VERSION ""

NS_ :

BS_:

BU_: L_DHRR_FD L_UWB_BLE_MST_FD L_UWB_RR_FD L_UWB_BLE_SLV_FD L_UWB_FR_FD L_ROA_FR_FD L_ROA_FD L_DHRL_FD L_UWB_TRNK_FD L_UWB_FRNK_FD L_EDT_FD L_UWB_FL_FD GW_BDC_FD L_UWB_RL_FD L_SAL_FD L_WPC_FD L_TPMS_FD L_DHL_FD L_DHR_FD

BO_ 2281701552 L_UWB_BLE_SLV_FD_20_200ms: 24 L_UWB_BLE_SLV_FD
 SG_ L_UWB_BLE_SLV_FD_Crc20Val : 0|16@1+ (1,0) [0|0] "0" Vector__XXX
 SG_ SLV_BLE_ConnectedDeviceInfo : 104|16@1+ (1,0) [0|0] ""  GW_BDC_FD,L_UWB_BLE_MST_FD
 SG_ SLV_BLE_Passive_ADV_State : 121|1@1+ (1,0) [0|0] ""  GW_BDC_FD,L_UWB_BLE_MST_FD
 SG_ SLV_BLE_NewDeviceConnetStatus : 122|2@1+ (1,0) [0|0] ""  GW_BDC_FD,L_UWB_BLE_MST_FD
 SG_ SLV_BLE_PairingResult : 124|2@1+ (1,0) [0|0] ""  GW_BDC_FD,L_UWB_BLE_MST_FD
 SG_ SLV_BLE_BondingDataStatus : 126|16@1+ (1,0) [0|0] ""  GW_BDC_FD,L_UWB_BLE_MST_FD
 SG_ SLV_BLE_InternalStatus : 144|8@1+ (1,0) [0|0] ""  L_EDT_FD,L_UWB_BLE_MST_FD
 SG_ L_UWB_BLE_SLV_FD_AlvCnt20Val : 16|8@1+ (1,0) [0|0] "0" Vector__XXX
 SG_ SLV_BLE_DK_ID1 : 24|8@1+ (1,0) [0|0] ""  GW_BDC_FD
 SG_ SLV_BLE_RSSI1 : 32|8@1+ (1,0) [0|0] ""  GW_BDC_FD
 SG_ SLV_BLE_DK_ID2 : 40|8@1+ (1,0) [0|0] ""  GW_BDC_FD
 SG_ SLV_BLE_RSSI2 : 48|8@1+ (1,0) [0|0] ""  GW_BDC_FD
 SG_ SLV_BLE_DK_ID3 : 56|8@1+ (1,0) [0|0] ""  GW_BDC_FD
 SG_ SLV_BLE_RSSI3 : 64|8@1+ (1,0) [0|0] ""  GW_BDC_FD
 SG_ SLV_BLE_DK_ID4 : 72|8@1+ (1,0) [0|0] ""  GW_BDC_FD
 SG_ SLV_BLE_RSSI4 : 80|8@1+ (1,0) [0|0] ""  GW_BDC_FD
 SG_ SLV_BLE_BTAddIRK_Update : 88|16@1+ (1,0) [0|0] ""  GW_BDC_FD,L_UWB_BLE_MST_FD

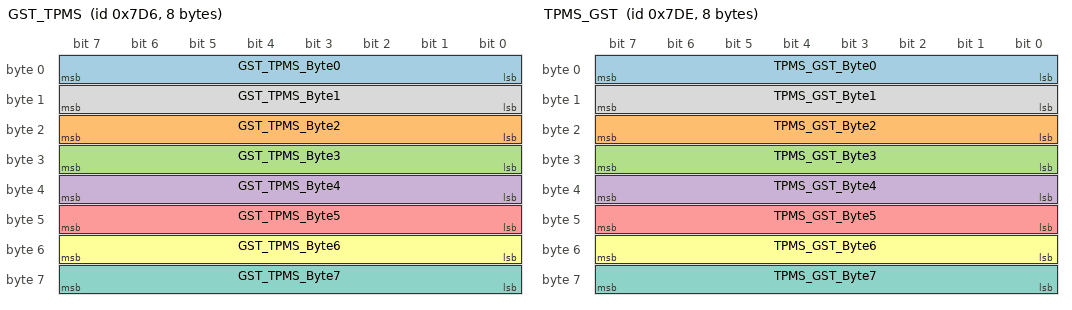
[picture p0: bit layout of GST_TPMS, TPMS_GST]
BO_ 2006 GST_TPMS: 8 GW_BDC_FD
 SG_ GST_TPMS_Byte0 : 0|8@1+ (1,0) [0|0] ""  L_TPMS_FD
 SG_ GST_TPMS_Byte2 : 16|8@1+ (1,0) [0|0] ""  L_TPMS_FD
 SG_ GST_TPMS_Byte3 : 24|8@1+ (1,0) [0|0] ""  L_TPMS_FD
 SG_ GST_TPMS_Byte4 : 32|8@1+ (1,0) [0|0] ""  L_TPMS_FD
 SG_ GST_TPMS_Byte5 : 40|8@1+ (1,0) [0|0] ""  L_TPMS_FD
 SG_ GST_TPMS_Byte6 : 48|8@1+ (1,0) [0|0] ""  L_TPMS_FD
 SG_ GST_TPMS_Byte7 : 56|8@1+ (1,0) [0|0] ""  L_TPMS_FD
 SG_ GST_TPMS_Byte1 : 8|8@1+ (1,0) [0|0] ""  L_TPMS_FD

BO_ 2014 TPMS_GST: 8 L_TPMS_FD
 SG_ TPMS_GST_Byte0 : 0|8@1+ (1,0) [0|0] ""  GW_BDC_FD
 SG_ TPMS_GST_Byte2 : 16|8@1+ (1,0) [0|0] ""  GW_BDC_FD
 SG_ TPMS_GST_Byte3 : 24|8@1+ (1,0) [0|0] ""  GW_BDC_FD
 SG_ TPMS_GST_Byte4 : 32|8@1+ (1,0) [0|0] ""  GW_BDC_FD
 SG_ TPMS_GST_Byte5 : 40|8@1+ (1,0) [0|0] ""  GW_BDC_FD
 SG_ TPMS_GST_Byte6 : 48|8@1+ (1,0) [0|0] ""  GW_BDC_FD
 SG_ TPMS_GST_Byte7 : 56|8@1+ (1,0) [0|0] ""  GW_BDC_FD
 SG_ TPMS_GST_Byte1 : 8|8@1+ (1,0) [0|0] ""  GW_BDC_FD

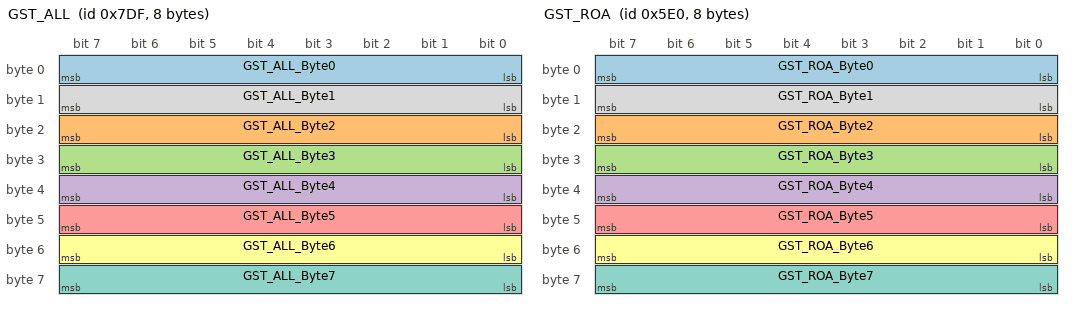
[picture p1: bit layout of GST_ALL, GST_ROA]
BO_ 2015 GST_ALL: 8 GW_BDC_FD
 SG_ GST_ALL_Byte0 : 0|8@1+ (1,0) [0|0] ""  L_DHL_FD,L_DHRL_FD,L_DHRR_FD,L_DHR_FD,L_ROA_FD,L_ROA_FR_FD,L_SAL_FD,L_UWB_BLE_MST_FD,L_WPC_FD
 SG_ GST_ALL_Byte2 : 16|8@1+ (1,0) [0|0] ""  L_DHL_FD,L_DHRL_FD,L_DHRR_FD,L_DHR_FD,L_ROA_FD,L_ROA_FR_FD,L_SAL_FD,L_UWB_BLE_MST_FD,L_WPC_FD
 SG_ GST_ALL_Byte3 : 24|8@1+ (1,0) [0|0] ""  L_DHL_FD,L_DHRL_FD,L_DHRR_FD,L_DHR_FD,L_ROA_FD,L_ROA_FR_FD,L_SAL_FD,L_UWB_BLE_MST_FD,L_WPC_FD
 SG_ GST_ALL_Byte4 : 32|8@1+ (1,0) [0|0] ""  L_DHL_FD,L_DHRL_FD,L_DHRR_FD,L_DHR_FD,L_ROA_FD,L_ROA_FR_FD,L_SAL_FD,L_UWB_BLE_MST_FD,L_WPC_FD
 SG_ GST_ALL_Byte5 : 40|8@1+ (1,0) [0|0] ""  L_DHL_FD,L_DHRL_FD,L_DHRR_FD,L_DHR_FD,L_ROA_FD,L_ROA_FR_FD,L_SAL_FD,L_UWB_BLE_MST_FD,L_WPC_FD
 SG_ GST_ALL_Byte6 : 48|8@1+ (1,0) [0|0] ""  L_DHL_FD,L_DHRL_FD,L_DHRR_FD,L_DHR_FD,L_ROA_FD,L_ROA_FR_FD,L_SAL_FD,L_UWB_BLE_MST_FD,L_WPC_FD
 SG_ GST_ALL_Byte7 : 56|8@1+ (1,0) [0|0] ""  L_DHL_FD,L_DHRL_FD,L_DHRR_FD,L_DHR_FD,L_ROA_FD,L_ROA_FR_FD,L_SAL_FD,L_UWB_BLE_MST_FD,L_WPC_FD
 SG_ GST_ALL_Byte1 : 8|8@1+ (1,0) [0|0] ""  L_DHL_FD,L_DHRL_FD,L_DHRR_FD,L_DHR_FD,L_ROA_FD,L_ROA_FR_FD,L_SAL_FD,L_UWB_BLE_MST_FD,L_WPC_FD

BO_ 2525339905 L_UWB_FL_FD_05_00ms: 32 L_UWB_FL_FD
 SG_ L_UWB_FL_FD_Crc5Val : 0|16@1+ (1,0) [0|0] "" Vector__XXX
 SG_ L_UWB_FL_FD_AlvCnt5Val : 16|8@1+ (1,0) [0|0] "" Vector__XXX
 SG_ FL_SWID_3_IVD_2 : 24|24@1+ (1,0) [0|0] ""  L_UWB_BLE_MST_FD

BO_ 2281701536 L_UWB_BLE_MST_FD_20_200ms: 24 L_UWB_BLE_MST_FD
 SG_ L_UWB_BLE_MST_FD_Crc20Val : 0|16@1+ (1,0) [0|0] "0" Vector__XXX
 SG_ MST_BLE_ConnectedDeviceInfo : 104|16@1+ (1,0) [0|0] ""  GW_BDC_FD,L_UWB_BLE_SLV_FD
 SG_ MST_BLE_OP_ADV_State : 120|1@1+ (1,0) [0|0] ""  GW_BDC_FD,L_UWB_BLE_SLV_FD
 SG_ MST_BLE_Passive_ADV_State : 121|1@1+ (1,0) [0|0] ""  GW_BDC_FD,L_UWB_BLE_SLV_FD
 SG_ MST_BLE_NewDeviceConnetStatus : 122|2@1+ (1,0) [0|0] ""  GW_BDC_FD,L_UWB_BLE_SLV_FD
 SG_ MST_BLE_PairingResult : 124|2@1+ (1,0) [0|0] ""  GW_BDC_FD,L_UWB_BLE_SLV_FD
 SG_ MST_BLE_BondingDataStatus : 126|16@1+ (1,0) [0|0] ""  GW_BDC_FD,L_UWB_BLE_SLV_FD
 SG_ MST_BLE_InternalStatus : 144|8@1+ (1,0) [0|0] ""  L_EDT_FD,L_UWB_BLE_SLV_FD
 SG_ MST_Vehicle_Info : 152|40@1+ (1,0) [0|0] ""  L_UWB_BLE_SLV_FD,L_UWB_FL_FD,L_UWB_FRNK_FD,L_UWB_FR_FD,L_UWB_RL_FD,L_UWB_RR_FD,L_UWB_TRNK_FD
 SG_ L_UWB_BLE_MST_FD_AlvCnt20Val : 16|8@1+ (1,0) [0|0] "0" Vector__XXX
 SG_ MST_BLE_DK_ID1 : 24|8@1+ (1,0) [0|0] ""  GW_BDC_FD
 SG_ MST_BLE_RSSI1 : 32|8@1+ (1,0) [0|0] ""  GW_BDC_FD
 SG_ MST_BLE_DK_ID2 : 40|8@1+ (1,0) [0|0] ""  GW_BDC_FD
 SG_ MST_BLE_RSSI2 : 48|8@1+ (1,0) [0|0] ""  GW_BDC_FD
 SG_ MST_BLE_DK_ID3 : 56|8@1+ (1,0) [0|0] ""  GW_BDC_FD
 SG_ MST_BLE_RSSI3 : 64|8@1+ (1,0) [0|0] ""  GW_BDC_FD
 SG_ MST_BLE_DK_ID4 : 72|8@1+ (1,0) [0|0] ""  GW_BDC_FD
 SG_ MST_BLE_RSSI4 : 80|8@1+ (1,0) [0|0] ""  GW_BDC_FD
 SG_ MST_BLE_BTAddIRK_Update : 88|16@1+ (1,0) [0|0] ""  GW_BDC_FD,L_UWB_BLE_SLV_FD

BO_ 426 CLU_01_20ms: 16 GW_BDC_FD
 SG_ CLU_Crc1Val : 0|16@1+ (1,0) [0|0] "" Vector__XXX
 SG_ CLU_FuelSenderRstReq : 110|2@1+ (1,0) [0|0] "" Vector__XXX
 SG_ CLU_AlvCnt1Val : 16|8@1+ (1,0) [0|0] "" Vector__XXX
 SG_ CLU_DtntOutSta : 28|2@1+ (1,0) [0|0] "" Vector__XXX
 SG_ CLU_SpdUnitTyp : 30|2@1+ (1,0) [0|0] "" Vector__XXX
 SG_ CLU_DisSpdDcmlVal : 32|2@1+ (0.125,0) [0|0] "" Vector__XXX
 SG_ CLU_SWRCCrsMainSwSta : 34|2@1+ (1,0) [0|0] "" Vector__XXX
 SG_ CLU_SWRCCrsSwSta : 36|3@1+ (1,0) [0|0] "" Vector__XXX
 SG_ CLU_SWRCLFASwSta : 39|2@1+ (1,0) [0|0] "" Vector__XXX
 SG_ CLU_SWRCSldMainSwSta : 41|2@1+ (1,0) [0|0] "" Vector__XXX
 SG_ CLU_RhstaLvlSta : 43|5@1+ (1,0) [0|0] "" Vector__XXX
 SG_ CLU_DisSpdVal : 48|10@1+ (0.5,0) [0|0] "km/h or MPH" Vector__XXX
 SG_ CLU_OKSwSta : 62|2@1+ (1,0) [0|0] "" Vector__XXX
 SG_ CLU_DisSpdVal_KPH : 64|9@1+ (1,0) [0|0] "km/h"  L_DHL_FD,L_DHRL_FD,L_DHRR_FD,L_DHR_FD,L_EDT_FD
 SG_ CLU_PwrAutoOffResetReq_HCU : 73|2@1+ (1,0) [0|0] "" Vector__XXX
 SG_ CLU_CUSTOMSta_NEW : 75|4@1+ (1,0) [0|0] "" Vector__XXX
 SG_ CLU_AutoBrightSta : 79|8@1+ (1,0) [0|0] "" Vector__XXX
 SG_ CLU_NotMinModeBrightSta : 87|8@1+ (1,0) [0|0] "" Vector__XXX
 SG_ CLU_FuelSenderResistVal : 97|13@1+ (0.1,0) [0|0] "" Vector__XXX

BO_ 2281701537 L_UWB_BLE_MST_FD_21_200ms: 24 L_UWB_BLE_MST_FD
 SG_ L_UWB_BLE_MST_FD_Crc21Val : 0|16@1+ (1,0) [0|0] "0" Vector__XXX
 SG_ MST_SW_MCU_Ver_Major : 104|8@1+ (1,0) [0|0] ""  L_EDT_FD
 SG_ MST_SW_MCU_Ver_Minor : 112|8@1+ (1,0) [0|0] ""  L_EDT_FD
 SG_ MST_SW_UWB_Ver_Major : 120|8@1+ (1,0) [0|0] ""  L_EDT_FD
 SG_ MST_SW_UWB_Ver_Minor : 128|8@1+ (1,0) [0|0] ""  L_EDT_FD
 SG_ MST_SW_BLE_Ver_Major : 136|8@1+ (1,0) [0|0] ""  L_EDT_FD
 SG_ MST_SW_BLE_Ver_Minor : 144|8@1+ (1,0) [0|0] ""  L_EDT_FD
 SG_ MST_UWB_DK_LocalizationStat : 152|2@1+ (1,0) [0|0] ""  GW_BDC_FD
 SG_ L_UWB_BLE_MST_FD_AlvCnt21Val : 16|8@1+ (1,0) [0|0] "0" Vector__XXX
 SG_ UWB_Applied_Info : 160|16@1+ (1,0) [0|0] ""  GW_BDC_FD
 SG_ MST_SW_UWB_2_Ver_Major : 176|8@1+ (1,0) [0|0] ""  L_EDT_FD
 SG_ MST_SW_UWB_2_Ver_Minor : 184|8@1+ (1,0) [0|0] ""  L_EDT_FD
 SG_ MST_UWB_Status1 : 24|4@1+ (1,0) [0|7] ""  GW_BDC_FD
 SG_ MST_UWB_Status2 : 28|4@1+ (1,0) [0|0] ""  GW_BDC_FD
 SG_ MST_UWB_Status3 : 32|4@1+ (1,0) [0|0] ""  GW_BDC_FD
 SG_ MST_UWB_Status4 : 36|4@1+ (1,0) [0|0] ""  GW_BDC_FD
 SG_ MST_UWB_Status5 : 40|4@1+ (1,0) [0|0] ""  GW_BDC_FD
 SG_ MST_UWB_Status6 : 44|4@1+ (1,0) [0|0] ""  GW_BDC_FD
 SG_ MST_UWB_Status7 : 48|4@1+ (1,0) [0|0] ""  GW_BDC_FD
 SG_ MST_UWB_Status8 : 52|4@1+ (1,0) [0|0] ""  GW_BDC_FD
 SG_ MST_UWB_Status9 : 56|4@1+ (1,0) [0|0] ""  GW_BDC_FD
 SG_ MST_UWB_Status10 : 60|4@1+ (1,0) [0|0] ""  GW_BDC_FD
 SG_ MST_UWB_Status11 : 64|4@1+ (1,0) [0|0] ""  GW_BDC_FD
 SG_ MST_UWB_Status12 : 68|4@1+ (1,0) [0|0] ""  GW_BDC_FD
 SG_ MST_UWB_Status13 : 72|4@1+ (1,0) [0|0] ""  GW_BDC_FD
 SG_ MST_UWB_Status14 : 76|4@1+ (1,0) [0|0] ""  GW_BDC_FD
 SG_ MST_UWB_Status15 : 80|4@1+ (1,0) [0|0] ""  GW_BDC_FD
 SG_ MST_UWB_Status16 : 84|4@1+ (1,0) [0|0] ""  GW_BDC_FD
 SG_ MST_HW_Ver_Major : 88|8@1+ (1,0) [0|7] ""  L_EDT_FD
 SG_ MST_HW_Ver_Minor : 96|8@1+ (1,0) [0|0] ""  L_EDT_FD

BO_ 1504 GST_ROA: 8 GW_BDC_FD
 SG_ GST_ROA_Byte0 : 0|8@1+ (1,0) [0|0] ""  L_ROA_FD
 SG_ GST_ROA_Byte2 : 16|8@1+ (1,0) [0|0] ""  L_ROA_FD
 SG_ GST_ROA_Byte3 : 24|8@1+ (1,0) [0|0] ""  L_ROA_FD
 SG_ GST_ROA_Byte4 : 32|8@1+ (1,0) [0|0] ""  L_ROA_FD
 SG_ GST_ROA_Byte5 : 40|8@1+ (1,0) [0|0] ""  L_ROA_FD
 SG_ GST_ROA_Byte6 : 48|8@1+ (1,0) [0|0] ""  L_ROA_FD
 SG_ GST_ROA_Byte7 : 56|8@1+ (1,0) [0|0] ""  L_ROA_FD
 SG_ GST_ROA_Byte1 : 8|8@1+ (1,0) [0|0] ""  L_ROA_FD

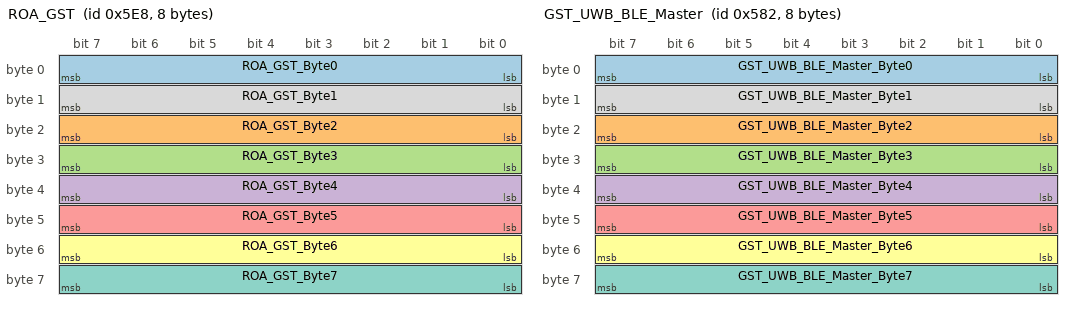
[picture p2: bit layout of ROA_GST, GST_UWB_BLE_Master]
BO_ 1512 ROA_GST: 8 L_ROA_FD
 SG_ ROA_GST_Byte0 : 0|8@1+ (1,0) [0|0] ""  GW_BDC_FD
 SG_ ROA_GST_Byte2 : 16|8@1+ (1,0) [0|0] ""  GW_BDC_FD
 SG_ ROA_GST_Byte3 : 24|8@1+ (1,0) [0|0] ""  GW_BDC_FD
 SG_ ROA_GST_Byte4 : 32|8@1+ (1,0) [0|0] ""  GW_BDC_FD
 SG_ ROA_GST_Byte5 : 40|8@1+ (1,0) [0|0] ""  GW_BDC_FD
 SG_ ROA_GST_Byte6 : 48|8@1+ (1,0) [0|0] ""  GW_BDC_FD
 SG_ ROA_GST_Byte7 : 56|8@1+ (1,0) [0|0] ""  GW_BDC_FD
 SG_ ROA_GST_Byte1 : 8|8@1+ (1,0) [0|0] ""  GW_BDC_FD

BO_ 2281701584 L_UWB_FR_FD_10_200ms: 24 L_UWB_FR_FD
 SG_ L_UWB_FR_FD_Crc10Val : 0|16@1+ (1,0) [0|0] "0" Vector__XXX
 SG_ UWB_FR_SW_MCU_Ver_Major : 104|8@1+ (1,0) [0|0] ""  L_UWB_BLE_MST_FD
 SG_ UWB_FR_SW_MCU_Ver_Minor : 112|8@1+ (1,0) [0|0] ""  L_UWB_BLE_MST_FD
 SG_ UWB_FR_SW_IC_Ver_Major : 120|8@1+ (1,0) [0|0] ""  L_UWB_BLE_MST_FD
 SG_ UWB_FR_SW_IC_Ver_Minor : 128|8@1+ (1,0) [0|0] ""  L_UWB_BLE_MST_FD
 SG_ UWB_FR_DTC : 136|8@1+ (1,0) [0|0] ""  L_UWB_BLE_MST_FD
 SG_ L_UWB_FR_FD_AlvCnt10Val : 16|8@1+ (1,0) [0|0] "0" Vector__XXX
 SG_ UWB_FR_Status1 : 24|4@1+ (1,0) [0|7] ""  GW_BDC_FD,L_UWB_BLE_MST_FD
 SG_ UWB_FR_Status2 : 28|4@1+ (1,0) [0|0] ""  GW_BDC_FD,L_UWB_BLE_MST_FD
 SG_ UWB_FR_Status3 : 32|4@1+ (1,0) [0|0] ""  GW_BDC_FD,L_UWB_BLE_MST_FD
 SG_ UWB_FR_Status4 : 36|4@1+ (1,0) [0|0] ""  GW_BDC_FD,L_UWB_BLE_MST_FD
 SG_ UWB_FR_Status5 : 40|4@1+ (1,0) [0|0] ""  GW_BDC_FD,L_UWB_BLE_MST_FD
 SG_ UWB_FR_Status6 : 44|4@1+ (1,0) [0|0] ""  GW_BDC_FD,L_UWB_BLE_MST_FD
 SG_ UWB_FR_Status7 : 48|4@1+ (1,0) [0|0] ""  GW_BDC_FD,L_UWB_BLE_MST_FD
 SG_ UWB_FR_Status8 : 52|4@1+ (1,0) [0|0] ""  GW_BDC_FD,L_UWB_BLE_MST_FD
 SG_ UWB_FR_Status9 : 56|4@1+ (1,0) [0|0] ""  GW_BDC_FD,L_UWB_BLE_MST_FD
 SG_ UWB_FR_Status10 : 60|4@1+ (1,0) [0|0] ""  GW_BDC_FD,L_UWB_BLE_MST_FD
 SG_ UWB_FR_Status11 : 64|4@1+ (1,0) [0|0] ""  GW_BDC_FD,L_UWB_BLE_MST_FD
 SG_ UWB_FR_Status12 : 68|4@1+ (1,0) [0|0] ""  GW_BDC_FD,L_UWB_BLE_MST_FD
 SG_ UWB_FR_Status13 : 72|4@1+ (1,0) [0|0] ""  GW_BDC_FD,L_UWB_BLE_MST_FD
 SG_ UWB_FR_Status14 : 76|4@1+ (1,0) [0|0] ""  GW_BDC_FD,L_UWB_BLE_MST_FD
 SG_ UWB_FR_Status15 : 80|4@1+ (1,0) [0|0] ""  GW_BDC_FD,L_UWB_BLE_MST_FD
 SG_ UWB_FR_Status16 : 84|4@1+ (1,0) [0|0] ""  GW_BDC_FD,L_UWB_BLE_MST_FD
 SG_ UWB_FR_HW_Ver_Major : 88|8@1+ (1,0) [0|0] ""  L_UWB_BLE_MST_FD
 SG_ UWB_FR_HW_Ver_Minor : 96|8@1+ (1,0) [0|0] ""  L_UWB_BLE_MST_FD

BO_ 2348810256 L_TPMS_FD_01_00ms: 32 L_TPMS_FD
 SG_ L_TPMS_FD_Crc1Val : 0|16@1+ (1,0) [0|0] "" Vector__XXX
 SG_ TPMS_TpsSnsrDataVal : 128|104@1+ (1,0) [0|0] ""  GW_BDC_FD
 SG_ L_TPMS_FD_AlvCnt1Val : 16|8@1+ (1,0) [0|0] "" Vector__XXX
 SG_ TPMS_SensorRssiVal : 232|8@1+ (1,0) [0|0] ""  GW_BDC_FD
 SG_ TPMS_LastTpsSnsrDataVal : 24|104@1+ (1,0) [0|0] ""  GW_BDC_FD

BO_ 2348810257 L_TPMS_FD_02_200ms: 16 L_TPMS_FD
 SG_ L_TPMS_FD_Crc2Val : 0|16@1+ (1,0) [0|0] "" Vector__XXX
 SG_ L_TPMS_FD_AlvCnt2Val : 16|8@1+ (1,0) [0|0] "" Vector__XXX
 SG_ TPMS_RficErrStatus : 24|2@1+ (1,0) [0|0] ""  GW_BDC_FD
 SG_ TPMS_NoiseRssiVal : 34|8@1+ (1,0) [0|0] ""  GW_BDC_FD

BO_ 2533736449 L_UWB_TRNK_FD_04_00ms: 32 L_UWB_TRNK_FD
 SG_ L_UWB_TRNK_FD_Crc4Val : 0|16@1+ (1,0) [0|0] "" Vector__XXX
 SG_ L_UWB_TRNK_FD_AlvCnt4Val : 16|8@1+ (1,0) [0|0] "" Vector__XXX
 SG_ TRNK_SWID_3_IVD_1 : 24|232@1+ (1,0) [0|0] ""  L_UWB_BLE_MST_FD

BO_ 2529538049 L_UWB_RL_FD_04_00ms: 32 L_UWB_RL_FD
 SG_ L_UWB_RL_FD_Crc4Val : 0|16@1+ (1,0) [0|0] "" Vector__XXX
 SG_ L_UWB_RL_FD_AlvCnt4Val : 16|8@1+ (1,0) [0|0] "" Vector__XXX
 SG_ RL_SWID_3_IVD_1 : 24|232@1+ (1,0) [0|0] ""  L_UWB_BLE_MST_FD

BO_ 1410 GST_UWB_BLE_Master: 8 GW_BDC_FD
 SG_ GST_UWB_BLE_Master_Byte0 : 0|8@1+ (1,0) [0|0] ""  L_UWB_BLE_MST_FD
 SG_ GST_UWB_BLE_Master_Byte2 : 16|8@1+ (1,0) [0|0] ""  L_UWB_BLE_MST_FD
 SG_ GST_UWB_BLE_Master_Byte3 : 24|8@1+ (1,0) [0|0] ""  L_UWB_BLE_MST_FD
 SG_ GST_UWB_BLE_Master_Byte4 : 32|8@1+ (1,0) [0|0] ""  L_UWB_BLE_MST_FD
 SG_ GST_UWB_BLE_Master_Byte5 : 40|8@1+ (1,0) [0|0] ""  L_UWB_BLE_MST_FD
 SG_ GST_UWB_BLE_Master_Byte6 : 48|8@1+ (1,0) [0|0] ""  L_UWB_BLE_MST_FD
 SG_ GST_UWB_BLE_Master_Byte7 : 56|8@1+ (1,0) [0|0] ""  L_UWB_BLE_MST_FD
 SG_ GST_UWB_BLE_Master_Byte1 : 8|8@1+ (1,0) [0|0] ""  L_UWB_BLE_MST_FD

BO_ 2281701568 L_UWB_FL_FD_10_200ms: 24 L_UWB_FL_FD
 SG_ L_UWB_FL_FD_Crc10Val : 0|16@1+ (1,0) [0|0] "0" Vector__XXX
 SG_ UWB_FL_SW_MCU_Ver_Major : 104|8@1+ (1,0) [0|0] ""  L_UWB_BLE_MST_FD
 SG_ UWB_FL_SW_MCU_Ver_Minor : 112|8@1+ (1,0) [0|0] ""  L_UWB_BLE_MST_FD
 SG_ UWB_FL_SW_IC_Ver_Major : 120|8@1+ (1,0) [0|0] ""  L_UWB_BLE_MST_FD
 SG_ UWB_FL_SW_IC_Ver_Minor : 128|8@1+ (1,0) [0|0] ""  L_UWB_BLE_MST_FD
 SG_ UWB_FL_DTC : 136|8@1+ (1,0) [0|0] ""  L_UWB_BLE_MST_FD
 SG_ L_UWB_FL_FD_AlvCnt10Val : 16|8@1+ (1,0) [0|0] "0" Vector__XXX
 SG_ UWB_FL_Status1 : 24|4@1+ (1,0) [0|7] ""  GW_BDC_FD,L_UWB_BLE_MST_FD
 SG_ UWB_FL_Status2 : 28|4@1+ (1,0) [0|0] ""  GW_BDC_FD,L_UWB_BLE_MST_FD
 SG_ UWB_FL_Status3 : 32|4@1+ (1,0) [0|0] ""  GW_BDC_FD,L_UWB_BLE_MST_FD
 SG_ UWB_FL_Status4 : 36|4@1+ (1,0) [0|0] ""  GW_BDC_FD,L_UWB_BLE_MST_FD
 SG_ UWB_FL_Status5 : 40|4@1+ (1,0) [0|0] ""  GW_BDC_FD,L_UWB_BLE_MST_FD
 SG_ UWB_FL_Status6 : 44|4@1+ (1,0) [0|0] ""  GW_BDC_FD,L_UWB_BLE_MST_FD
 SG_ UWB_FL_Status7 : 48|4@1+ (1,0) [0|0] ""  GW_BDC_FD,L_UWB_BLE_MST_FD
 SG_ UWB_FL_Status8 : 52|4@1+ (1,0) [0|0] ""  GW_BDC_FD,L_UWB_BLE_MST_FD
 SG_ UWB_FL_Status9 : 56|4@1+ (1,0) [0|0] ""  GW_BDC_FD,L_UWB_BLE_MST_FD
 SG_ UWB_FL_Status10 : 60|4@1+ (1,0) [0|0] ""  GW_BDC_FD,L_UWB_BLE_MST_FD
 SG_ UWB_FL_Status11 : 64|4@1+ (1,0) [0|0] ""  GW_BDC_FD,L_UWB_BLE_MST_FD
 SG_ UWB_FL_Status12 : 68|4@1+ (1,0) [0|0] ""  GW_BDC_FD,L_UWB_BLE_MST_FD
 SG_ UWB_FL_Status13 : 72|4@1+ (1,0) [0|0] ""  GW_BDC_FD,L_UWB_BLE_MST_FD
 SG_ UWB_FL_Status14 : 76|4@1+ (1,0) [0|0] ""  GW_BDC_FD,L_UWB_BLE_MST_FD
 SG_ UWB_FL_Status15 : 80|4@1+ (1,0) [0|0] ""  GW_BDC_FD,L_UWB_BLE_MST_FD
 SG_ UWB_FL_Status16 : 84|4@1+ (1,0) [0|0] ""  GW_BDC_FD,L_UWB_BLE_MST_FD
 SG_ UWB_FL_HW_Ver_Major : 88|8@1+ (1,0) [0|0] ""  L_UWB_BLE_MST_FD
 SG_ UWB_FL_HW_Ver_Minor : 96|8@1+ (1,0) [0|0] ""  L_UWB_BLE_MST_FD

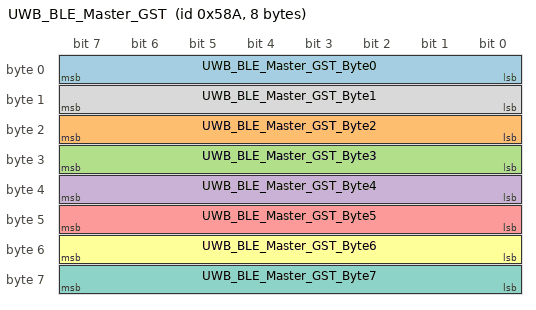
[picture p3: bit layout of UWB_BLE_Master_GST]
BO_ 1418 UWB_BLE_Master_GST: 8 L_UWB_BLE_MST_FD
 SG_ UWB_BLE_Master_GST_Byte0 : 0|8@1+ (1,0) [0|0] ""  GW_BDC_FD
 SG_ UWB_BLE_Master_GST_Byte2 : 16|8@1+ (1,0) [0|0] ""  GW_BDC_FD
 SG_ UWB_BLE_Master_GST_Byte3 : 24|8@1+ (1,0) [0|0] ""  GW_BDC_FD
 SG_ UWB_BLE_Master_GST_Byte4 : 32|8@1+ (1,0) [0|0] ""  GW_BDC_FD
 SG_ UWB_BLE_Master_GST_Byte5 : 40|8@1+ (1,0) [0|0] ""  GW_BDC_FD
 SG_ UWB_BLE_Master_GST_Byte6 : 48|8@1+ (1,0) [0|0] ""  GW_BDC_FD
 SG_ UWB_BLE_Master_GST_Byte7 : 56|8@1+ (1,0) [0|0] ""  GW_BDC_FD
 SG_ UWB_BLE_Master_GST_Byte1 : 8|8@1+ (1,0) [0|0] ""  GW_BDC_FD

BO_ 992 PDC_FD_01_200ms: 24 GW_BDC_FD
 SG_ PDC_FD_Crc1Val : 0|16@1+ (1,0) [0|0] "" Vector__XXX
 SG_ C_3rdRCSeatBeltSW_Copy_0 : 100|1@1+ (1,0) [0|0] "" Vector__XXX
 SG_ C_3rdRRSeatBeltSW_Copy_0 : 101|1@1+ (1,0) [0|0] "" Vector__XXX
 SG_ C_1stCTRSeatBeltSW_Copy_0 : 102|1@1+ (1,0) [0|0] "" Vector__XXX
 SG_ Warn_DrvStOccSta_Copy_0 : 103|3@1+ (1,0) [0|0] "" Vector__XXX
 SG_ DPDMat_HDPSpprtSWVer_Copy_0 : 106|5@1+ (1,0) [0|0] "" Vector__XXX
 SG_ Warn_PassStOccSta_Copy_0 : 111|2@1+ (1,0) [0|0] "" Vector__XXX
 SG_ Warn_RrLftSBRMATSwSta_Copy_0 : 113|2@1+ (1,0) [0|0] "" Vector__XXX
 SG_ Warn_RrRhtSBRMATSwSta_Copy_0 : 115|2@1+ (1,0) [0|0] "" Vector__XXX
 SG_ C_3rdRLSBRMatSw_Copy_0 : 117|1@1+ (1,0) [0|0] "" Vector__XXX
 SG_ C_3rdRRSBRMatSw_Copy_0 : 118|1@1+ (1,0) [0|0] "" Vector__XXX
 SG_ C_1stCTRSBRMatSw_Copy_0 : 119|1@1+ (1,0) [0|0] "" Vector__XXX
 SG_ StrWhlWrmrSwState_Copy_0 : 120|2@1+ (1,0) [0|0] "" Vector__XXX
 SG_ StrWhlWrmrFlModDetail_Copy_0 : 122|3@1+ (1,0) [0|0] "" Vector__XXX
 SG_ FrHtdGlsSwState_Copy_0 : 125|2@1+ (1,0) [0|0] "" Vector__XXX
 SG_ RrGlsHtSwState_Copy_0 : 127|2@1+ (1,0) [0|0] "" Vector__XXX
 SG_ RLChldLkLatchSwState_Copy_0 : 129|2@1+ (1,0) [0|0] "" Vector__XXX
 SG_ RRChldLkLatchSwState_Copy_0 : 131|2@1+ (1,0) [0|0] "" Vector__XXX
 SG_ ChildLock_ActnFlSta_Copy_0 : 133|2@1+ (1,0) [0|0] "" Vector__XXX
 SG_ DoorLock_LkOutSta_Copy_0 : 135|2@1+ (1,0) [0|0] "" Vector__XXX
 SG_ VSAutoDrLkRetryFailSta_Copy_0 : 137|2@1+ (1,0) [0|0] "" Vector__XXX
 SG_ Trunk_TrnkTlgtOutReleaseSwSta_Co : 139|2@1+ (1,0) [0|0] "" Vector__XXX
 SG_ Trunk_TrnkInReleaseSwSta_Copy_0 : 141|2@1+ (1,0) [0|0] "" Vector__XXX
 SG_ Trunk_GlvBxTrnkLkSwSta_Copy_0 : 143|2@1+ (1,0) [0|0] "" Vector__XXX
 SG_ Trunk_TrnkTlgtSwSta_Copy_0 : 145|2@1+ (1,0) [0|0] ""  L_UWB_BLE_MST_FD
 SG_ Trunk_TlgtFullOpnSwSta_Copy_0 : 147|2@1+ (1,0) [0|0] "" Vector__XXX
 SG_ Trunk_TrnkTlgtReleaseRlySta_Copy : 149|2@1+ (1,0) [0|0] "" Vector__XXX
 SG_ FrtWiper_ParkingSwState : 151|2@1+ (1,0) [0|0] "" Vector__XXX
 SG_ PDC_TlgtUnLkSta : 153|2@1+ (1,0) [0|0] "" Vector__XXX
 SG_ PDC_PSDPwrModeOffSwSta : 155|2@1+ (1,0) [0|0] "" Vector__XXX
 SG_ PDC_FuelDrOpenSta : 157|2@1+ (1,0) [0|0] "" Vector__XXX
 SG_ PDC_FD_AlvCnt1Val : 16|8@1+ (1,0) [0|0] "" Vector__XXX
 SG_ OBCWakeupDrLock_Copy_0 : 161|2@1+ (1,0) [0|0] "" Vector__XXX
 SG_ OBCWakeupDrUnlock_Copy_0 : 163|2@1+ (1,0) [0|0] "%" Vector__XXX
 SG_ Trunk_BgtOpnHzrdReq_Copy_0 : 165|2@1+ (1,0) [0|0] "" Vector__XXX
 SG_ Trunk_BgtOpnBzrReq_Copy_0 : 167|2@1+ (1,0) [0|0] "" Vector__XXX
 SG_ IGN3State : 169|2@1+ (1,0) [0|0] "" Vector__XXX
 SG_ IGN3State_By_BMS : 171|2@1+ (1,0) [0|0] "" Vector__XXX
 SG_ IGN3State_By_VCMS_HMU : 173|2@1+ (1,0) [0|0] "" Vector__XXX
 SG_ IGN3State_By_AfterBlow : 175|2@1+ (1,0) [0|0] "" Vector__XXX
 SG_ IGN3State_By_Bat_Copy_0 : 177|2@1+ (1,0) [0|0] "" Vector__XXX
 SG_ IGN3State_By_VCU_HCU_FCU : 179|2@1+ (1,0) [0|0] "" Vector__XXX
 SG_ IGN3State_By_HU : 181|2@1+ (1,0) [0|0] "" Vector__XXX
 SG_ IGN3CutOffState : 183|3@1+ (1,0) [0|0] "" Vector__XXX
 SG_ SeatBeltSwSta_Drv_Copy_0 : 24|2@1+ (1,0) [0|0] "" Vector__XXX
 SG_ SeatBeltSwSta_1stCtr_Copy_0 : 26|2@1+ (1,0) [0|0] "" Vector__XXX
 SG_ SeatBeltSwSta_Asst_Copy_0 : 28|2@1+ (1,0) [0|0] "" Vector__XXX
 SG_ SeatBeltSwSta_2ndLft_Copy_0 : 30|2@1+ (1,0) [0|0] "" Vector__XXX
 SG_ SeatBeltSwSta_2ndCtr_Copy_0 : 32|2@1+ (1,0) [0|0] "" Vector__XXX
 SG_ SeatBeltSwSta_2ndRt_Copy_0 : 34|2@1+ (1,0) [0|0] "" Vector__XXX
 SG_ SeatBeltSwSta_3rdLft_Copy_0 : 36|2@1+ (1,0) [0|0] "" Vector__XXX
 SG_ SeatBeltSwSta_3rdCtr_Copy_0 : 38|2@1+ (1,0) [0|0] "" Vector__XXX
 SG_ SeatBeltSwSta_3rdRt_Copy_0 : 40|2@1+ (1,0) [0|0] "" Vector__XXX
 SG_ SeatBelt4th_InstallInfo_Copy_0 : 42|3@1+ (1,0) [0|0] "" Vector__XXX
 SG_ PDCex_CurtainOpt : 45|2@1+ (1,0) [0|0] "" Vector__XXX
 SG_ Reprogram_State_PDC2 : 47|2@1+ (1,0) [0|0] "" Vector__XXX
 SG_ Warn_RrCTRSBRMATSwSta : 56|2@1+ (1,0) [0|0] "" Vector__XXX
 SG_ C_3rdRCSBRMatSw : 58|1@1+ (1,0) [0|0] "" Vector__XXX
 SG_ DriveTypeOption_Copy_0 : 64|2@1+ (1,0) [0|0] ""  L_UWB_BLE_MST_FD
 SG_ AutoLtOpt_Copy_0 : 66|2@1+ (1,0) [0|0] "" Vector__XXX
 SG_ HLmpLoHiOptLtSrcTyp_Copy_0 : 68|3@1+ (1,0) [0|0] "" Vector__XXX
 SG_ C_StrgWhlHeatingOpt_Copy_0 : 71|2@1+ (1,0) [0|0] "" Vector__XXX
 SG_ C_StrgWhlHeatingSWInf_Copy_0 : 73|2@1+ (1,0) [0|0] "" Vector__XXX
 SG_ ICU_MtGearPosRSta_Copy_0 : 75|2@1+ (1,0) [0|0] "" Vector__XXX
 SG_ C_AutoLeverManualSW_Copy_0 : 77|2@1+ (1,0) [0|0] "" Vector__XXX
 SG_ Warn_HoodSwMemorySta_Copy_0 : 79|2@1+ (1,0) [0|0] "" Vector__XXX
 SG_ Warn_PrkngBrkSwSta_Copy_0 : 81|2@1+ (1,0) [0|0] "" Vector__XXX
 SG_ PrkngBrkNotchSwState_Copy_0 : 83|2@1+ (1,0) [0|0] "" Vector__XXX
 SG_ Warn_BrkFldSwSta_Copy_0 : 85|2@1+ (1,0) [0|0] "" Vector__XXX
 SG_ Warn_WshrFldSwSta_Copy_0 : 87|2@1+ (1,0) [0|0] "" Vector__XXX
 SG_ Warn_DrvStBltSwSta_Copy_0 : 89|2@1+ (1,0) [0|0] "" Vector__XXX
 SG_ Warn_AsstStBltSwSta_Copy_0 : 91|2@1+ (1,0) [0|0] "" Vector__XXX
 SG_ Warn_RrLftStBltSwSta_Copy_0 : 93|2@1+ (1,0) [0|0] "" Vector__XXX
 SG_ Warn_RrCtrStBltSwSta_Copy_0 : 95|2@1+ (1,0) [0|0] "" Vector__XXX
 SG_ Warn_RrRtStBltSwSta_Copy_0 : 97|2@1+ (1,0) [0|0] "" Vector__XXX
 SG_ C_3rdRLSeatBeltSW_Copy_0 : 99|1@1+ (1,0) [0|0] "" Vector__XXX

CM_ BO_ 2281701552 "[PE] Periodic and On Event";
CM_ SG_ 2281701552 L_UWB_BLE_SLV_FD_Crc20Val "L_UWB_BLE_SLV_FD_CyclicRedundancyCheck20Value";
CM_ SG_ 2281701552 SLV_BLE_ConnectedDeviceInfo "BLE Connected Deivces/ID";
CM_ SG_ 2281701552 SLV_BLE_Passive_ADV_State "BLE Passive EN/ST Advertising State";
CM_ SG_ 2281701552 SLV_BLE_NewDeviceConnetStatus "Not Paired Device Connection Status";
CM_ SG_ 2281701552 SLV_BLE_PairingResult "Slave BLE New Device Pairing Result";
CM_ SG_ 2281701552 SLV_BLE_BondingDataStatus "Slave BLE Boding Data Status";
CM_ SG_ 2281701552 SLV_BLE_InternalStatus "Slave BLE Internal Status Data";
CM_ SG_ 2281701552 L_UWB_BLE_SLV_FD_AlvCnt20Val "L_UWB_BLE_SLV_FD_AliveCounter20Value";
CM_ SG_ 2281701552 SLV_BLE_DK_ID1 "BLE Connection 1 DK ID";
CM_ SG_ 2281701552 SLV_BLE_RSSI1 "BLE Connection 1 RSSI";
CM_ SG_ 2281701552 SLV_BLE_DK_ID2 "BLE Connection 2 DK ID";
CM_ SG_ 2281701552 SLV_BLE_RSSI2 "BLE Connection 2 RSSI";
CM_ SG_ 2281701552 SLV_BLE_DK_ID3 "BLE Connection 3 DK ID";
CM_ SG_ 2281701552 SLV_BLE_RSSI3 "BLE Connection 3 RSSI";
CM_ SG_ 2281701552 SLV_BLE_DK_ID4 "BLE Connection 4 DK ID";
CM_ SG_ 2281701552 SLV_BLE_RSSI4 "BLE Connection 4 RSSI";
CM_ SG_ 2281701552 SLV_BLE_BTAddIRK_Update "BTAddress IRK Update Signal";
CM_ BO_ 2006 "[TP] Transport Protocol";
CM_ BO_ 2014 "[TP] Transport Protocol";
CM_ BO_ 2015 "[TP] Transport Protocol";
CM_ BO_ 2525339905 "[EW] On Event and On Write";
CM_ SG_ 2525339905 L_UWB_FL_FD_Crc5Val "L_UWB_FL_FD_CyclicRedundancyCheck5Value";
CM_ SG_ 2525339905 L_UWB_FL_FD_AlvCnt5Val "L_UWB_FL_FD_AliveCounter5Value";
CM_ SG_ 2525339905 FL_SWID_3_IVD_2 "UWB FL SW Unit 3 IVD2";
CM_ BO_ 2281701536 "[PE] Periodic and On Event";
CM_ SG_ 2281701536 L_UWB_BLE_MST_FD_Crc20Val "L_UWB_BLE_MST_FD_CyclicRedundancyCheck20Value";
CM_ SG_ 2281701536 MST_BLE_ConnectedDeviceInfo "BLE Connected Deivces/ID";
CM_ SG_ 2281701536 MST_BLE_OP_ADV_State "BLE Owner Pairing Advertising State";
CM_ SG_ 2281701536 MST_BLE_Passive_ADV_State "BLE Passive EN/ST Advertising State";
CM_ SG_ 2281701536 MST_BLE_NewDeviceConnetStatus "Not Paired Device Connection Status";
CM_ SG_ 2281701536 MST_BLE_PairingResult "BLE New Device Pairing Result";
CM_ SG_ 2281701536 MST_BLE_BondingDataStatus "Master BLE Bonding Data Status";
CM_ SG_ 2281701536 MST_BLE_InternalStatus "Master BLE Internal Status Data";
CM_ SG_ 2281701536 MST_Vehicle_Info "UWB BLE Master information to prevent incorrect mounting of UWB anchor";
CM_ SG_ 2281701536 L_UWB_BLE_MST_FD_AlvCnt20Val "L_UWB_BLE_MST_FD_AliveCounter20Value";
CM_ SG_ 2281701536 MST_BLE_DK_ID1 "BLE Connection 1 DK ID";
CM_ SG_ 2281701536 MST_BLE_RSSI1 "BLE Connection 1 RSSI";
CM_ SG_ 2281701536 MST_BLE_DK_ID2 "BLE Connection 2 DK ID";
CM_ SG_ 2281701536 MST_BLE_RSSI2 "BLE Connection 2 RSSI";
CM_ SG_ 2281701536 MST_BLE_DK_ID3 "BLE Connection 3 DK ID";
CM_ SG_ 2281701536 MST_BLE_RSSI3 "BLE Connection 3 RSSI";
CM_ SG_ 2281701536 MST_BLE_DK_ID4 "BLE Connection 4 DK ID";
CM_ SG_ 2281701536 MST_BLE_RSSI4 "BLE Connection 4 RSSI";
CM_ SG_ 2281701536 MST_BLE_BTAddIRK_Update "BTAddress IRK Update Signal";
CM_ BO_ 426 "[P] Periodic";
CM_ SG_ 426 CLU_Crc1Val "CLU_CyclicRedundancyCheck1Value";
CM_ SG_ 426 CLU_FuelSenderRstReq "Reset request signal for ICV fuel-sender";
CM_ SG_ 426 CLU_AlvCnt1Val "CLU_AliveCounter1Value";
CM_ SG_ 426 CLU_DtntOutSta "CLU_DetentOutStatus";
CM_ SG_ 426 CLU_SpdUnitTyp "CLU_SpeedUnitType";
CM_ SG_ 426 CLU_DisSpdDcmlVal "CLU_DisplaySpeedDecimalValue";
CM_ SG_ 426 CLU_SWRCCrsMainSwSta "CLU_SWRCCrsMainSwSta";
CM_ SG_ 426 CLU_SWRCCrsSwSta "CLU_SWRCCrsSwSta";
CM_ SG_ 426 CLU_SWRCLFASwSta "SWRC_LFASwitchStatus";
CM_ SG_ 426 CLU_SWRCSldMainSwSta "SWRC_SpeedLimiterMainSwitchStatus";
CM_ SG_ 426 CLU_RhstaLvlSta "CLU_RheostatLevelStatus";
CM_ SG_ 426 CLU_DisSpdVal "CLU_DisplaySpeedValue";
CM_ SG_ 426 CLU_OKSwSta "OK Switch On/Off State";
CM_ SG_ 426 CLU_DisSpdVal_KPH "CLU_DisplaySpeedValue_KPH";
CM_ SG_ 426 CLU_PwrAutoOffResetReq_HCU "reset power auto off time";
CM_ SG_ 426 CLU_AutoBrightSta "CLU_AutoBrightStatus";
CM_ SG_ 426 CLU_NotMinModeBrightSta "CLU_NotMinimumModeBrightStaus";
CM_ SG_ 426 CLU_FuelSenderResistVal "This is the resistance data come from fuel sender.";
CM_ BO_ 2281701537 "[PE] Periodic and On Event";
CM_ SG_ 2281701537 L_UWB_BLE_MST_FD_Crc21Val "L_UWB_BLE_MST_FD_CyclicRedundancyCheck21Value";
CM_ SG_ 2281701537 MST_SW_MCU_Ver_Major "Master SW MCU Version Major";
CM_ SG_ 2281701537 MST_SW_MCU_Ver_Minor "Master SW MCU Version Minor";
CM_ SG_ 2281701537 MST_SW_UWB_Ver_Major "Master SW UWB Version Major";
CM_ SG_ 2281701537 MST_SW_UWB_Ver_Minor "Master SW UWB Version Minor";
CM_ SG_ 2281701537 MST_SW_BLE_Ver_Major "Master SW BLE Version Major";
CM_ SG_ 2281701537 MST_SW_BLE_Ver_Minor "Master SW BLE Version Minor";
CM_ SG_ 2281701537 MST_UWB_DK_LocalizationStat "Digital key localization status";
CM_ SG_ 2281701537 L_UWB_BLE_MST_FD_AlvCnt21Val "L_UWB_BLE_MST_FD_AliveCounter21Value";
CM_ SG_ 2281701537 UWB_Applied_Info "Information on UWB Applied in vehicle";
CM_ SG_ 2281701537 MST_SW_UWB_2_Ver_Major "Master SW UWB_2 Version Major";
CM_ SG_ 2281701537 MST_SW_UWB_2_Ver_Minor "Master SW UWB_2 Version Minor";
CM_ SG_ 2281701537 MST_UWB_Status1 "UWB_MASTER Processing Status 1";
CM_ SG_ 2281701537 MST_UWB_Status2 "UWB_MASTER Processing Status 2";
CM_ SG_ 2281701537 MST_UWB_Status3 "UWB_MASTER Processing Status 3";
CM_ SG_ 2281701537 MST_UWB_Status4 "UWB_MASTER Processing Status 4";
CM_ SG_ 2281701537 MST_UWB_Status5 "UWB_MASTER Processing Status 5";
CM_ SG_ 2281701537 MST_UWB_Status6 "UWB_MASTER Processing Status 6";
CM_ SG_ 2281701537 MST_UWB_Status7 "UWB_MASTER Processing Status 7";
CM_ SG_ 2281701537 MST_UWB_Status8 "UWB_MASTER Processing Status 8";
CM_ SG_ 2281701537 MST_UWB_Status9 "UWB_MASTER Processing Status 9";
CM_ SG_ 2281701537 MST_UWB_Status10 "UWB_MASTER Processing Status 10";
CM_ SG_ 2281701537 MST_UWB_Status11 "UWB_MASTER Processing Status 11";
CM_ SG_ 2281701537 MST_UWB_Status12 "UWB_MASTER Processing Status 12";
CM_ SG_ 2281701537 MST_UWB_Status13 "UWB_MASTER Processing Status 13";
CM_ SG_ 2281701537 MST_UWB_Status14 "UWB_MASTER Processing Status 14";
CM_ SG_ 2281701537 MST_UWB_Status15 "UWB_MASTER Processing Status 15";
CM_ SG_ 2281701537 MST_UWB_Status16 "UWB_MASTER Processing Status 16";
CM_ SG_ 2281701537 MST_HW_Ver_Major "Master HW Version Major";
CM_ SG_ 2281701537 MST_HW_Ver_Minor "Master HW Version Minor";
CM_ BO_ 1504 "[TP] Transport Protocol";
CM_ BO_ 1512 "[TP] Transport Protocol";
CM_ BO_ 2281701584 "[PE] Periodic and On Event";
CM_ SG_ 2281701584 L_UWB_FR_FD_Crc10Val "L_UWB_FR_FD_CyclicRedundancyCheck10Value";
CM_ SG_ 2281701584 UWB_FR_SW_MCU_Ver_Major "UWB FR SW MCU Version Major";
CM_ SG_ 2281701584 UWB_FR_SW_MCU_Ver_Minor "UWB FR SW MCU Version Minor";
CM_ SG_ 2281701584 UWB_FR_SW_IC_Ver_Major "UWB FR SW IC Version Major";
CM_ SG_ 2281701584 UWB_FR_SW_IC_Ver_Minor "UWB FR SW IC Version Minor";
CM_ SG_ 2281701584 UWB_FR_DTC "UWB FR DTC Data";
CM_ SG_ 2281701584 L_UWB_FR_FD_AlvCnt10Val "L_UWB_FR_FD_AliveCounter10Value";
CM_ SG_ 2281701584 UWB_FR_Status1 "UWB_FR Processing Status 1";
CM_ SG_ 2281701584 UWB_FR_Status2 "UWB_FR Processing Status 2";
CM_ SG_ 2281701584 UWB_FR_Status3 "UWB_FR Processing Status 3";
CM_ SG_ 2281701584 UWB_FR_Status4 "UWB_FR Processing Status 4";
CM_ SG_ 2281701584 UWB_FR_Status5 "UWB_FR Processing Status 5";
CM_ SG_ 2281701584 UWB_FR_Status6 "UWB_FR Processing Status 6";
CM_ SG_ 2281701584 UWB_FR_Status7 "UWB_FR Processing Status 7";
CM_ SG_ 2281701584 UWB_FR_Status8 "UWB_FR Processing Status 8";
CM_ SG_ 2281701584 UWB_FR_Status9 "UWB_FR Processing Status 9";
CM_ SG_ 2281701584 UWB_FR_Status10 "UWB_FR Processing Status 10";
CM_ SG_ 2281701584 UWB_FR_Status11 "UWB_FR Processing Status 11";
CM_ SG_ 2281701584 UWB_FR_Status12 "UWB_FR Processing Status 12";
CM_ SG_ 2281701584 UWB_FR_Status13 "UWB_FR Processing Status 13";
CM_ SG_ 2281701584 UWB_FR_Status14 "UWB_FR Processing Status 14";
CM_ SG_ 2281701584 UWB_FR_Status15 "UWB_FR Processing Status 15";
CM_ SG_ 2281701584 UWB_FR_Status16 "UWB_FR Processing Status 16";
CM_ SG_ 2281701584 UWB_FR_HW_Ver_Major "UWB FR HW Version Major";
CM_ SG_ 2281701584 UWB_FR_HW_Ver_Minor "UWB FR HW Version Minor";
CM_ BO_ 2348810256 "[EC] On Event and On Change";
CM_ SG_ 2348810256 L_TPMS_FD_Crc1Val "L_TPMS_FD_CyclicRedundancyCheck1Value";
CM_ SG_ 2348810256 TPMS_TpsSnsrDataVal "TPMS sensor data";
CM_ SG_ 2348810256 L_TPMS_FD_AlvCnt1Val "L_TPMS_FD_AliveCounter1Value";
CM_ SG_ 2348810256 TPMS_SensorRssiVal "Sensor RSSI value";
CM_ SG_ 2348810256 TPMS_LastTpsSnsrDataVal "Final received TPS RF signal(FL/FR/RL/RR)";
CM_ BO_ 2348810257 "[PE] Periodic and On Event";
CM_ SG_ 2348810257 L_TPMS_FD_Crc2Val "L_TPMS_FD_CyclicRedundancyCheck2Value";
CM_ SG_ 2348810257 L_TPMS_FD_AlvCnt2Val "L_TPMS_FD_AliveCounter2Value";
CM_ SG_ 2348810257 TPMS_RficErrStatus "RF IC Fail status";
CM_ SG_ 2348810257 TPMS_NoiseRssiVal "Noise RSSI value";
CM_ BO_ 2533736449 "[EW] On Event and On Write";
CM_ SG_ 2533736449 L_UWB_TRNK_FD_Crc4Val "L_UWB_TRNK_FD_CyclicRedundancyCheck4Value";
CM_ SG_ 2533736449 L_UWB_TRNK_FD_AlvCnt4Val "L_UWB_TRNK_FD_AliveCounter4Value";
CM_ SG_ 2533736449 TRNK_SWID_3_IVD_1 "UWB TRNK SW Unit 3 IVD1";
CM_ BO_ 2529538049 "[EW] On Event and On Write";
CM_ SG_ 2529538049 L_UWB_RL_FD_Crc4Val "L_UWB_RL_FD_CyclicRedundancyCheck4Value";
CM_ SG_ 2529538049 L_UWB_RL_FD_AlvCnt4Val "L_UWB_RL_FD_AliveCounter4Value";
CM_ SG_ 2529538049 RL_SWID_3_IVD_1 "UWB RL SW Unit 3 IVD1";
CM_ BO_ 1410 "[TP] Transport Protocol";
CM_ BO_ 2281701568 "[PE] Periodic and On Event";
CM_ SG_ 2281701568 L_UWB_FL_FD_Crc10Val "L_UWB_FL_FD_CyclicRedundancyCheck10Value";
CM_ SG_ 2281701568 UWB_FL_SW_MCU_Ver_Major "UWB FL SW MCU Version Major";
CM_ SG_ 2281701568 UWB_FL_SW_MCU_Ver_Minor "UWB FL SW MCU Version Minor";
CM_ SG_ 2281701568 UWB_FL_SW_IC_Ver_Major "UWB FL SW IC Version Major";
CM_ SG_ 2281701568 UWB_FL_SW_IC_Ver_Minor "UWB FL SW IC Version Minor";
CM_ SG_ 2281701568 UWB_FL_DTC "UWB FL DTC Data";
CM_ SG_ 2281701568 L_UWB_FL_FD_AlvCnt10Val "L_UWB_FL_FD_AliveCounter10Value";
CM_ SG_ 2281701568 UWB_FL_Status1 "UWB_FL Processing Status 1";
CM_ SG_ 2281701568 UWB_FL_Status2 "UWB_FL Processing Status 2";
CM_ SG_ 2281701568 UWB_FL_Status3 "UWB_FL Processing Status 3";
CM_ SG_ 2281701568 UWB_FL_Status4 "UWB_FL Processing Status 4";
CM_ SG_ 2281701568 UWB_FL_Status5 "UWB_FL Processing Status 5";
CM_ SG_ 2281701568 UWB_FL_Status6 "UWB_FL Processing Status 6";
CM_ SG_ 2281701568 UWB_FL_Status7 "UWB_FL Processing Status 7";
CM_ SG_ 2281701568 UWB_FL_Status8 "UWB_FL Processing Status 8";
CM_ SG_ 2281701568 UWB_FL_Status9 "UWB_FL Processing Status 9";
CM_ SG_ 2281701568 UWB_FL_Status10 "UWB_FL Processing Status 10";
CM_ SG_ 2281701568 UWB_FL_Status11 "UWB_FL Processing Status 11";
CM_ SG_ 2281701568 UWB_FL_Status12 "UWB_FL Processing Status 12";
CM_ SG_ 2281701568 UWB_FL_Status13 "UWB_FL Processing Status 13";
CM_ SG_ 2281701568 UWB_FL_Status14 "UWB_FL Processing Status 14";
CM_ SG_ 2281701568 UWB_FL_Status15 "UWB_FL Processing Status 15";
CM_ SG_ 2281701568 UWB_FL_Status16 "UWB_FL Processing Status 16";
CM_ SG_ 2281701568 UWB_FL_HW_Ver_Major "UWB FL HW Version Major";
CM_ SG_ 2281701568 UWB_FL_HW_Ver_Minor "UWB FL HW Version Minor";
CM_ BO_ 1418 "[TP] Transport Protocol";
CM_ BO_ 992 "[PE] Periodic and On Event";
CM_ SG_ 992 PDC_FD_Crc1Val "PDC_FD_CyclicRedundancyCheck1Value";
CM_ SG_ 992 C_3rdRRSeatBeltSW_Copy_0 "3rd Rear Right Seat Belt Switch Status";
CM_ SG_ 992 DPDMat_HDPSpprtSWVer_Copy_0 "HDP-DPD Mat signal processing Requirement Spec Version";
CM_ SG_ 992 Warn_PassStOccSta_Copy_0 "Warn_PassengerSeatOccupyStatus ##2G## -  - C_SBRMatSw";
CM_ SG_ 992 Warn_RrLftSBRMATSwSta_Copy_0 "##2G## -  - C_RLSBRMatSw";
CM_ SG_ 992 Warn_RrRhtSBRMATSwSta_Copy_0 "##2G## -  - C_RRSBRMatSw";
CM_ SG_ 992 ChildLock_ActnFlSta_Copy_0 "ChildLock_ActuationFailedStatus ##2G## -  - C_ChildLockFail";
CM_ SG_ 992 DoorLock_LkOutSta_Copy_0 "DoorLock_LockOutputStatus ##2G## -  - C_LockUnlockOutState";
CM_ SG_ 992 VSAutoDrLkRetryFailSta_Copy_0 "Door lock fail status after vehicle speed auto door lock retry 3 times";
CM_ SG_ 992 Trunk_TrnkTlgtOutReleaseSwSta_Co "Trunk_TrunkTailgateOutReleaseSwitchStatus ##2G## -  - C_TrunkTgOtrReleaseSW";
CM_ SG_ 992 Trunk_TrnkInReleaseSwSta_Copy_0 "Trunk_TrunkInnerReleaseSwitchStatus ##2G## -  - C_TrunkInnerReleaseSw";
CM_ SG_ 992 Trunk_GlvBxTrnkLkSwSta_Copy_0 "Trunk_GloveBoxTrunkLockSwitchStatus ##2G## -  - C_GloveBoxTrunkLockSw";
CM_ SG_ 992 Trunk_TrnkTlgtSwSta_Copy_0 "Trunk_TrunkTailgateSwitchStatus ##2G## -  - C_TrunkTgSw,CF_Gway_TrunkTgSw,Trunk_TrnkTlgtSwSta";
CM_ SG_ 992 Trunk_TlgtFullOpnSwSta_Copy_0 "Trunk_TailGateFullOpenSwitchStatus ##2G## -  - C_TgFullOpenSW";
CM_ SG_ 992 Trunk_TrnkTlgtReleaseRlySta_Copy "Trunk_TrunkTailgateReleaseRelayStatus ##2G## -  - C_TrunkTgReleaseRlyAct";
CM_ SG_ 992 FrtWiper_ParkingSwState "Front wiper parking switch state";
CM_ SG_ 992 PDC_FD_AlvCnt1Val "PDC_FD_AliveCounter1Value";
CM_ SG_ 992 OBCWakeupDrLock_Copy_0 "This signal is for OBC wake-up";
CM_ SG_ 992 OBCWakeupDrUnlock_Copy_0 "This signal is for OBC wake-up";
CM_ SG_ 992 Trunk_BgtOpnHzrdReq_Copy_0 "Hazzard Request by Bedgate Open";
CM_ SG_ 992 Trunk_BgtOpnBzrReq_Copy_0 "Buzzer Request by Bedgate Open";
CM_ SG_ 992 IGN3State "Output status of ignition 3";
CM_ SG_ 992 IGN3State_By_BMS "Output status of ignition 3 by BMS request";
CM_ SG_ 992 IGN3State_By_VCMS_HMU "Output status of ignition 3 by VCMS(PHEV/EV) or HMU(FCEV) request";
CM_ SG_ 992 IGN3State_By_AfterBlow "Output status of ignition 3 by DATC(FATC/MTC) request for after blow";
CM_ SG_ 992 IGN3State_By_Bat_Copy_0 "Output status of ignition 3 by IBS or BMS request for HEV 12V auxiliary battery charging";
CM_ SG_ 992 IGN3State_By_VCU_HCU_FCU "Output status of ignition 3 by VCU(EV) or HCU(HEV/PHEV) or FCU(FCEV) request";
CM_ SG_ 992 IGN3State_By_HU "Output status of ignition 3 by HU(AVNT) or CCU request for CCS";
CM_ SG_ 992 IGN3CutOffState "Output status of ignition 3 Cut Off";
CM_ SG_ 992 Reprogram_State_PDC2 "PDC's reprogramming state";
CM_ SG_ 992 DriveTypeOption_Copy_0 "##2G## -  - C_DriveTypeOption,CF_Gway_DriveTypeOption";
CM_ SG_ 992 AutoLtOpt_Copy_0 "Auto Light ╗ч╛ч └√┐ы ┐й║╬ ╣╫ └√┐ы ┐╔╝╟ ┴д║╕ ├т╖┬ (╣╠└√┐ы/└√┐ы)";
CM_ SG_ 992 HLmpLoHiOptLtSrcTyp_Copy_0 "Head Low&High Lamp ╗ч╛ч └√┐ы ┐й║╬ ╣╫ Light Source Type, ┐╔╝╟ ┴д║╕ ├т╖┬";
CM_ SG_ 992 ICU_MtGearPosRSta_Copy_0 "##2G## -  - C_InhibitRMT,CF_Gway_InhibitRMT";
CM_ SG_ 992 C_AutoLeverManualSW_Copy_0 "Auto Lever Manual Switch Status Information";
CM_ SG_ 992 Warn_HoodSwMemorySta_Copy_0 "Warn_HoodSwitchMemoryStatus ##2G## -  - CF_Hoodsw_memory,C_HoodSwMemory";
CM_ SG_ 992 Warn_PrkngBrkSwSta_Copy_0 "Warn_ParkingBrakeSwitchStatus ##2G## -  - C_ParkBrakeSw";
CM_ SG_ 992 Warn_BrkFldSwSta_Copy_0 "Warn_BrakeFluidSwitchStatus ##2G## -  - C_BrakeFluidSw,CF_Gway_BrakeFluidSw";
CM_ SG_ 992 Warn_WshrFldSwSta_Copy_0 "Washer Fluid Switch Signal ##2G## -  - CF_Gway_WasherFluidSw";
CM_ SG_ 992 Warn_DrvStBltSwSta_Copy_0 "Warn_DriverSeatbeltSwitchStatus ##2G## -  - C_DrvSeatBeltSw,CF_Gway_DrvSeatBeltSw";
CM_ SG_ 992 Warn_AsstStBltSwSta_Copy_0 "Warn_AssistSeatBeltSwitchStatus ##2G## -  - C_AstSeatBeltSw,CF_Gway_AstSeatBeltSw";
CM_ SG_ 992 Warn_RrLftStBltSwSta_Copy_0 "Warn_RearLeftSeatBeltSwitchStatus ##2G## -  - C_RLSeatBeltSw";
CM_ SG_ 992 Warn_RrCtrStBltSwSta_Copy_0 "Warn_RearCenterSeatBeltSwitchStatus ##2G## -  - C_RCSeatBeltSw";
CM_ SG_ 992 Warn_RrRtStBltSwSta_Copy_0 "Warn_RearRightSeatBeltSwitchStatus ##2G## -  - C_RRSeatBeltSw";
CM_ SG_ 992 C_3rdRLSeatBeltSW_Copy_0 "3rd Rear Left Seat Belt Switch Status";
BA_DEF_ BO_  "CANFD_BRS" ENUM  "0","1";
BA_DEF_ BO_  "GenMsgEVName" STRING ;
BA_DEF_ BO_  "NmAsrMessage" ENUM  "No","Yes";
BA_DEF_ BO_  "DiagState" ENUM  "No","Yes";
BA_DEF_ BO_  "DiagResponse" ENUM  "No","Yes";
BA_DEF_ BO_  "DiagRequest" ENUM  "No","Yes";
BA_DEF_ BO_  "TpMessage" ENUM  "No","Yes";
BA_DEF_ BO_  "UsrMsgIDSforwardDeviation" INT 0 100;
BA_DEF_ BO_  "UsrMsgIDSbackwardDeviation" INT 50 1000;
BA_DEF_ BO_  "GenMsgCycleTime" INT 0 2000;
BA_DEF_ BO_  "GenMsgStartDelayTime" INT 0 2000;
BA_DEF_ BO_  "GenMsgSendType" ENUM  "Cyclic","NoMsgSendType";
BA_DEF_ BO_  "GenMsgCycleTimeFast" INT 0 500;
BA_DEF_ BO_  "GenMsgDelayTime" INT 0 20;
BA_DEF_ BO_  "GenMsgILSupport" ENUM  "No","Yes";
BA_DEF_ BO_  "GenMsgNrOfRepetition" INT 0 3;
BA_DEF_ BO_  "TpTxIndex" INT 0 65535;
BA_DEF_ BO_  "VFrameFormat" ENUM  "StandardCAN","ExtendedCAN","reserved","reserved","reserved","reserved","reserved","reserved","reserved","reserved","reserved","reserved","reserved","reserved","StandardCAN_FD","ExtendedCAN_FD";
BA_DEF_ SG_  "UserSigValidity" ENUM  "B+","ACC","IG","IG1","IG2","IG3","IG1 or IG2","IG1 or IG3","Undef";
BA_DEF_ SG_  "TimeoutValue" STRING ;
BA_DEF_ SG_  "UsrSigPurpose" ENUM  "Undef","FN","DIAG","DIAG(Req)","DIAG(Res)","DIAG(Func)","DEV","CCP","NM","TP";
BA_DEF_ SG_  "GenSigStartValue" INT 0 1215752192;
BA_DEF_ SG_  "NetworkRequest" ENUM  "Yes","No";
BA_DEF_ SG_  "NetworkRequestHoldingTime" INT 0 65535;
BA_DEF_ SG_  "Description" STRING ;
BA_DEF_ SG_  "Version" STRING ;
BA_DEF_ SG_  "GenSigEnvVarType" ENUM  "Int","Float","Undef";
BA_DEF_ SG_  "GenSigSendType" ENUM  "Cyclic","OnWrite","OnWriteWithRepetition","OnChange","OnChangeWithRepetition","IfActive","IfActiveWithRepetition","NoSigSendType","OnChangeAndIfActive","OnChangeAndIfActiveWithRepetition";
BA_DEF_ SG_  "GwSigLatencyTime" INT 0 65536;
BA_DEF_ SG_  "GwSigMissingSourceType" ENUM  "Undef","OldValue","DefaultValue","InitialValue";
BA_DEF_ SG_  "NWM-WakeupAllowed" ENUM  "<n.a.>";
BA_DEF_ SG_  "RoutingFactor" INT 1 1215752192;
BA_DEF_ SG_  "SystemSignalLongSymbol" STRING ;
BA_DEF_REL_ BU_SG_REL_  "GenSigTimeoutTime" INT 0 7000;
BA_DEF_DEF_  "CANFD_BRS" "1";
BA_DEF_DEF_  "GenMsgEVName" "@Signame";
BA_DEF_DEF_  "NmAsrMessage" "No";
BA_DEF_DEF_  "DiagState" "No";
BA_DEF_DEF_  "DiagResponse" "No";
BA_DEF_DEF_  "DiagRequest" "No";
BA_DEF_DEF_  "TpMessage" "No";
BA_DEF_DEF_  "UsrMsgIDSforwardDeviation" 10;
BA_DEF_DEF_  "UsrMsgIDSbackwardDeviation" 100;
BA_DEF_DEF_  "GenMsgCycleTime" 200;
BA_DEF_DEF_  "GenMsgStartDelayTime" 0;
BA_DEF_DEF_  "GenMsgSendType" "NoMsgSendType";
BA_DEF_DEF_  "GenMsgCycleTimeFast" 40;
BA_DEF_DEF_  "GenMsgDelayTime" 20;
BA_DEF_DEF_  "GenMsgILSupport" "Yes";
BA_DEF_DEF_  "GenMsgNrOfRepetition" 3;
BA_DEF_DEF_  "TpTxIndex" 0;
BA_DEF_DEF_  "VFrameFormat" "StandardCAN";
BA_DEF_DEF_  "UserSigValidity" "IG";
BA_DEF_DEF_  "TimeoutValue" "";
BA_DEF_DEF_  "UsrSigPurpose" "FN";
BA_DEF_DEF_  "GenSigStartValue" 0;
BA_DEF_DEF_  "NetworkRequest" "No";
BA_DEF_DEF_  "NetworkRequestHoldingTime" 0;
BA_DEF_DEF_  "Description" "";
BA_DEF_DEF_  "Version" "";
BA_DEF_DEF_  "GenSigEnvVarType" "Undef";
BA_DEF_DEF_  "GenSigSendType" "NoSigSendType";
BA_DEF_DEF_  "GwSigLatencyTime" 40;
BA_DEF_DEF_  "GwSigMissingSourceType" "Undef";
BA_DEF_DEF_  "NWM-WakeupAllowed" "<n.a.>";
BA_DEF_DEF_  "RoutingFactor" 1;
BA_DEF_DEF_REL_ "GenSigTimeoutTime" 500;
BA_DEF_DEF_  "SystemSignalLongSymbol" "";
BA_ "GenMsgSendType" BO_ 2281701552 0;
BA_ "VFrameFormat" BO_ 2281701552 15;
BA_ "TpTxIndex" BO_ 2006 177;
BA_ "TpMessage" BO_ 2006 1;
BA_ "GenMsgILSupport" BO_ 2006 0;
BA_ "DiagRequest" BO_ 2006 1;
BA_ "GenMsgNrOfRepetition" BO_ 2006 0;
BA_ "GenMsgCycleTimeFast" BO_ 2006 0;
BA_ "GenMsgCycleTime" BO_ 2006 0;
BA_ "VFrameFormat" BO_ 2006 14;
BA_ "TpTxIndex" BO_ 2014 177;
BA_ "TpMessage" BO_ 2014 1;
BA_ "GenMsgILSupport" BO_ 2014 0;
BA_ "DiagResponse" BO_ 2014 1;
BA_ "GenMsgNrOfRepetition" BO_ 2014 0;
BA_ "GenMsgCycleTimeFast" BO_ 2014 0;
BA_ "GenMsgCycleTime" BO_ 2014 0;
BA_ "VFrameFormat" BO_ 2014 14;
BA_ "TpMessage" BO_ 2015 1;
BA_ "GenMsgILSupport" BO_ 2015 0;
BA_ "DiagState" BO_ 2015 1;
BA_ "GenMsgNrOfRepetition" BO_ 2015 0;
BA_ "GenMsgCycleTimeFast" BO_ 2015 0;
BA_ "GenMsgCycleTime" BO_ 2015 0;
BA_ "VFrameFormat" BO_ 2015 14;
BA_ "GenMsgDelayTime" BO_ 2525339905 10;
BA_ "GenMsgCycleTime" BO_ 2525339905 0;
BA_ "VFrameFormat" BO_ 2525339905 15;
BA_ "GenMsgSendType" BO_ 2281701536 0;
BA_ "VFrameFormat" BO_ 2281701536 15;
BA_ "GenMsgDelayTime" BO_ 426 0;
BA_ "GenMsgNrOfRepetition" BO_ 426 0;
BA_ "GenMsgCycleTimeFast" BO_ 426 0;
BA_ "GenMsgCycleTime" BO_ 426 20;
BA_ "GenMsgSendType" BO_ 426 0;
BA_ "VFrameFormat" BO_ 426 14;
BA_ "GenMsgSendType" BO_ 2281701537 0;
BA_ "VFrameFormat" BO_ 2281701537 15;
BA_ "TpTxIndex" BO_ 1504 162;
BA_ "TpMessage" BO_ 1504 1;
BA_ "GenMsgILSupport" BO_ 1504 0;
BA_ "DiagRequest" BO_ 1504 1;
BA_ "GenMsgNrOfRepetition" BO_ 1504 0;
BA_ "GenMsgCycleTimeFast" BO_ 1504 0;
BA_ "GenMsgCycleTime" BO_ 1504 0;
BA_ "VFrameFormat" BO_ 1504 14;
BA_ "TpTxIndex" BO_ 1512 162;
BA_ "TpMessage" BO_ 1512 1;
BA_ "GenMsgILSupport" BO_ 1512 0;
BA_ "DiagResponse" BO_ 1512 1;
BA_ "GenMsgNrOfRepetition" BO_ 1512 0;
BA_ "GenMsgCycleTimeFast" BO_ 1512 0;
BA_ "GenMsgCycleTime" BO_ 1512 0;
BA_ "VFrameFormat" BO_ 1512 14;
BA_ "GenMsgSendType" BO_ 2281701584 0;
BA_ "VFrameFormat" BO_ 2281701584 15;
BA_ "GenMsgCycleTime" BO_ 2348810256 0;
BA_ "VFrameFormat" BO_ 2348810256 15;
BA_ "GenMsgSendType" BO_ 2348810257 0;
BA_ "VFrameFormat" BO_ 2348810257 15;
BA_ "GenMsgDelayTime" BO_ 2533736449 10;
BA_ "GenMsgCycleTime" BO_ 2533736449 0;
BA_ "VFrameFormat" BO_ 2533736449 15;
BA_ "GenMsgDelayTime" BO_ 2529538049 10;
BA_ "GenMsgCycleTime" BO_ 2529538049 0;
BA_ "VFrameFormat" BO_ 2529538049 15;
BA_ "TpTxIndex" BO_ 1410 95;
BA_ "TpMessage" BO_ 1410 1;
BA_ "GenMsgILSupport" BO_ 1410 0;
BA_ "DiagRequest" BO_ 1410 1;
BA_ "GenMsgNrOfRepetition" BO_ 1410 0;
BA_ "GenMsgCycleTimeFast" BO_ 1410 0;
BA_ "GenMsgCycleTime" BO_ 1410 0;
BA_ "VFrameFormat" BO_ 1410 14;
BA_ "GenMsgSendType" BO_ 2281701568 0;
BA_ "VFrameFormat" BO_ 2281701568 15;
BA_ "TpTxIndex" BO_ 1418 95;
BA_ "TpMessage" BO_ 1418 1;
BA_ "GenMsgILSupport" BO_ 1418 0;
BA_ "DiagResponse" BO_ 1418 1;
BA_ "GenMsgNrOfRepetition" BO_ 1418 0;
BA_ "GenMsgCycleTimeFast" BO_ 1418 0;
BA_ "GenMsgCycleTime" BO_ 1418 0;
BA_ "VFrameFormat" BO_ 1418 14;
BA_ "GenMsgSendType" BO_ 992 0;
BA_ "VFrameFormat" BO_ 992 14;
BA_ "Version" SG_ 2281701552 L_UWB_BLE_SLV_FD_Crc20Val "23.01.02";
BA_ "UserSigValidity" SG_ 2281701552 L_UWB_BLE_SLV_FD_Crc20Val 3;
BA_ "GenSigStartValue" SG_ 2281701552 L_UWB_BLE_SLV_FD_Crc20Val 65535;
BA_ "GenSigSendType" SG_ 2281701552 L_UWB_BLE_SLV_FD_Crc20Val 4;
BA_ "Description" SG_ 2281701552 L_UWB_BLE_SLV_FD_Crc20Val "The data area for CRC calculation is based on the data length (DLC) of the message DB.

The CRC shall be calculated over the entire data block (excluding the CRC bytes) including the user data, alive counter and Data ID



- CRC Polynomial (0x1021) , Ini";
BA_ "Version" SG_ 2281701552 SLV_BLE_ConnectedDeviceInfo "23.01.02";
BA_ "UserSigValidity" SG_ 2281701552 SLV_BLE_ConnectedDeviceInfo 0;
BA_ "GenSigSendType" SG_ 2281701552 SLV_BLE_ConnectedDeviceInfo 4;
BA_ "Version" SG_ 2281701552 SLV_BLE_Passive_ADV_State "23.01.02";
BA_ "UserSigValidity" SG_ 2281701552 SLV_BLE_Passive_ADV_State 0;
BA_ "GenSigSendType" SG_ 2281701552 SLV_BLE_Passive_ADV_State 4;
BA_ "Version" SG_ 2281701552 SLV_BLE_NewDeviceConnetStatus "23.01.02";
BA_ "UserSigValidity" SG_ 2281701552 SLV_BLE_NewDeviceConnetStatus 0;
BA_ "GenSigSendType" SG_ 2281701552 SLV_BLE_NewDeviceConnetStatus 4;
BA_ "Version" SG_ 2281701552 SLV_BLE_PairingResult "23.01.02";
BA_ "UserSigValidity" SG_ 2281701552 SLV_BLE_PairingResult 0;
BA_ "GenSigSendType" SG_ 2281701552 SLV_BLE_PairingResult 4;
BA_ "Version" SG_ 2281701552 SLV_BLE_BondingDataStatus "23.10.11";
BA_ "UserSigValidity" SG_ 2281701552 SLV_BLE_BondingDataStatus 0;
BA_ "GenSigSendType" SG_ 2281701552 SLV_BLE_BondingDataStatus 4;
BA_ "Description" SG_ 2281701552 SLV_BLE_BondingDataStatus "Valid Range : 0x0000 ~ 0xFFFF";
BA_ "Version" SG_ 2281701552 SLV_BLE_InternalStatus "24.01.04";
BA_ "UserSigValidity" SG_ 2281701552 SLV_BLE_InternalStatus 0;
BA_ "GenSigSendType" SG_ 2281701552 SLV_BLE_InternalStatus 4;
BA_ "Description" SG_ 2281701552 SLV_BLE_InternalStatus "Valid Range : 0x00 ~ 0xFF";
BA_ "Version" SG_ 2281701552 L_UWB_BLE_SLV_FD_AlvCnt20Val "23.01.02";
BA_ "UserSigValidity" SG_ 2281701552 L_UWB_BLE_SLV_FD_AlvCnt20Val 3;
BA_ "GenSigSendType" SG_ 2281701552 L_UWB_BLE_SLV_FD_AlvCnt20Val 4;
BA_ "Description" SG_ 2281701552 L_UWB_BLE_SLV_FD_AlvCnt20Val "For the first transmission request for a data element the counter shall be initialized with 0 and shall be incremented by 1 for every subsequent send request. 

When the counter reaches the maximum value(0xFF), then it shall restart with 0 for the next s";
BA_ "Version" SG_ 2281701552 SLV_BLE_DK_ID1 "23.01.02";
BA_ "UserSigValidity" SG_ 2281701552 SLV_BLE_DK_ID1 0;
BA_ "GenSigSendType" SG_ 2281701552 SLV_BLE_DK_ID1 4;
BA_ "Version" SG_ 2281701552 SLV_BLE_RSSI1 "23.01.02";
BA_ "UserSigValidity" SG_ 2281701552 SLV_BLE_RSSI1 0;
BA_ "GenSigSendType" SG_ 2281701552 SLV_BLE_RSSI1 4;
BA_ "Version" SG_ 2281701552 SLV_BLE_DK_ID2 "23.01.02";
BA_ "UserSigValidity" SG_ 2281701552 SLV_BLE_DK_ID2 0;
BA_ "GenSigSendType" SG_ 2281701552 SLV_BLE_DK_ID2 4;
BA_ "Version" SG_ 2281701552 SLV_BLE_RSSI2 "23.01.02";
BA_ "UserSigValidity" SG_ 2281701552 SLV_BLE_RSSI2 0;
BA_ "GenSigSendType" SG_ 2281701552 SLV_BLE_RSSI2 4;
BA_ "Version" SG_ 2281701552 SLV_BLE_DK_ID3 "23.01.02";
BA_ "UserSigValidity" SG_ 2281701552 SLV_BLE_DK_ID3 0;
BA_ "GenSigSendType" SG_ 2281701552 SLV_BLE_DK_ID3 4;
BA_ "Version" SG_ 2281701552 SLV_BLE_RSSI3 "23.01.02";
BA_ "UserSigValidity" SG_ 2281701552 SLV_BLE_RSSI3 0;
BA_ "GenSigSendType" SG_ 2281701552 SLV_BLE_RSSI3 4;
BA_ "Version" SG_ 2281701552 SLV_BLE_DK_ID4 "23.01.02";
BA_ "UserSigValidity" SG_ 2281701552 SLV_BLE_DK_ID4 0;
BA_ "GenSigSendType" SG_ 2281701552 SLV_BLE_DK_ID4 4;
BA_ "Version" SG_ 2281701552 SLV_BLE_RSSI4 "23.01.02";
BA_ "UserSigValidity" SG_ 2281701552 SLV_BLE_RSSI4 0;
BA_ "GenSigSendType" SG_ 2281701552 SLV_BLE_RSSI4 4;
BA_ "Version" SG_ 2281701552 SLV_BLE_BTAddIRK_Update "23.01.02";
BA_ "UserSigValidity" SG_ 2281701552 SLV_BLE_BTAddIRK_Update 0;
BA_ "GenSigSendType" SG_ 2281701552 SLV_BLE_BTAddIRK_Update 4;
BA_ "Version" SG_ 2006 GST_TPMS_Byte0 "21.02.04";
BA_ "NetworkRequestHoldingTime" SG_ 2006 GST_TPMS_Byte0 5000;
BA_ "NetworkRequest" SG_ 2006 GST_TPMS_Byte0 0;
BA_ "UserSigValidity" SG_ 2006 GST_TPMS_Byte0 0;
BA_ "UsrSigPurpose" SG_ 2006 GST_TPMS_Byte0 3;
BA_ "Description" SG_ 2006 GST_TPMS_Byte0 "TP Index : 177";
BA_ "Version" SG_ 2006 GST_TPMS_Byte2 "21.02.04";
BA_ "NetworkRequestHoldingTime" SG_ 2006 GST_TPMS_Byte2 5000;
BA_ "NetworkRequest" SG_ 2006 GST_TPMS_Byte2 0;
BA_ "UserSigValidity" SG_ 2006 GST_TPMS_Byte2 0;
BA_ "UsrSigPurpose" SG_ 2006 GST_TPMS_Byte2 3;
BA_ "Description" SG_ 2006 GST_TPMS_Byte2 "TP Index : 177";
BA_ "Version" SG_ 2006 GST_TPMS_Byte3 "21.02.04";
BA_ "NetworkRequestHoldingTime" SG_ 2006 GST_TPMS_Byte3 5000;
BA_ "NetworkRequest" SG_ 2006 GST_TPMS_Byte3 0;
BA_ "UserSigValidity" SG_ 2006 GST_TPMS_Byte3 0;
BA_ "UsrSigPurpose" SG_ 2006 GST_TPMS_Byte3 3;
BA_ "Description" SG_ 2006 GST_TPMS_Byte3 "TP Index : 177";
BA_ "Version" SG_ 2006 GST_TPMS_Byte4 "21.02.04";
BA_ "NetworkRequestHoldingTime" SG_ 2006 GST_TPMS_Byte4 5000;
BA_ "NetworkRequest" SG_ 2006 GST_TPMS_Byte4 0;
BA_ "UserSigValidity" SG_ 2006 GST_TPMS_Byte4 0;
BA_ "UsrSigPurpose" SG_ 2006 GST_TPMS_Byte4 3;
BA_ "Description" SG_ 2006 GST_TPMS_Byte4 "TP Index : 177";
BA_ "Version" SG_ 2006 GST_TPMS_Byte5 "21.02.04";
BA_ "NetworkRequestHoldingTime" SG_ 2006 GST_TPMS_Byte5 5000;
BA_ "NetworkRequest" SG_ 2006 GST_TPMS_Byte5 0;
BA_ "UserSigValidity" SG_ 2006 GST_TPMS_Byte5 0;
BA_ "UsrSigPurpose" SG_ 2006 GST_TPMS_Byte5 3;
BA_ "Description" SG_ 2006 GST_TPMS_Byte5 "TP Index : 177";
BA_ "Version" SG_ 2006 GST_TPMS_Byte6 "21.02.04";
BA_ "NetworkRequestHoldingTime" SG_ 2006 GST_TPMS_Byte6 5000;
BA_ "NetworkRequest" SG_ 2006 GST_TPMS_Byte6 0;
BA_ "UserSigValidity" SG_ 2006 GST_TPMS_Byte6 0;
BA_ "UsrSigPurpose" SG_ 2006 GST_TPMS_Byte6 3;
BA_ "Description" SG_ 2006 GST_TPMS_Byte6 "TP Index : 177";
BA_ "Version" SG_ 2006 GST_TPMS_Byte7 "21.02.04";
BA_ "NetworkRequestHoldingTime" SG_ 2006 GST_TPMS_Byte7 5000;
BA_ "NetworkRequest" SG_ 2006 GST_TPMS_Byte7 0;
BA_ "UserSigValidity" SG_ 2006 GST_TPMS_Byte7 0;
BA_ "UsrSigPurpose" SG_ 2006 GST_TPMS_Byte7 3;
BA_ "Description" SG_ 2006 GST_TPMS_Byte7 "TP Index : 177";
BA_ "Version" SG_ 2006 GST_TPMS_Byte1 "21.02.04";
BA_ "NetworkRequestHoldingTime" SG_ 2006 GST_TPMS_Byte1 5000;
BA_ "NetworkRequest" SG_ 2006 GST_TPMS_Byte1 0;
BA_ "UserSigValidity" SG_ 2006 GST_TPMS_Byte1 0;
BA_ "UsrSigPurpose" SG_ 2006 GST_TPMS_Byte1 3;
BA_ "Description" SG_ 2006 GST_TPMS_Byte1 "TP Index : 177";
BA_ "Version" SG_ 2014 TPMS_GST_Byte0 "22.07.01";
BA_ "NetworkRequestHoldingTime" SG_ 2014 TPMS_GST_Byte0 5000;
BA_ "NetworkRequest" SG_ 2014 TPMS_GST_Byte0 0;
BA_ "UserSigValidity" SG_ 2014 TPMS_GST_Byte0 0;
BA_ "UsrSigPurpose" SG_ 2014 TPMS_GST_Byte0 4;
BA_ "Description" SG_ 2014 TPMS_GST_Byte0 "TP Index : 177";
BA_ "Version" SG_ 2014 TPMS_GST_Byte2 "22.07.01";
BA_ "NetworkRequestHoldingTime" SG_ 2014 TPMS_GST_Byte2 5000;
BA_ "NetworkRequest" SG_ 2014 TPMS_GST_Byte2 0;
BA_ "UserSigValidity" SG_ 2014 TPMS_GST_Byte2 0;
BA_ "UsrSigPurpose" SG_ 2014 TPMS_GST_Byte2 4;
BA_ "Description" SG_ 2014 TPMS_GST_Byte2 "TP Index : 177";
BA_ "Version" SG_ 2014 TPMS_GST_Byte3 "22.07.01";
BA_ "NetworkRequestHoldingTime" SG_ 2014 TPMS_GST_Byte3 5000;
BA_ "NetworkRequest" SG_ 2014 TPMS_GST_Byte3 0;
BA_ "UserSigValidity" SG_ 2014 TPMS_GST_Byte3 0;
BA_ "UsrSigPurpose" SG_ 2014 TPMS_GST_Byte3 4;
BA_ "Description" SG_ 2014 TPMS_GST_Byte3 "TP Index : 177";
BA_ "Version" SG_ 2014 TPMS_GST_Byte4 "22.07.01";
BA_ "NetworkRequestHoldingTime" SG_ 2014 TPMS_GST_Byte4 5000;
BA_ "NetworkRequest" SG_ 2014 TPMS_GST_Byte4 0;
BA_ "UserSigValidity" SG_ 2014 TPMS_GST_Byte4 0;
BA_ "UsrSigPurpose" SG_ 2014 TPMS_GST_Byte4 4;
BA_ "Description" SG_ 2014 TPMS_GST_Byte4 "TP Index : 177";
BA_ "Version" SG_ 2014 TPMS_GST_Byte5 "22.07.01";
BA_ "NetworkRequestHoldingTime" SG_ 2014 TPMS_GST_Byte5 5000;
BA_ "NetworkRequest" SG_ 2014 TPMS_GST_Byte5 0;
BA_ "UserSigValidity" SG_ 2014 TPMS_GST_Byte5 0;
BA_ "UsrSigPurpose" SG_ 2014 TPMS_GST_Byte5 4;
BA_ "Description" SG_ 2014 TPMS_GST_Byte5 "TP Index : 177";
BA_ "Version" SG_ 2014 TPMS_GST_Byte6 "22.07.01";
BA_ "NetworkRequestHoldingTime" SG_ 2014 TPMS_GST_Byte6 5000;
BA_ "NetworkRequest" SG_ 2014 TPMS_GST_Byte6 0;
BA_ "UserSigValidity" SG_ 2014 TPMS_GST_Byte6 0;
BA_ "UsrSigPurpose" SG_ 2014 TPMS_GST_Byte6 4;
BA_ "Description" SG_ 2014 TPMS_GST_Byte6 "TP Index : 177";
BA_ "Version" SG_ 2014 TPMS_GST_Byte7 "22.07.01";
BA_ "NetworkRequestHoldingTime" SG_ 2014 TPMS_GST_Byte7 5000;
BA_ "NetworkRequest" SG_ 2014 TPMS_GST_Byte7 0;
BA_ "UserSigValidity" SG_ 2014 TPMS_GST_Byte7 0;
BA_ "UsrSigPurpose" SG_ 2014 TPMS_GST_Byte7 4;
BA_ "Description" SG_ 2014 TPMS_GST_Byte7 "TP Index : 177";
BA_ "Version" SG_ 2014 TPMS_GST_Byte1 "22.07.01";
BA_ "NetworkRequestHoldingTime" SG_ 2014 TPMS_GST_Byte1 5000;
BA_ "NetworkRequest" SG_ 2014 TPMS_GST_Byte1 0;
BA_ "UserSigValidity" SG_ 2014 TPMS_GST_Byte1 0;
BA_ "UsrSigPurpose" SG_ 2014 TPMS_GST_Byte1 4;
BA_ "Description" SG_ 2014 TPMS_GST_Byte1 "TP Index : 177";
BA_ "Version" SG_ 2015 GST_ALL_Byte0 "22.06.01";
BA_ "NetworkRequestHoldingTime" SG_ 2015 GST_ALL_Byte0 5000;
BA_ "NetworkRequest" SG_ 2015 GST_ALL_Byte0 0;
BA_ "UserSigValidity" SG_ 2015 GST_ALL_Byte0 0;
BA_ "UsrSigPurpose" SG_ 2015 GST_ALL_Byte0 5;
BA_ "Description" SG_ 2015 GST_ALL_Byte0 "TP Index : 0";
BA_ "Version" SG_ 2015 GST_ALL_Byte2 "22.06.01";
BA_ "NetworkRequestHoldingTime" SG_ 2015 GST_ALL_Byte2 5000;
BA_ "NetworkRequest" SG_ 2015 GST_ALL_Byte2 0;
BA_ "UserSigValidity" SG_ 2015 GST_ALL_Byte2 0;
BA_ "UsrSigPurpose" SG_ 2015 GST_ALL_Byte2 5;
BA_ "Description" SG_ 2015 GST_ALL_Byte2 "TP Index : 0";
BA_ "Version" SG_ 2015 GST_ALL_Byte3 "22.06.01";
BA_ "NetworkRequestHoldingTime" SG_ 2015 GST_ALL_Byte3 5000;
BA_ "NetworkRequest" SG_ 2015 GST_ALL_Byte3 0;
BA_ "UserSigValidity" SG_ 2015 GST_ALL_Byte3 0;
BA_ "UsrSigPurpose" SG_ 2015 GST_ALL_Byte3 5;
BA_ "Description" SG_ 2015 GST_ALL_Byte3 "TP Index : 0";
BA_ "Version" SG_ 2015 GST_ALL_Byte4 "22.06.01";
BA_ "NetworkRequestHoldingTime" SG_ 2015 GST_ALL_Byte4 5000;
BA_ "NetworkRequest" SG_ 2015 GST_ALL_Byte4 0;
BA_ "UserSigValidity" SG_ 2015 GST_ALL_Byte4 0;
BA_ "UsrSigPurpose" SG_ 2015 GST_ALL_Byte4 5;
BA_ "Description" SG_ 2015 GST_ALL_Byte4 "TP Index : 0";
BA_ "Version" SG_ 2015 GST_ALL_Byte5 "22.06.01";
BA_ "NetworkRequestHoldingTime" SG_ 2015 GST_ALL_Byte5 5000;
BA_ "NetworkRequest" SG_ 2015 GST_ALL_Byte5 0;
BA_ "UserSigValidity" SG_ 2015 GST_ALL_Byte5 0;
BA_ "UsrSigPurpose" SG_ 2015 GST_ALL_Byte5 5;
BA_ "Description" SG_ 2015 GST_ALL_Byte5 "TP Index : 0";
BA_ "Version" SG_ 2015 GST_ALL_Byte6 "22.06.01";
BA_ "NetworkRequestHoldingTime" SG_ 2015 GST_ALL_Byte6 5000;
BA_ "NetworkRequest" SG_ 2015 GST_ALL_Byte6 0;
BA_ "UserSigValidity" SG_ 2015 GST_ALL_Byte6 0;
BA_ "UsrSigPurpose" SG_ 2015 GST_ALL_Byte6 5;
BA_ "Description" SG_ 2015 GST_ALL_Byte6 "TP Index : 0";
BA_ "Version" SG_ 2015 GST_ALL_Byte7 "22.06.01";
BA_ "NetworkRequestHoldingTime" SG_ 2015 GST_ALL_Byte7 5000;
BA_ "NetworkRequest" SG_ 2015 GST_ALL_Byte7 0;
BA_ "UserSigValidity" SG_ 2015 GST_ALL_Byte7 0;
BA_ "UsrSigPurpose" SG_ 2015 GST_ALL_Byte7 5;
BA_ "Description" SG_ 2015 GST_ALL_Byte7 "TP Index : 0";
BA_ "Version" SG_ 2015 GST_ALL_Byte1 "22.06.01";
BA_ "NetworkRequestHoldingTime" SG_ 2015 GST_ALL_Byte1 5000;
BA_ "NetworkRequest" SG_ 2015 GST_ALL_Byte1 0;
BA_ "UserSigValidity" SG_ 2015 GST_ALL_Byte1 0;
BA_ "UsrSigPurpose" SG_ 2015 GST_ALL_Byte1 5;
BA_ "Description" SG_ 2015 GST_ALL_Byte1 "TP Index : 0";
BA_ "Version" SG_ 2525339905 L_UWB_FL_FD_Crc5Val "24.07.05";
BA_ "RoutingFactor" SG_ 2525339905 L_UWB_FL_FD_Crc5Val 0;
BA_ "UserSigValidity" SG_ 2525339905 L_UWB_FL_FD_Crc5Val 3;
BA_ "GenSigStartValue" SG_ 2525339905 L_UWB_FL_FD_Crc5Val 65535;
BA_ "GenSigSendType" SG_ 2525339905 L_UWB_FL_FD_Crc5Val 2;
BA_ "Description" SG_ 2525339905 L_UWB_FL_FD_Crc5Val "The data area for CRC calculation is based on the data length (DLC) of the message DB.

The CRC shall be calculated over the entire data block (excluding the CRC bytes) including the user data, alive counter and Data ID



- CRC Polynomial (0x1021) , Ini";
BA_ "Version" SG_ 2525339905 L_UWB_FL_FD_AlvCnt5Val "24.07.05";
BA_ "RoutingFactor" SG_ 2525339905 L_UWB_FL_FD_AlvCnt5Val 0;
BA_ "UserSigValidity" SG_ 2525339905 L_UWB_FL_FD_AlvCnt5Val 3;
BA_ "GenSigSendType" SG_ 2525339905 L_UWB_FL_FD_AlvCnt5Val 2;
BA_ "Description" SG_ 2525339905 L_UWB_FL_FD_AlvCnt5Val "For the first transmission request for a data element the counter shall be initialized with 0 and shall be incremented by 1 for every subsequent send request. 

When the counter reaches the maximum value(0xFF), then it shall restart with 0 for the next s";
BA_ "Version" SG_ 2525339905 FL_SWID_3_IVD_2 "24.07.05";
BA_ "RoutingFactor" SG_ 2525339905 FL_SWID_3_IVD_2 0;
BA_ "UserSigValidity" SG_ 2525339905 FL_SWID_3_IVD_2 0;
BA_ "GenSigSendType" SG_ 2525339905 FL_SWID_3_IVD_2 2;
BA_ "Version" SG_ 2281701536 L_UWB_BLE_MST_FD_Crc20Val "23.10.11";
BA_ "UserSigValidity" SG_ 2281701536 L_UWB_BLE_MST_FD_Crc20Val 3;
BA_ "GenSigStartValue" SG_ 2281701536 L_UWB_BLE_MST_FD_Crc20Val 65535;
BA_ "GenSigSendType" SG_ 2281701536 L_UWB_BLE_MST_FD_Crc20Val 4;
BA_ "Description" SG_ 2281701536 L_UWB_BLE_MST_FD_Crc20Val "The data area for CRC calculation is based on the data length (DLC) of the message DB.

The CRC shall be calculated over the entire data block (excluding the CRC bytes) including the user data, alive counter and Data ID



- CRC Polynomial (0x1021) , Ini";
BA_ "Version" SG_ 2281701536 MST_BLE_ConnectedDeviceInfo "23.10.11";
BA_ "UserSigValidity" SG_ 2281701536 MST_BLE_ConnectedDeviceInfo 0;
BA_ "GenSigSendType" SG_ 2281701536 MST_BLE_ConnectedDeviceInfo 4;
BA_ "Version" SG_ 2281701536 MST_BLE_OP_ADV_State "23.10.11";
BA_ "UserSigValidity" SG_ 2281701536 MST_BLE_OP_ADV_State 0;
BA_ "GenSigSendType" SG_ 2281701536 MST_BLE_OP_ADV_State 4;
BA_ "Version" SG_ 2281701536 MST_BLE_Passive_ADV_State "23.10.11";
BA_ "UserSigValidity" SG_ 2281701536 MST_BLE_Passive_ADV_State 0;
BA_ "GenSigSendType" SG_ 2281701536 MST_BLE_Passive_ADV_State 4;
BA_ "Version" SG_ 2281701536 MST_BLE_NewDeviceConnetStatus "23.10.11";
BA_ "UserSigValidity" SG_ 2281701536 MST_BLE_NewDeviceConnetStatus 0;
BA_ "GenSigSendType" SG_ 2281701536 MST_BLE_NewDeviceConnetStatus 4;
BA_ "Version" SG_ 2281701536 MST_BLE_PairingResult "23.10.11";
BA_ "UserSigValidity" SG_ 2281701536 MST_BLE_PairingResult 0;
BA_ "GenSigSendType" SG_ 2281701536 MST_BLE_PairingResult 4;
BA_ "Version" SG_ 2281701536 MST_BLE_BondingDataStatus "23.11.00";
BA_ "UserSigValidity" SG_ 2281701536 MST_BLE_BondingDataStatus 0;
BA_ "GenSigSendType" SG_ 2281701536 MST_BLE_BondingDataStatus 4;
BA_ "Description" SG_ 2281701536 MST_BLE_BondingDataStatus "Valid Range : 0x0000 ~ 0xFFFF";
BA_ "Version" SG_ 2281701536 MST_BLE_InternalStatus "24.01.04";
BA_ "UserSigValidity" SG_ 2281701536 MST_BLE_InternalStatus 0;
BA_ "GenSigSendType" SG_ 2281701536 MST_BLE_InternalStatus 4;
BA_ "Description" SG_ 2281701536 MST_BLE_InternalStatus "Valid Range : 0x00 ~ 0xFF";
BA_ "Version" SG_ 2281701536 MST_Vehicle_Info "24.04.03";
BA_ "UserSigValidity" SG_ 2281701536 MST_Vehicle_Info 0;
BA_ "GenSigSendType" SG_ 2281701536 MST_Vehicle_Info 4;
BA_ "Description" SG_ 2281701536 MST_Vehicle_Info "Send UWB BLE Master information to prevent incorrect mounting of UWB anchor";
BA_ "Version" SG_ 2281701536 L_UWB_BLE_MST_FD_AlvCnt20Val "23.10.11";
BA_ "UserSigValidity" SG_ 2281701536 L_UWB_BLE_MST_FD_AlvCnt20Val 3;
BA_ "GenSigSendType" SG_ 2281701536 L_UWB_BLE_MST_FD_AlvCnt20Val 4;
BA_ "Description" SG_ 2281701536 L_UWB_BLE_MST_FD_AlvCnt20Val "For the first transmission request for a data element the counter shall be initialized with 0 and shall be incremented by 1 for every subsequent send request. 

When the counter reaches the maximum value(0xFF), then it shall restart with 0 for the next s";
BA_ "Version" SG_ 2281701536 MST_BLE_DK_ID1 "23.10.11";
BA_ "UserSigValidity" SG_ 2281701536 MST_BLE_DK_ID1 0;
BA_ "GenSigSendType" SG_ 2281701536 MST_BLE_DK_ID1 4;
BA_ "Version" SG_ 2281701536 MST_BLE_RSSI1 "23.10.11";
BA_ "UserSigValidity" SG_ 2281701536 MST_BLE_RSSI1 0;
BA_ "GenSigSendType" SG_ 2281701536 MST_BLE_RSSI1 4;
BA_ "Version" SG_ 2281701536 MST_BLE_DK_ID2 "23.10.11";
BA_ "UserSigValidity" SG_ 2281701536 MST_BLE_DK_ID2 0;
BA_ "GenSigSendType" SG_ 2281701536 MST_BLE_DK_ID2 4;
BA_ "Version" SG_ 2281701536 MST_BLE_RSSI2 "23.10.11";
BA_ "UserSigValidity" SG_ 2281701536 MST_BLE_RSSI2 0;
BA_ "GenSigSendType" SG_ 2281701536 MST_BLE_RSSI2 4;
BA_ "Version" SG_ 2281701536 MST_BLE_DK_ID3 "23.10.11";
BA_ "UserSigValidity" SG_ 2281701536 MST_BLE_DK_ID3 0;
BA_ "GenSigSendType" SG_ 2281701536 MST_BLE_DK_ID3 4;
BA_ "Version" SG_ 2281701536 MST_BLE_RSSI3 "23.10.11";
BA_ "UserSigValidity" SG_ 2281701536 MST_BLE_RSSI3 0;
BA_ "GenSigSendType" SG_ 2281701536 MST_BLE_RSSI3 4;
BA_ "Version" SG_ 2281701536 MST_BLE_DK_ID4 "23.10.11";
BA_ "UserSigValidity" SG_ 2281701536 MST_BLE_DK_ID4 0;
BA_ "GenSigSendType" SG_ 2281701536 MST_BLE_DK_ID4 4;
BA_ "Version" SG_ 2281701536 MST_BLE_RSSI4 "23.10.11";
BA_ "UserSigValidity" SG_ 2281701536 MST_BLE_RSSI4 0;
BA_ "GenSigSendType" SG_ 2281701536 MST_BLE_RSSI4 4;
BA_ "Version" SG_ 2281701536 MST_BLE_BTAddIRK_Update "23.10.11";
BA_ "UserSigValidity" SG_ 2281701536 MST_BLE_BTAddIRK_Update 0;
BA_ "GenSigSendType" SG_ 2281701536 MST_BLE_BTAddIRK_Update 4;
BA_ "Version" SG_ 426 CLU_Crc1Val "21.09.03";
BA_ "RoutingFactor" SG_ 426 CLU_Crc1Val 0;
BA_ "UserSigValidity" SG_ 426 CLU_Crc1Val 3;
BA_ "GenSigStartValue" SG_ 426 CLU_Crc1Val 65535;
BA_ "Description" SG_ 426 CLU_Crc1Val "The data area for CRC calculation is based on the data length (DLC) of the message DB.

The CRC shall be calculated over the entire data block (excluding the CRC bytes) including the user data, alive counter and Data ID



- CRC Polynomial (0x1021) , Ini";
BA_ "Version" SG_ 426 CLU_FuelSenderRstReq "23.05.05";
BA_ "RoutingFactor" SG_ 426 CLU_FuelSenderRstReq 0;
BA_ "UserSigValidity" SG_ 426 CLU_FuelSenderRstReq 0;
BA_ "Description" SG_ 426 CLU_FuelSenderRstReq "This signal is transmitted when initailzing request occur";
BA_ "Version" SG_ 426 CLU_AlvCnt1Val "21.09.03";
BA_ "RoutingFactor" SG_ 426 CLU_AlvCnt1Val 0;
BA_ "UserSigValidity" SG_ 426 CLU_AlvCnt1Val 3;
BA_ "Description" SG_ 426 CLU_AlvCnt1Val "For the first transmission request for a data element the counter shall be initialized with 0 and shall be incremented by 1 for every subsequent send request. 

When the counter reaches the maximum value(0xFF), then it shall restart with 0 for the next s";
BA_ "Version" SG_ 426 CLU_DtntOutSta "17.11.00";
BA_ "RoutingFactor" SG_ 426 CLU_DtntOutSta 0;
BA_ "UserSigValidity" SG_ 426 CLU_DtntOutSta 0;
BA_ "Description" SG_ 426 CLU_DtntOutSta "This signal indicates the status of detent illumination. Cluster sends the detent information for a Unified Illumination system.";
BA_ "Version" SG_ 426 CLU_SpdUnitTyp "17.11.00";
BA_ "RoutingFactor" SG_ 426 CLU_SpdUnitTyp 0;
BA_ "UserSigValidity" SG_ 426 CLU_SpdUnitTyp 3;
BA_ "Description" SG_ 426 CLU_SpdUnitTyp "This signal indicates the unit of the speed displayed in the speedometer.";
BA_ "Version" SG_ 426 CLU_DisSpdDcmlVal "17.11.00";
BA_ "RoutingFactor" SG_ 426 CLU_DisSpdDcmlVal 0;
BA_ "UserSigValidity" SG_ 426 CLU_DisSpdDcmlVal 3;
BA_ "Description" SG_ 426 CLU_DisSpdDcmlVal "The signal 'CF_Clu_VanzDecimal' means the extra value of the signal 'CF_Clu_Vanz' (vehicle speed which is indicated in the speedometer)

Also, This signal should be sent in km/h or MPH according to the 'CF_Clu_SPEED_UNIT' signal.

CF_Clu_SPEED_UNIT = 0 :";
BA_ "Version" SG_ 426 CLU_SWRCCrsMainSwSta "18.04.00";
BA_ "RoutingFactor" SG_ 426 CLU_SWRCCrsMainSwSta 0;
BA_ "UserSigValidity" SG_ 426 CLU_SWRCCrsMainSwSta 3;
BA_ "Description" SG_ 426 CLU_SWRCCrsMainSwSta "Cruise on/off switch";
BA_ "Version" SG_ 426 CLU_SWRCCrsSwSta "18.07.01";
BA_ "RoutingFactor" SG_ 426 CLU_SWRCCrsSwSta 0;
BA_ "UserSigValidity" SG_ 426 CLU_SWRCCrsSwSta 3;
BA_ "Description" SG_ 426 CLU_SWRCCrsSwSta "Depending on whether One-touch logic is applied, the meaning of each signal value is divided into two cases as shown below



Case1) Not applied

0x0:Idle Position

0x1:Resume/Plus

0x2:Set/Minus

0x3:Time gap (Distance, SCC only)

0x4:ACC/SCC cancel



";
BA_ "Version" SG_ 426 CLU_SWRCLFASwSta "18.04.00";
BA_ "RoutingFactor" SG_ 426 CLU_SWRCLFASwSta 0;
BA_ "UserSigValidity" SG_ 426 CLU_SWRCLFASwSta 3;
BA_ "Description" SG_ 426 CLU_SWRCLFASwSta "LFA/HDA on/off switch";
BA_ "Version" SG_ 426 CLU_SWRCSldMainSwSta "18.04.00";
BA_ "RoutingFactor" SG_ 426 CLU_SWRCSldMainSwSta 0;
BA_ "UserSigValidity" SG_ 426 CLU_SWRCSldMainSwSta 3;
BA_ "Description" SG_ 426 CLU_SWRCSldMainSwSta "Speedlimiter on/off switch";
BA_ "Version" SG_ 426 CLU_RhstaLvlSta "17.11.00";
BA_ "RoutingFactor" SG_ 426 CLU_RhstaLvlSta 0;
BA_ "UserSigValidity" SG_ 426 CLU_RhstaLvlSta 0;
BA_ "Description" SG_ 426 CLU_RhstaLvlSta "This signal is used for a rheostat level of CLUSTER from 1 to 21 level (21 level : Detent) for a Unified Illumination system.



б╪ Start Value : Current value";
BA_ "Version" SG_ 426 CLU_DisSpdVal "17.12.03";
BA_ "RoutingFactor" SG_ 426 CLU_DisSpdVal 0;
BA_ "UserSigValidity" SG_ 426 CLU_DisSpdVal 3;
BA_ "Description" SG_ 426 CLU_DisSpdVal "The vehicle speed which is indicated in the speedmeter has to be sent to SCC. This value is used for evalution of SCC command values instead of the vehicle velocity in order to avoid significant difference between the speedmeter indicator and the set spe";
BA_ "Version" SG_ 426 CLU_OKSwSta "19.03.06";
BA_ "RoutingFactor" SG_ 426 CLU_OKSwSta 0;
BA_ "UserSigValidity" SG_ 426 CLU_OKSwSta 3;
BA_ "Description" SG_ 426 CLU_OKSwSta "This signal represents operating status of Ok Switch in Steering Wheel. Default value of this signal is 0 and the value is set to 1 only while a driver is pressing the OK Switch.";
BA_ "Version" SG_ 426 CLU_DisSpdVal_KPH "17.12.09";
BA_ "RoutingFactor" SG_ 426 CLU_DisSpdVal_KPH 0;
BA_ "UserSigValidity" SG_ 426 CLU_DisSpdVal_KPH 3;
BA_ "Description" SG_ 426 CLU_DisSpdVal_KPH "The vehicle speed which is indicated in the speedmeter.

This signal should be sent in km/h only.";
BA_ "Version" SG_ 426 CLU_PwrAutoOffResetReq_HCU "19.10.03";
BA_ "RoutingFactor" SG_ 426 CLU_PwrAutoOffResetReq_HCU 0;
BA_ "UserSigValidity" SG_ 426 CLU_PwrAutoOffResetReq_HCU 3;
BA_ "Description" SG_ 426 CLU_PwrAutoOffResetReq_HCU "This signal is used for a request to reset power auto off time

when OK sw on, this signal 0x1 for 3 period times,and send 0x0 

It is signal for HCU";
BA_ "Version" SG_ 426 CLU_CUSTOMSta_NEW "20.08.07";
BA_ "RoutingFactor" SG_ 426 CLU_CUSTOMSta_NEW 0;
BA_ "UserSigValidity" SG_ 426 CLU_CUSTOMSta_NEW 3;
BA_ "Description" SG_ 426 CLU_CUSTOMSta_NEW "This is a signal for New concept CUSTOM mode in AVN USM

This is a confirm signal for selecting CUSTOM mode in AVN USM

And Other units refer this signal when CUSTOM mode (CLU_DrvngModSwSta=0x6

). Other unit decided the Detailed CUSTOM Mode with this si";
BA_ "Version" SG_ 426 CLU_AutoBrightSta "20.12.05";
BA_ "RoutingFactor" SG_ 426 CLU_AutoBrightSta 0;
BA_ "UserSigValidity" SG_ 426 CLU_AutoBrightSta 0;
BA_ "Description" SG_ 426 CLU_AutoBrightSta "This signal is used for a auto bright level of CLUSTER from 1step to 200step for a Unified Illumination system.



б╪ Start Value : Current value";
BA_ "Version" SG_ 426 CLU_NotMinModeBrightSta "22.07.06";
BA_ "RoutingFactor" SG_ 426 CLU_NotMinModeBrightSta 0;
BA_ "UserSigValidity" SG_ 426 CLU_NotMinModeBrightSta 0;
BA_ "Description" SG_ 426 CLU_NotMinModeBrightSta "This signal is used for a Cluster brightness level when not in minimum brightness mode.



б╪ Start Value : Current value";
BA_ "Version" SG_ 426 CLU_FuelSenderResistVal "23.06.00";
BA_ "RoutingFactor" SG_ 426 CLU_FuelSenderResistVal 0;
BA_ "UserSigValidity" SG_ 426 CLU_FuelSenderResistVal 0;
BA_ "Description" SG_ 426 CLU_FuelSenderResistVal "This is the resistance data come from fuel sender.

If fuel sender is open,short condition, Invalid value will be transmitted.

data is valid after cluser waked-up";
BA_ "Version" SG_ 2281701537 L_UWB_BLE_MST_FD_Crc21Val "23.01.02";
BA_ "UserSigValidity" SG_ 2281701537 L_UWB_BLE_MST_FD_Crc21Val 3;
BA_ "GenSigStartValue" SG_ 2281701537 L_UWB_BLE_MST_FD_Crc21Val 65535;
BA_ "GenSigSendType" SG_ 2281701537 L_UWB_BLE_MST_FD_Crc21Val 4;
BA_ "Description" SG_ 2281701537 L_UWB_BLE_MST_FD_Crc21Val "The data area for CRC calculation is based on the data length (DLC) of the message DB.

The CRC shall be calculated over the entire data block (excluding the CRC bytes) including the user data, alive counter and Data ID



- CRC Polynomial (0x1021) , Ini";
BA_ "Version" SG_ 2281701537 MST_SW_MCU_Ver_Major "23.01.02";
BA_ "UserSigValidity" SG_ 2281701537 MST_SW_MCU_Ver_Major 0;
BA_ "GenSigSendType" SG_ 2281701537 MST_SW_MCU_Ver_Major 4;
BA_ "Version" SG_ 2281701537 MST_SW_MCU_Ver_Minor "23.01.02";
BA_ "UserSigValidity" SG_ 2281701537 MST_SW_MCU_Ver_Minor 0;
BA_ "GenSigSendType" SG_ 2281701537 MST_SW_MCU_Ver_Minor 4;
BA_ "Version" SG_ 2281701537 MST_SW_UWB_Ver_Major "23.01.02";
BA_ "UserSigValidity" SG_ 2281701537 MST_SW_UWB_Ver_Major 0;
BA_ "GenSigSendType" SG_ 2281701537 MST_SW_UWB_Ver_Major 4;
BA_ "Version" SG_ 2281701537 MST_SW_UWB_Ver_Minor "23.01.02";
BA_ "UserSigValidity" SG_ 2281701537 MST_SW_UWB_Ver_Minor 0;
BA_ "GenSigSendType" SG_ 2281701537 MST_SW_UWB_Ver_Minor 4;
BA_ "Version" SG_ 2281701537 MST_SW_BLE_Ver_Major "23.01.02";
BA_ "UserSigValidity" SG_ 2281701537 MST_SW_BLE_Ver_Major 0;
BA_ "GenSigSendType" SG_ 2281701537 MST_SW_BLE_Ver_Major 4;
BA_ "Version" SG_ 2281701537 MST_SW_BLE_Ver_Minor "23.01.02";
BA_ "UserSigValidity" SG_ 2281701537 MST_SW_BLE_Ver_Minor 0;
BA_ "GenSigSendType" SG_ 2281701537 MST_SW_BLE_Ver_Minor 4;
BA_ "Version" SG_ 2281701537 MST_UWB_DK_LocalizationStat "23.01.02";
BA_ "UserSigValidity" SG_ 2281701537 MST_UWB_DK_LocalizationStat 0;
BA_ "GenSigSendType" SG_ 2281701537 MST_UWB_DK_LocalizationStat 4;
BA_ "Version" SG_ 2281701537 L_UWB_BLE_MST_FD_AlvCnt21Val "23.01.02";
BA_ "UserSigValidity" SG_ 2281701537 L_UWB_BLE_MST_FD_AlvCnt21Val 3;
BA_ "GenSigSendType" SG_ 2281701537 L_UWB_BLE_MST_FD_AlvCnt21Val 4;
BA_ "Description" SG_ 2281701537 L_UWB_BLE_MST_FD_AlvCnt21Val "For the first transmission request for a data element the counter shall be initialized with 0 and shall be incremented by 1 for every subsequent send request. 

When the counter reaches the maximum value(0xFF), then it shall restart with 0 for the next s";
BA_ "Version" SG_ 2281701537 UWB_Applied_Info "24.04.06";
BA_ "UserSigValidity" SG_ 2281701537 UWB_Applied_Info 0;
BA_ "GenSigSendType" SG_ 2281701537 UWB_Applied_Info 4;
BA_ "Description" SG_ 2281701537 UWB_Applied_Info "Information on UWB Applied in vehicle.

- Bit 0 : UWB_BLE_MST

- Bit 1 : UWB_BLE_SLV1

- Bit 2 : UWB_BLE_SLV2

- Bit 3 : RESERVED

- Bit 4 : RESERVED

- Bit 5 : RESERVED

- Bit 6 : RESERVED

- Bit 7 : RESERVED

- Bit 8 : UWB_FL

- Bit 9 : UWB_FR

- Bit 1";
BA_ "Version" SG_ 2281701537 MST_SW_UWB_2_Ver_Major "24.07.05";
BA_ "UserSigValidity" SG_ 2281701537 MST_SW_UWB_2_Ver_Major 0;
BA_ "GenSigSendType" SG_ 2281701537 MST_SW_UWB_2_Ver_Major 4;
BA_ "Description" SG_ 2281701537 MST_SW_UWB_2_Ver_Major "Indicate the Master SW UWB_2 Version as follows: 

- The major version indicates the release year of the S/W.

- The minor version indicates the release month and sequence number of the S/W.



б╪ Example

MST_SW_UWB_2_Ver_Major : 0x24 -> 2024 year

MST_";
BA_ "Version" SG_ 2281701537 MST_SW_UWB_2_Ver_Minor "24.07.05";
BA_ "UserSigValidity" SG_ 2281701537 MST_SW_UWB_2_Ver_Minor 0;
BA_ "GenSigSendType" SG_ 2281701537 MST_SW_UWB_2_Ver_Minor 4;
BA_ "Description" SG_ 2281701537 MST_SW_UWB_2_Ver_Minor "Indicate the Master SW UWB_2 Version as follows: 

- The major version indicates the release year of the S/W.

- The minor version indicates the release month and sequence number of the S/W.



б╪ Example

MST_SW_UWB_2_Ver_Major : 0x24 -> 2024 year

MST_";
BA_ "Version" SG_ 2281701537 MST_UWB_Status1 "24.04.04";
BA_ "UserSigValidity" SG_ 2281701537 MST_UWB_Status1 0;
BA_ "GenSigSendType" SG_ 2281701537 MST_UWB_Status1 4;
BA_ "Description" SG_ 2281701537 MST_UWB_Status1 "UWB_MASTER Processing Status 1";
BA_ "Version" SG_ 2281701537 MST_UWB_Status2 "24.04.04";
BA_ "UserSigValidity" SG_ 2281701537 MST_UWB_Status2 0;
BA_ "GenSigSendType" SG_ 2281701537 MST_UWB_Status2 4;
BA_ "Description" SG_ 2281701537 MST_UWB_Status2 "UWB_MASTER Processing Status 2";
BA_ "Version" SG_ 2281701537 MST_UWB_Status3 "24.04.04";
BA_ "UserSigValidity" SG_ 2281701537 MST_UWB_Status3 0;
BA_ "GenSigSendType" SG_ 2281701537 MST_UWB_Status3 4;
BA_ "Description" SG_ 2281701537 MST_UWB_Status3 "UWB_MASTER Processing Status 3";
BA_ "Version" SG_ 2281701537 MST_UWB_Status4 "24.04.04";
BA_ "UserSigValidity" SG_ 2281701537 MST_UWB_Status4 0;
BA_ "GenSigSendType" SG_ 2281701537 MST_UWB_Status4 4;
BA_ "Description" SG_ 2281701537 MST_UWB_Status4 "UWB_MASTER Processing Status 4";
BA_ "Version" SG_ 2281701537 MST_UWB_Status5 "24.04.04";
BA_ "UserSigValidity" SG_ 2281701537 MST_UWB_Status5 0;
BA_ "GenSigSendType" SG_ 2281701537 MST_UWB_Status5 4;
BA_ "Description" SG_ 2281701537 MST_UWB_Status5 "UWB_MASTER Processing Status 5";
BA_ "Version" SG_ 2281701537 MST_UWB_Status6 "24.04.04";
BA_ "UserSigValidity" SG_ 2281701537 MST_UWB_Status6 0;
BA_ "GenSigSendType" SG_ 2281701537 MST_UWB_Status6 4;
BA_ "Description" SG_ 2281701537 MST_UWB_Status6 "UWB_MASTER Processing Status 6";
BA_ "Version" SG_ 2281701537 MST_UWB_Status7 "24.04.04";
BA_ "UserSigValidity" SG_ 2281701537 MST_UWB_Status7 0;
BA_ "GenSigSendType" SG_ 2281701537 MST_UWB_Status7 4;
BA_ "Description" SG_ 2281701537 MST_UWB_Status7 "UWB_MASTER Processing Status 7";
BA_ "Version" SG_ 2281701537 MST_UWB_Status8 "24.04.04";
BA_ "UserSigValidity" SG_ 2281701537 MST_UWB_Status8 0;
BA_ "GenSigSendType" SG_ 2281701537 MST_UWB_Status8 4;
BA_ "Description" SG_ 2281701537 MST_UWB_Status8 "UWB_MASTER Processing Status 8";
BA_ "Version" SG_ 2281701537 MST_UWB_Status9 "24.04.04";
BA_ "UserSigValidity" SG_ 2281701537 MST_UWB_Status9 0;
BA_ "GenSigSendType" SG_ 2281701537 MST_UWB_Status9 4;
BA_ "Description" SG_ 2281701537 MST_UWB_Status9 "UWB_MASTER Processing Status 9";
BA_ "Version" SG_ 2281701537 MST_UWB_Status10 "24.04.04";
BA_ "UserSigValidity" SG_ 2281701537 MST_UWB_Status10 0;
BA_ "GenSigSendType" SG_ 2281701537 MST_UWB_Status10 4;
BA_ "Description" SG_ 2281701537 MST_UWB_Status10 "UWB_MASTER Processing Status 10";
BA_ "Version" SG_ 2281701537 MST_UWB_Status11 "24.04.04";
BA_ "UserSigValidity" SG_ 2281701537 MST_UWB_Status11 0;
BA_ "GenSigSendType" SG_ 2281701537 MST_UWB_Status11 4;
BA_ "Description" SG_ 2281701537 MST_UWB_Status11 "UWB_MASTER Processing Status 11";
BA_ "Version" SG_ 2281701537 MST_UWB_Status12 "24.04.04";
BA_ "UserSigValidity" SG_ 2281701537 MST_UWB_Status12 0;
BA_ "GenSigSendType" SG_ 2281701537 MST_UWB_Status12 4;
BA_ "Description" SG_ 2281701537 MST_UWB_Status12 "UWB_MASTER Processing Status 12";
BA_ "Version" SG_ 2281701537 MST_UWB_Status13 "24.04.04";
BA_ "UserSigValidity" SG_ 2281701537 MST_UWB_Status13 0;
BA_ "GenSigSendType" SG_ 2281701537 MST_UWB_Status13 4;
BA_ "Description" SG_ 2281701537 MST_UWB_Status13 "UWB_MASTER Processing Status 13";
BA_ "Version" SG_ 2281701537 MST_UWB_Status14 "24.04.04";
BA_ "UserSigValidity" SG_ 2281701537 MST_UWB_Status14 0;
BA_ "GenSigSendType" SG_ 2281701537 MST_UWB_Status14 4;
BA_ "Description" SG_ 2281701537 MST_UWB_Status14 "UWB_MASTER Processing Status 14";
BA_ "Version" SG_ 2281701537 MST_UWB_Status15 "24.04.04";
BA_ "UserSigValidity" SG_ 2281701537 MST_UWB_Status15 0;
BA_ "GenSigSendType" SG_ 2281701537 MST_UWB_Status15 4;
BA_ "Description" SG_ 2281701537 MST_UWB_Status15 "UWB_MASTER Processing Status 15";
BA_ "Version" SG_ 2281701537 MST_UWB_Status16 "24.04.04";
BA_ "UserSigValidity" SG_ 2281701537 MST_UWB_Status16 0;
BA_ "GenSigSendType" SG_ 2281701537 MST_UWB_Status16 4;
BA_ "Description" SG_ 2281701537 MST_UWB_Status16 "UWB_MASTER Processing Status 16";
BA_ "Version" SG_ 2281701537 MST_HW_Ver_Major "23.01.02";
BA_ "UserSigValidity" SG_ 2281701537 MST_HW_Ver_Major 0;
BA_ "GenSigSendType" SG_ 2281701537 MST_HW_Ver_Major 4;
BA_ "Version" SG_ 2281701537 MST_HW_Ver_Minor "23.01.02";
BA_ "UserSigValidity" SG_ 2281701537 MST_HW_Ver_Minor 0;
BA_ "GenSigSendType" SG_ 2281701537 MST_HW_Ver_Minor 4;
BA_ "Version" SG_ 1504 GST_ROA_Byte0 "21.02.04";
BA_ "NetworkRequestHoldingTime" SG_ 1504 GST_ROA_Byte0 5000;
BA_ "NetworkRequest" SG_ 1504 GST_ROA_Byte0 0;
BA_ "UserSigValidity" SG_ 1504 GST_ROA_Byte0 0;
BA_ "UsrSigPurpose" SG_ 1504 GST_ROA_Byte0 3;
BA_ "Description" SG_ 1504 GST_ROA_Byte0 "TP Index : 162";
BA_ "Version" SG_ 1504 GST_ROA_Byte2 "21.02.04";
BA_ "NetworkRequestHoldingTime" SG_ 1504 GST_ROA_Byte2 5000;
BA_ "NetworkRequest" SG_ 1504 GST_ROA_Byte2 0;
BA_ "UserSigValidity" SG_ 1504 GST_ROA_Byte2 0;
BA_ "UsrSigPurpose" SG_ 1504 GST_ROA_Byte2 3;
BA_ "Description" SG_ 1504 GST_ROA_Byte2 "TP Index : 162";
BA_ "Version" SG_ 1504 GST_ROA_Byte3 "21.02.04";
BA_ "NetworkRequestHoldingTime" SG_ 1504 GST_ROA_Byte3 5000;
BA_ "NetworkRequest" SG_ 1504 GST_ROA_Byte3 0;
BA_ "UserSigValidity" SG_ 1504 GST_ROA_Byte3 0;
BA_ "UsrSigPurpose" SG_ 1504 GST_ROA_Byte3 3;
BA_ "Description" SG_ 1504 GST_ROA_Byte3 "TP Index : 162";
BA_ "Version" SG_ 1504 GST_ROA_Byte4 "21.02.04";
BA_ "NetworkRequestHoldingTime" SG_ 1504 GST_ROA_Byte4 5000;
BA_ "NetworkRequest" SG_ 1504 GST_ROA_Byte4 0;
BA_ "UserSigValidity" SG_ 1504 GST_ROA_Byte4 0;
BA_ "UsrSigPurpose" SG_ 1504 GST_ROA_Byte4 3;
BA_ "Description" SG_ 1504 GST_ROA_Byte4 "TP Index : 162";
BA_ "Version" SG_ 1504 GST_ROA_Byte5 "21.02.04";
BA_ "NetworkRequestHoldingTime" SG_ 1504 GST_ROA_Byte5 5000;
BA_ "NetworkRequest" SG_ 1504 GST_ROA_Byte5 0;
BA_ "UserSigValidity" SG_ 1504 GST_ROA_Byte5 0;
BA_ "UsrSigPurpose" SG_ 1504 GST_ROA_Byte5 3;
BA_ "Description" SG_ 1504 GST_ROA_Byte5 "TP Index : 162";
BA_ "Version" SG_ 1504 GST_ROA_Byte6 "21.02.04";
BA_ "NetworkRequestHoldingTime" SG_ 1504 GST_ROA_Byte6 5000;
BA_ "NetworkRequest" SG_ 1504 GST_ROA_Byte6 0;
BA_ "UserSigValidity" SG_ 1504 GST_ROA_Byte6 0;
BA_ "UsrSigPurpose" SG_ 1504 GST_ROA_Byte6 3;
BA_ "Description" SG_ 1504 GST_ROA_Byte6 "TP Index : 162";
BA_ "Version" SG_ 1504 GST_ROA_Byte7 "21.02.04";
BA_ "NetworkRequestHoldingTime" SG_ 1504 GST_ROA_Byte7 5000;
BA_ "NetworkRequest" SG_ 1504 GST_ROA_Byte7 0;
BA_ "UserSigValidity" SG_ 1504 GST_ROA_Byte7 0;
BA_ "UsrSigPurpose" SG_ 1504 GST_ROA_Byte7 3;
BA_ "Description" SG_ 1504 GST_ROA_Byte7 "TP Index : 162";
BA_ "Version" SG_ 1504 GST_ROA_Byte1 "21.02.04";
BA_ "NetworkRequestHoldingTime" SG_ 1504 GST_ROA_Byte1 5000;
BA_ "NetworkRequest" SG_ 1504 GST_ROA_Byte1 0;
BA_ "UserSigValidity" SG_ 1504 GST_ROA_Byte1 0;
BA_ "UsrSigPurpose" SG_ 1504 GST_ROA_Byte1 3;
BA_ "Description" SG_ 1504 GST_ROA_Byte1 "TP Index : 162";
BA_ "Version" SG_ 1512 ROA_GST_Byte0 "22.07.01";
BA_ "NetworkRequestHoldingTime" SG_ 1512 ROA_GST_Byte0 5000;
BA_ "NetworkRequest" SG_ 1512 ROA_GST_Byte0 0;
BA_ "UserSigValidity" SG_ 1512 ROA_GST_Byte0 0;
BA_ "UsrSigPurpose" SG_ 1512 ROA_GST_Byte0 4;
BA_ "Description" SG_ 1512 ROA_GST_Byte0 "TP Index : 162";
BA_ "Version" SG_ 1512 ROA_GST_Byte2 "22.07.01";
BA_ "NetworkRequestHoldingTime" SG_ 1512 ROA_GST_Byte2 5000;
BA_ "NetworkRequest" SG_ 1512 ROA_GST_Byte2 0;
BA_ "UserSigValidity" SG_ 1512 ROA_GST_Byte2 0;
BA_ "UsrSigPurpose" SG_ 1512 ROA_GST_Byte2 4;
BA_ "Description" SG_ 1512 ROA_GST_Byte2 "TP Index : 162";
BA_ "Version" SG_ 1512 ROA_GST_Byte3 "22.07.01";
BA_ "NetworkRequestHoldingTime" SG_ 1512 ROA_GST_Byte3 5000;
BA_ "NetworkRequest" SG_ 1512 ROA_GST_Byte3 0;
BA_ "UserSigValidity" SG_ 1512 ROA_GST_Byte3 0;
BA_ "UsrSigPurpose" SG_ 1512 ROA_GST_Byte3 4;
BA_ "Description" SG_ 1512 ROA_GST_Byte3 "TP Index : 162";
BA_ "Version" SG_ 1512 ROA_GST_Byte4 "22.07.01";
BA_ "NetworkRequestHoldingTime" SG_ 1512 ROA_GST_Byte4 5000;
BA_ "NetworkRequest" SG_ 1512 ROA_GST_Byte4 0;
BA_ "UserSigValidity" SG_ 1512 ROA_GST_Byte4 0;
BA_ "UsrSigPurpose" SG_ 1512 ROA_GST_Byte4 4;
BA_ "Description" SG_ 1512 ROA_GST_Byte4 "TP Index : 162";
BA_ "Version" SG_ 1512 ROA_GST_Byte5 "22.07.01";
BA_ "NetworkRequestHoldingTime" SG_ 1512 ROA_GST_Byte5 5000;
BA_ "NetworkRequest" SG_ 1512 ROA_GST_Byte5 0;
BA_ "UserSigValidity" SG_ 1512 ROA_GST_Byte5 0;
BA_ "UsrSigPurpose" SG_ 1512 ROA_GST_Byte5 4;
BA_ "Description" SG_ 1512 ROA_GST_Byte5 "TP Index : 162";
BA_ "Version" SG_ 1512 ROA_GST_Byte6 "22.07.01";
BA_ "NetworkRequestHoldingTime" SG_ 1512 ROA_GST_Byte6 5000;
BA_ "NetworkRequest" SG_ 1512 ROA_GST_Byte6 0;
BA_ "UserSigValidity" SG_ 1512 ROA_GST_Byte6 0;
BA_ "UsrSigPurpose" SG_ 1512 ROA_GST_Byte6 4;
BA_ "Description" SG_ 1512 ROA_GST_Byte6 "TP Index : 162";
BA_ "Version" SG_ 1512 ROA_GST_Byte7 "22.07.01";
BA_ "NetworkRequestHoldingTime" SG_ 1512 ROA_GST_Byte7 5000;
BA_ "NetworkRequest" SG_ 1512 ROA_GST_Byte7 0;
BA_ "UserSigValidity" SG_ 1512 ROA_GST_Byte7 0;
BA_ "UsrSigPurpose" SG_ 1512 ROA_GST_Byte7 4;
BA_ "Description" SG_ 1512 ROA_GST_Byte7 "TP Index : 162";
BA_ "Version" SG_ 1512 ROA_GST_Byte1 "22.07.01";
BA_ "NetworkRequestHoldingTime" SG_ 1512 ROA_GST_Byte1 5000;
BA_ "NetworkRequest" SG_ 1512 ROA_GST_Byte1 0;
BA_ "UserSigValidity" SG_ 1512 ROA_GST_Byte1 0;
BA_ "UsrSigPurpose" SG_ 1512 ROA_GST_Byte1 4;
BA_ "Description" SG_ 1512 ROA_GST_Byte1 "TP Index : 162";
BA_ "Version" SG_ 2281701584 L_UWB_FR_FD_Crc10Val "23.01.02";
BA_ "UserSigValidity" SG_ 2281701584 L_UWB_FR_FD_Crc10Val 3;
BA_ "GenSigStartValue" SG_ 2281701584 L_UWB_FR_FD_Crc10Val 65535;
BA_ "GenSigSendType" SG_ 2281701584 L_UWB_FR_FD_Crc10Val 4;
BA_ "Description" SG_ 2281701584 L_UWB_FR_FD_Crc10Val "The data area for CRC calculation is based on the data length (DLC) of the message DB.

The CRC shall be calculated over the entire data block (excluding the CRC bytes) including the user data, alive counter and Data ID



- CRC Polynomial (0x1021) , Ini";
BA_ "Version" SG_ 2281701584 UWB_FR_SW_MCU_Ver_Major "23.01.02";
BA_ "UserSigValidity" SG_ 2281701584 UWB_FR_SW_MCU_Ver_Major 0;
BA_ "GenSigSendType" SG_ 2281701584 UWB_FR_SW_MCU_Ver_Major 4;
BA_ "Version" SG_ 2281701584 UWB_FR_SW_MCU_Ver_Minor "23.01.02";
BA_ "UserSigValidity" SG_ 2281701584 UWB_FR_SW_MCU_Ver_Minor 0;
BA_ "GenSigSendType" SG_ 2281701584 UWB_FR_SW_MCU_Ver_Minor 4;
BA_ "Version" SG_ 2281701584 UWB_FR_SW_IC_Ver_Major "23.01.02";
BA_ "UserSigValidity" SG_ 2281701584 UWB_FR_SW_IC_Ver_Major 0;
BA_ "GenSigSendType" SG_ 2281701584 UWB_FR_SW_IC_Ver_Major 4;
BA_ "Version" SG_ 2281701584 UWB_FR_SW_IC_Ver_Minor "23.01.02";
BA_ "UserSigValidity" SG_ 2281701584 UWB_FR_SW_IC_Ver_Minor 0;
BA_ "GenSigSendType" SG_ 2281701584 UWB_FR_SW_IC_Ver_Minor 4;
BA_ "Version" SG_ 2281701584 UWB_FR_DTC "23.01.02";
BA_ "UserSigValidity" SG_ 2281701584 UWB_FR_DTC 0;
BA_ "GenSigSendType" SG_ 2281701584 UWB_FR_DTC 4;
BA_ "Version" SG_ 2281701584 L_UWB_FR_FD_AlvCnt10Val "23.01.02";
BA_ "UserSigValidity" SG_ 2281701584 L_UWB_FR_FD_AlvCnt10Val 3;
BA_ "GenSigSendType" SG_ 2281701584 L_UWB_FR_FD_AlvCnt10Val 4;
BA_ "Description" SG_ 2281701584 L_UWB_FR_FD_AlvCnt10Val "For the first transmission request for a data element the counter shall be initialized with 0 and shall be incremented by 1 for every subsequent send request. 

When the counter reaches the maximum value(0xFF), then it shall restart with 0 for the next s";
BA_ "Version" SG_ 2281701584 UWB_FR_Status1 "24.04.04";
BA_ "UserSigValidity" SG_ 2281701584 UWB_FR_Status1 0;
BA_ "GenSigSendType" SG_ 2281701584 UWB_FR_Status1 4;
BA_ "Description" SG_ 2281701584 UWB_FR_Status1 "UWB_FR Processing Status 1";
BA_ "Version" SG_ 2281701584 UWB_FR_Status2 "24.04.04";
BA_ "UserSigValidity" SG_ 2281701584 UWB_FR_Status2 0;
BA_ "GenSigSendType" SG_ 2281701584 UWB_FR_Status2 4;
BA_ "Description" SG_ 2281701584 UWB_FR_Status2 "UWB_FR Processing Status 2";
BA_ "Version" SG_ 2281701584 UWB_FR_Status3 "24.04.04";
BA_ "UserSigValidity" SG_ 2281701584 UWB_FR_Status3 0;
BA_ "GenSigSendType" SG_ 2281701584 UWB_FR_Status3 4;
BA_ "Description" SG_ 2281701584 UWB_FR_Status3 "UWB_FR Processing Status 3";
BA_ "Version" SG_ 2281701584 UWB_FR_Status4 "24.04.04";
BA_ "UserSigValidity" SG_ 2281701584 UWB_FR_Status4 0;
BA_ "GenSigSendType" SG_ 2281701584 UWB_FR_Status4 4;
BA_ "Description" SG_ 2281701584 UWB_FR_Status4 "UWB_FR Processing Status 4";
BA_ "Version" SG_ 2281701584 UWB_FR_Status5 "24.04.04";
BA_ "UserSigValidity" SG_ 2281701584 UWB_FR_Status5 0;
BA_ "GenSigSendType" SG_ 2281701584 UWB_FR_Status5 4;
BA_ "Description" SG_ 2281701584 UWB_FR_Status5 "UWB_FR Processing Status 5";
BA_ "Version" SG_ 2281701584 UWB_FR_Status6 "24.04.04";
BA_ "UserSigValidity" SG_ 2281701584 UWB_FR_Status6 0;
BA_ "GenSigSendType" SG_ 2281701584 UWB_FR_Status6 4;
BA_ "Description" SG_ 2281701584 UWB_FR_Status6 "UWB_FR Processing Status 6";
BA_ "Version" SG_ 2281701584 UWB_FR_Status7 "24.04.04";
BA_ "UserSigValidity" SG_ 2281701584 UWB_FR_Status7 0;
BA_ "GenSigSendType" SG_ 2281701584 UWB_FR_Status7 4;
BA_ "Description" SG_ 2281701584 UWB_FR_Status7 "UWB_FR Processing Status 7";
BA_ "Version" SG_ 2281701584 UWB_FR_Status8 "24.04.04";
BA_ "UserSigValidity" SG_ 2281701584 UWB_FR_Status8 0;
BA_ "GenSigSendType" SG_ 2281701584 UWB_FR_Status8 4;
BA_ "Description" SG_ 2281701584 UWB_FR_Status8 "UWB_FR Processing Status 8";
BA_ "Version" SG_ 2281701584 UWB_FR_Status9 "24.04.04";
BA_ "UserSigValidity" SG_ 2281701584 UWB_FR_Status9 0;
BA_ "GenSigSendType" SG_ 2281701584 UWB_FR_Status9 4;
BA_ "Description" SG_ 2281701584 UWB_FR_Status9 "UWB_FR Processing Status 9";
BA_ "Version" SG_ 2281701584 UWB_FR_Status10 "24.04.04";
BA_ "UserSigValidity" SG_ 2281701584 UWB_FR_Status10 0;
BA_ "GenSigSendType" SG_ 2281701584 UWB_FR_Status10 4;
BA_ "Description" SG_ 2281701584 UWB_FR_Status10 "UWB_FR Processing Status 10";
BA_ "Version" SG_ 2281701584 UWB_FR_Status11 "24.04.04";
BA_ "UserSigValidity" SG_ 2281701584 UWB_FR_Status11 0;
BA_ "GenSigSendType" SG_ 2281701584 UWB_FR_Status11 4;
BA_ "Description" SG_ 2281701584 UWB_FR_Status11 "UWB_FR Processing Status 11";
BA_ "Version" SG_ 2281701584 UWB_FR_Status12 "24.04.04";
BA_ "UserSigValidity" SG_ 2281701584 UWB_FR_Status12 0;
BA_ "GenSigSendType" SG_ 2281701584 UWB_FR_Status12 4;
BA_ "Description" SG_ 2281701584 UWB_FR_Status12 "UWB_FR Processing Status 12";
BA_ "Version" SG_ 2281701584 UWB_FR_Status13 "24.04.04";
BA_ "UserSigValidity" SG_ 2281701584 UWB_FR_Status13 0;
BA_ "GenSigSendType" SG_ 2281701584 UWB_FR_Status13 4;
BA_ "Description" SG_ 2281701584 UWB_FR_Status13 "UWB_FR Processing Status 13";
BA_ "Version" SG_ 2281701584 UWB_FR_Status14 "24.04.04";
BA_ "UserSigValidity" SG_ 2281701584 UWB_FR_Status14 0;
BA_ "GenSigSendType" SG_ 2281701584 UWB_FR_Status14 4;
BA_ "Description" SG_ 2281701584 UWB_FR_Status14 "UWB_FR Processing Status 14";
BA_ "Version" SG_ 2281701584 UWB_FR_Status15 "24.04.04";
BA_ "UserSigValidity" SG_ 2281701584 UWB_FR_Status15 0;
BA_ "GenSigSendType" SG_ 2281701584 UWB_FR_Status15 4;
BA_ "Description" SG_ 2281701584 UWB_FR_Status15 "UWB_FR Processing Status 15";
BA_ "Version" SG_ 2281701584 UWB_FR_Status16 "24.04.04";
BA_ "UserSigValidity" SG_ 2281701584 UWB_FR_Status16 0;
BA_ "GenSigSendType" SG_ 2281701584 UWB_FR_Status16 4;
BA_ "Description" SG_ 2281701584 UWB_FR_Status16 "UWB_FR Processing Status 16";
BA_ "Version" SG_ 2281701584 UWB_FR_HW_Ver_Major "23.01.02";
BA_ "UserSigValidity" SG_ 2281701584 UWB_FR_HW_Ver_Major 0;
BA_ "GenSigSendType" SG_ 2281701584 UWB_FR_HW_Ver_Major 4;
BA_ "Version" SG_ 2281701584 UWB_FR_HW_Ver_Minor "23.01.02";
BA_ "UserSigValidity" SG_ 2281701584 UWB_FR_HW_Ver_Minor 0;
BA_ "GenSigSendType" SG_ 2281701584 UWB_FR_HW_Ver_Minor 4;
BA_ "Version" SG_ 2348810256 L_TPMS_FD_Crc1Val "24.08.06";
BA_ "UserSigValidity" SG_ 2348810256 L_TPMS_FD_Crc1Val 3;
BA_ "GenSigStartValue" SG_ 2348810256 L_TPMS_FD_Crc1Val 65535;
BA_ "GenSigSendType" SG_ 2348810256 L_TPMS_FD_Crc1Val 4;
BA_ "Description" SG_ 2348810256 L_TPMS_FD_Crc1Val "The data area for CRC calculation is based on the data length (DLC) of the message DB.

The CRC shall be calculated over the entire data block (excluding the CRC bytes) including the user data, alive counter and Data ID



- CRC Polynomial (0x1021) , Ini";
BA_ "Version" SG_ 2348810256 TPMS_TpsSnsrDataVal "24.08.06";
BA_ "UserSigValidity" SG_ 2348810256 TPMS_TpsSnsrDataVal 3;
BA_ "GenSigSendType" SG_ 2348810256 TPMS_TpsSnsrDataVal 4;
BA_ "Description" SG_ 2348810256 TPMS_TpsSnsrDataVal "Received sensor data transmission signal(FL/FR/RL/RR)

0x0~0xFFFFFFFFFFFFFFFFFFFFFFFFFF:SensorData";
BA_ "Version" SG_ 2348810256 L_TPMS_FD_AlvCnt1Val "24.08.06";
BA_ "UserSigValidity" SG_ 2348810256 L_TPMS_FD_AlvCnt1Val 3;
BA_ "GenSigSendType" SG_ 2348810256 L_TPMS_FD_AlvCnt1Val 4;
BA_ "Description" SG_ 2348810256 L_TPMS_FD_AlvCnt1Val "For the first transmission request for a data element the counter shall be initialized with 0 and shall be incremented by 1 for every subsequent send request. 

When the counter reaches the maximum value(0xFF), then it shall restart with 0 for the next s";
BA_ "Version" SG_ 2348810256 TPMS_SensorRssiVal "24.08.06";
BA_ "UserSigValidity" SG_ 2348810256 TPMS_SensorRssiVal 3;
BA_ "GenSigSendType" SG_ 2348810256 TPMS_SensorRssiVal 4;
BA_ "Description" SG_ 2348810256 TPMS_SensorRssiVal "Sensor RSSI value";
BA_ "Version" SG_ 2348810256 TPMS_LastTpsSnsrDataVal "24.08.06";
BA_ "UserSigValidity" SG_ 2348810256 TPMS_LastTpsSnsrDataVal 0;
BA_ "GenSigSendType" SG_ 2348810256 TPMS_LastTpsSnsrDataVal 4;
BA_ "Description" SG_ 2348810256 TPMS_LastTpsSnsrDataVal "Final received sensor data transmission signal(FL/FR/RL/RR)

0x0~0xFFFFFFFFFFFFFFFFFFFFFFFFFF:SensorData";
BA_ "Version" SG_ 2348810257 L_TPMS_FD_Crc2Val "24.07.06";
BA_ "UserSigValidity" SG_ 2348810257 L_TPMS_FD_Crc2Val 3;
BA_ "GenSigStartValue" SG_ 2348810257 L_TPMS_FD_Crc2Val 65535;
BA_ "GenSigSendType" SG_ 2348810257 L_TPMS_FD_Crc2Val 4;
BA_ "Description" SG_ 2348810257 L_TPMS_FD_Crc2Val "The data area for CRC calculation is based on the data length (DLC) of the message DB.

The CRC shall be calculated over the entire data block (excluding the CRC bytes) including the user data, alive counter and Data ID



- CRC Polynomial (0x1021) , Ini";
BA_ "Version" SG_ 2348810257 L_TPMS_FD_AlvCnt2Val "24.07.06";
BA_ "UserSigValidity" SG_ 2348810257 L_TPMS_FD_AlvCnt2Val 3;
BA_ "GenSigSendType" SG_ 2348810257 L_TPMS_FD_AlvCnt2Val 4;
BA_ "Description" SG_ 2348810257 L_TPMS_FD_AlvCnt2Val "For the first transmission request for a data element the counter shall be initialized with 0 and shall be incremented by 1 for every subsequent send request. 

When the counter reaches the maximum value(0xFF), then it shall restart with 0 for the next s";
BA_ "Version" SG_ 2348810257 TPMS_RficErrStatus "23.07.03";
BA_ "UserSigValidity" SG_ 2348810257 TPMS_RficErrStatus 3;
BA_ "GenSigSendType" SG_ 2348810257 TPMS_RficErrStatus 4;
BA_ "Description" SG_ 2348810257 TPMS_RficErrStatus "RF IC Fail status";
BA_ "Version" SG_ 2348810257 TPMS_NoiseRssiVal "23.07.03";
BA_ "UserSigValidity" SG_ 2348810257 TPMS_NoiseRssiVal 3;
BA_ "GenSigSendType" SG_ 2348810257 TPMS_NoiseRssiVal 4;
BA_ "Description" SG_ 2348810257 TPMS_NoiseRssiVal "Noise RSSI value";
BA_ "Version" SG_ 2533736449 L_UWB_TRNK_FD_Crc4Val "24.07.05";
BA_ "RoutingFactor" SG_ 2533736449 L_UWB_TRNK_FD_Crc4Val 0;
BA_ "UserSigValidity" SG_ 2533736449 L_UWB_TRNK_FD_Crc4Val 3;
BA_ "GenSigStartValue" SG_ 2533736449 L_UWB_TRNK_FD_Crc4Val 65535;
BA_ "GenSigSendType" SG_ 2533736449 L_UWB_TRNK_FD_Crc4Val 2;
BA_ "Description" SG_ 2533736449 L_UWB_TRNK_FD_Crc4Val "The data area for CRC calculation is based on the data length (DLC) of the message DB.

The CRC shall be calculated over the entire data block (excluding the CRC bytes) including the user data, alive counter and Data ID



- CRC Polynomial (0x1021) , Ini";
BA_ "Version" SG_ 2533736449 L_UWB_TRNK_FD_AlvCnt4Val "24.07.05";
BA_ "RoutingFactor" SG_ 2533736449 L_UWB_TRNK_FD_AlvCnt4Val 0;
BA_ "UserSigValidity" SG_ 2533736449 L_UWB_TRNK_FD_AlvCnt4Val 3;
BA_ "GenSigSendType" SG_ 2533736449 L_UWB_TRNK_FD_AlvCnt4Val 2;
BA_ "Description" SG_ 2533736449 L_UWB_TRNK_FD_AlvCnt4Val "For the first transmission request for a data element the counter shall be initialized with 0 and shall be incremented by 1 for every subsequent send request. 

When the counter reaches the maximum value(0xFF), then it shall restart with 0 for the next s";
BA_ "Version" SG_ 2533736449 TRNK_SWID_3_IVD_1 "24.07.05";
BA_ "RoutingFactor" SG_ 2533736449 TRNK_SWID_3_IVD_1 0;
BA_ "UserSigValidity" SG_ 2533736449 TRNK_SWID_3_IVD_1 0;
BA_ "GenSigSendType" SG_ 2533736449 TRNK_SWID_3_IVD_1 2;
BA_ "Version" SG_ 2529538049 L_UWB_RL_FD_Crc4Val "24.07.05";
BA_ "RoutingFactor" SG_ 2529538049 L_UWB_RL_FD_Crc4Val 0;
BA_ "UserSigValidity" SG_ 2529538049 L_UWB_RL_FD_Crc4Val 3;
BA_ "GenSigStartValue" SG_ 2529538049 L_UWB_RL_FD_Crc4Val 65535;
BA_ "GenSigSendType" SG_ 2529538049 L_UWB_RL_FD_Crc4Val 2;
BA_ "Description" SG_ 2529538049 L_UWB_RL_FD_Crc4Val "The data area for CRC calculation is based on the data length (DLC) of the message DB.

The CRC shall be calculated over the entire data block (excluding the CRC bytes) including the user data, alive counter and Data ID



- CRC Polynomial (0x1021) , Ini";
BA_ "Version" SG_ 2529538049 L_UWB_RL_FD_AlvCnt4Val "24.07.05";
BA_ "RoutingFactor" SG_ 2529538049 L_UWB_RL_FD_AlvCnt4Val 0;
BA_ "UserSigValidity" SG_ 2529538049 L_UWB_RL_FD_AlvCnt4Val 3;
BA_ "GenSigSendType" SG_ 2529538049 L_UWB_RL_FD_AlvCnt4Val 2;
BA_ "Description" SG_ 2529538049 L_UWB_RL_FD_AlvCnt4Val "For the first transmission request for a data element the counter shall be initialized with 0 and shall be incremented by 1 for every subsequent send request. 

When the counter reaches the maximum value(0xFF), then it shall restart with 0 for the next s";
BA_ "Version" SG_ 2529538049 RL_SWID_3_IVD_1 "24.07.05";
BA_ "RoutingFactor" SG_ 2529538049 RL_SWID_3_IVD_1 0;
BA_ "UserSigValidity" SG_ 2529538049 RL_SWID_3_IVD_1 0;
BA_ "GenSigSendType" SG_ 2529538049 RL_SWID_3_IVD_1 2;
BA_ "Version" SG_ 1410 GST_UWB_BLE_Master_Byte0 "21.05.02";
BA_ "NetworkRequestHoldingTime" SG_ 1410 GST_UWB_BLE_Master_Byte0 5000;
BA_ "NetworkRequest" SG_ 1410 GST_UWB_BLE_Master_Byte0 0;
BA_ "UserSigValidity" SG_ 1410 GST_UWB_BLE_Master_Byte0 0;
BA_ "UsrSigPurpose" SG_ 1410 GST_UWB_BLE_Master_Byte0 3;
BA_ "Description" SG_ 1410 GST_UWB_BLE_Master_Byte0 "TP Index : 95";
BA_ "Version" SG_ 1410 GST_UWB_BLE_Master_Byte2 "21.05.02";
BA_ "NetworkRequestHoldingTime" SG_ 1410 GST_UWB_BLE_Master_Byte2 5000;
BA_ "NetworkRequest" SG_ 1410 GST_UWB_BLE_Master_Byte2 0;
BA_ "UserSigValidity" SG_ 1410 GST_UWB_BLE_Master_Byte2 0;
BA_ "UsrSigPurpose" SG_ 1410 GST_UWB_BLE_Master_Byte2 3;
BA_ "Description" SG_ 1410 GST_UWB_BLE_Master_Byte2 "TP Index : 95";
BA_ "Version" SG_ 1410 GST_UWB_BLE_Master_Byte3 "21.05.02";
BA_ "NetworkRequestHoldingTime" SG_ 1410 GST_UWB_BLE_Master_Byte3 5000;
BA_ "NetworkRequest" SG_ 1410 GST_UWB_BLE_Master_Byte3 0;
BA_ "UserSigValidity" SG_ 1410 GST_UWB_BLE_Master_Byte3 0;
BA_ "UsrSigPurpose" SG_ 1410 GST_UWB_BLE_Master_Byte3 3;
BA_ "Description" SG_ 1410 GST_UWB_BLE_Master_Byte3 "TP Index : 95";
BA_ "Version" SG_ 1410 GST_UWB_BLE_Master_Byte4 "21.05.02";
BA_ "NetworkRequestHoldingTime" SG_ 1410 GST_UWB_BLE_Master_Byte4 5000;
BA_ "NetworkRequest" SG_ 1410 GST_UWB_BLE_Master_Byte4 0;
BA_ "UserSigValidity" SG_ 1410 GST_UWB_BLE_Master_Byte4 0;
BA_ "UsrSigPurpose" SG_ 1410 GST_UWB_BLE_Master_Byte4 3;
BA_ "Description" SG_ 1410 GST_UWB_BLE_Master_Byte4 "TP Index : 95";
BA_ "Version" SG_ 1410 GST_UWB_BLE_Master_Byte5 "21.05.02";
BA_ "NetworkRequestHoldingTime" SG_ 1410 GST_UWB_BLE_Master_Byte5 5000;
BA_ "NetworkRequest" SG_ 1410 GST_UWB_BLE_Master_Byte5 0;
BA_ "UserSigValidity" SG_ 1410 GST_UWB_BLE_Master_Byte5 0;
BA_ "UsrSigPurpose" SG_ 1410 GST_UWB_BLE_Master_Byte5 3;
BA_ "Description" SG_ 1410 GST_UWB_BLE_Master_Byte5 "TP Index : 95";
BA_ "Version" SG_ 1410 GST_UWB_BLE_Master_Byte6 "21.05.02";
BA_ "NetworkRequestHoldingTime" SG_ 1410 GST_UWB_BLE_Master_Byte6 5000;
BA_ "NetworkRequest" SG_ 1410 GST_UWB_BLE_Master_Byte6 0;
BA_ "UserSigValidity" SG_ 1410 GST_UWB_BLE_Master_Byte6 0;
BA_ "UsrSigPurpose" SG_ 1410 GST_UWB_BLE_Master_Byte6 3;
BA_ "Description" SG_ 1410 GST_UWB_BLE_Master_Byte6 "TP Index : 95";
BA_ "Version" SG_ 1410 GST_UWB_BLE_Master_Byte7 "21.05.02";
BA_ "NetworkRequestHoldingTime" SG_ 1410 GST_UWB_BLE_Master_Byte7 5000;
BA_ "NetworkRequest" SG_ 1410 GST_UWB_BLE_Master_Byte7 0;
BA_ "UserSigValidity" SG_ 1410 GST_UWB_BLE_Master_Byte7 0;
BA_ "UsrSigPurpose" SG_ 1410 GST_UWB_BLE_Master_Byte7 3;
BA_ "Description" SG_ 1410 GST_UWB_BLE_Master_Byte7 "TP Index : 95";
BA_ "Version" SG_ 1410 GST_UWB_BLE_Master_Byte1 "21.05.02";
BA_ "NetworkRequestHoldingTime" SG_ 1410 GST_UWB_BLE_Master_Byte1 5000;
BA_ "NetworkRequest" SG_ 1410 GST_UWB_BLE_Master_Byte1 0;
BA_ "UserSigValidity" SG_ 1410 GST_UWB_BLE_Master_Byte1 0;
BA_ "UsrSigPurpose" SG_ 1410 GST_UWB_BLE_Master_Byte1 3;
BA_ "Description" SG_ 1410 GST_UWB_BLE_Master_Byte1 "TP Index : 95";
BA_ "Version" SG_ 2281701568 L_UWB_FL_FD_Crc10Val "23.01.02";
BA_ "UserSigValidity" SG_ 2281701568 L_UWB_FL_FD_Crc10Val 3;
BA_ "GenSigStartValue" SG_ 2281701568 L_UWB_FL_FD_Crc10Val 65535;
BA_ "GenSigSendType" SG_ 2281701568 L_UWB_FL_FD_Crc10Val 4;
BA_ "Description" SG_ 2281701568 L_UWB_FL_FD_Crc10Val "The data area for CRC calculation is based on the data length (DLC) of the message DB.

The CRC shall be calculated over the entire data block (excluding the CRC bytes) including the user data, alive counter and Data ID



- CRC Polynomial (0x1021) , Ini";
BA_ "Version" SG_ 2281701568 UWB_FL_SW_MCU_Ver_Major "23.01.02";
BA_ "UserSigValidity" SG_ 2281701568 UWB_FL_SW_MCU_Ver_Major 0;
BA_ "GenSigSendType" SG_ 2281701568 UWB_FL_SW_MCU_Ver_Major 4;
BA_ "Version" SG_ 2281701568 UWB_FL_SW_MCU_Ver_Minor "23.01.02";
BA_ "UserSigValidity" SG_ 2281701568 UWB_FL_SW_MCU_Ver_Minor 0;
BA_ "GenSigSendType" SG_ 2281701568 UWB_FL_SW_MCU_Ver_Minor 4;
BA_ "Version" SG_ 2281701568 UWB_FL_SW_IC_Ver_Major "23.01.02";
BA_ "UserSigValidity" SG_ 2281701568 UWB_FL_SW_IC_Ver_Major 0;
BA_ "GenSigSendType" SG_ 2281701568 UWB_FL_SW_IC_Ver_Major 4;
BA_ "Version" SG_ 2281701568 UWB_FL_SW_IC_Ver_Minor "23.01.02";
BA_ "UserSigValidity" SG_ 2281701568 UWB_FL_SW_IC_Ver_Minor 0;
BA_ "GenSigSendType" SG_ 2281701568 UWB_FL_SW_IC_Ver_Minor 4;
BA_ "Version" SG_ 2281701568 UWB_FL_DTC "23.01.02";
BA_ "UserSigValidity" SG_ 2281701568 UWB_FL_DTC 0;
BA_ "GenSigSendType" SG_ 2281701568 UWB_FL_DTC 4;
BA_ "Version" SG_ 2281701568 L_UWB_FL_FD_AlvCnt10Val "23.01.02";
BA_ "UserSigValidity" SG_ 2281701568 L_UWB_FL_FD_AlvCnt10Val 3;
BA_ "GenSigSendType" SG_ 2281701568 L_UWB_FL_FD_AlvCnt10Val 4;
BA_ "Description" SG_ 2281701568 L_UWB_FL_FD_AlvCnt10Val "For the first transmission request for a data element the counter shall be initialized with 0 and shall be incremented by 1 for every subsequent send request. 

When the counter reaches the maximum value(0xFF), then it shall restart with 0 for the next s";
BA_ "Version" SG_ 2281701568 UWB_FL_Status1 "24.04.04";
BA_ "UserSigValidity" SG_ 2281701568 UWB_FL_Status1 0;
BA_ "GenSigSendType" SG_ 2281701568 UWB_FL_Status1 4;
BA_ "Description" SG_ 2281701568 UWB_FL_Status1 "UWB_FL Processing Status 1";
BA_ "Version" SG_ 2281701568 UWB_FL_Status2 "24.04.04";
BA_ "UserSigValidity" SG_ 2281701568 UWB_FL_Status2 0;
BA_ "GenSigSendType" SG_ 2281701568 UWB_FL_Status2 4;
BA_ "Description" SG_ 2281701568 UWB_FL_Status2 "UWB_FL Processing Status 2";
BA_ "Version" SG_ 2281701568 UWB_FL_Status3 "24.04.04";
BA_ "UserSigValidity" SG_ 2281701568 UWB_FL_Status3 0;
BA_ "GenSigSendType" SG_ 2281701568 UWB_FL_Status3 4;
BA_ "Description" SG_ 2281701568 UWB_FL_Status3 "UWB_FL Processing Status 3";
BA_ "Version" SG_ 2281701568 UWB_FL_Status4 "24.04.04";
BA_ "UserSigValidity" SG_ 2281701568 UWB_FL_Status4 0;
BA_ "GenSigSendType" SG_ 2281701568 UWB_FL_Status4 4;
BA_ "Description" SG_ 2281701568 UWB_FL_Status4 "UWB_FL Processing Status 4";
BA_ "Version" SG_ 2281701568 UWB_FL_Status5 "24.04.04";
BA_ "UserSigValidity" SG_ 2281701568 UWB_FL_Status5 0;
BA_ "GenSigSendType" SG_ 2281701568 UWB_FL_Status5 4;
BA_ "Description" SG_ 2281701568 UWB_FL_Status5 "UWB_FL Processing Status 5";
BA_ "Version" SG_ 2281701568 UWB_FL_Status6 "24.04.04";
BA_ "UserSigValidity" SG_ 2281701568 UWB_FL_Status6 0;
BA_ "GenSigSendType" SG_ 2281701568 UWB_FL_Status6 4;
BA_ "Description" SG_ 2281701568 UWB_FL_Status6 "UWB_FL Processing Status 6";
BA_ "Version" SG_ 2281701568 UWB_FL_Status7 "24.04.04";
BA_ "UserSigValidity" SG_ 2281701568 UWB_FL_Status7 0;
BA_ "GenSigSendType" SG_ 2281701568 UWB_FL_Status7 4;
BA_ "Description" SG_ 2281701568 UWB_FL_Status7 "UWB_FL Processing Status 7";
BA_ "Version" SG_ 2281701568 UWB_FL_Status8 "24.04.04";
BA_ "UserSigValidity" SG_ 2281701568 UWB_FL_Status8 0;
BA_ "GenSigSendType" SG_ 2281701568 UWB_FL_Status8 4;
BA_ "Description" SG_ 2281701568 UWB_FL_Status8 "UWB_FL Processing Status 8";
BA_ "Version" SG_ 2281701568 UWB_FL_Status9 "24.04.04";
BA_ "UserSigValidity" SG_ 2281701568 UWB_FL_Status9 0;
BA_ "GenSigSendType" SG_ 2281701568 UWB_FL_Status9 4;
BA_ "Description" SG_ 2281701568 UWB_FL_Status9 "UWB_FL Processing Status 9";
BA_ "Version" SG_ 2281701568 UWB_FL_Status10 "24.04.04";
BA_ "UserSigValidity" SG_ 2281701568 UWB_FL_Status10 0;
BA_ "GenSigSendType" SG_ 2281701568 UWB_FL_Status10 4;
BA_ "Description" SG_ 2281701568 UWB_FL_Status10 "UWB_FL Processing Status 10";
BA_ "Version" SG_ 2281701568 UWB_FL_Status11 "24.04.04";
BA_ "UserSigValidity" SG_ 2281701568 UWB_FL_Status11 0;
BA_ "GenSigSendType" SG_ 2281701568 UWB_FL_Status11 4;
BA_ "Description" SG_ 2281701568 UWB_FL_Status11 "UWB_FL Processing Status 11";
BA_ "Version" SG_ 2281701568 UWB_FL_Status12 "24.04.04";
BA_ "UserSigValidity" SG_ 2281701568 UWB_FL_Status12 0;
BA_ "GenSigSendType" SG_ 2281701568 UWB_FL_Status12 4;
BA_ "Description" SG_ 2281701568 UWB_FL_Status12 "UWB_FL Processing Status 12";
BA_ "Version" SG_ 2281701568 UWB_FL_Status13 "24.04.04";
BA_ "UserSigValidity" SG_ 2281701568 UWB_FL_Status13 0;
BA_ "GenSigSendType" SG_ 2281701568 UWB_FL_Status13 4;
BA_ "Description" SG_ 2281701568 UWB_FL_Status13 "UWB_FL Processing Status 13";
BA_ "Version" SG_ 2281701568 UWB_FL_Status14 "24.04.04";
BA_ "UserSigValidity" SG_ 2281701568 UWB_FL_Status14 0;
BA_ "GenSigSendType" SG_ 2281701568 UWB_FL_Status14 4;
BA_ "Description" SG_ 2281701568 UWB_FL_Status14 "UWB_FL Processing Status 14";
BA_ "Version" SG_ 2281701568 UWB_FL_Status15 "24.04.04";
BA_ "UserSigValidity" SG_ 2281701568 UWB_FL_Status15 0;
BA_ "GenSigSendType" SG_ 2281701568 UWB_FL_Status15 4;
BA_ "Description" SG_ 2281701568 UWB_FL_Status15 "UWB_FL Processing Status 15";
BA_ "Version" SG_ 2281701568 UWB_FL_Status16 "24.04.04";
BA_ "UserSigValidity" SG_ 2281701568 UWB_FL_Status16 0;
BA_ "GenSigSendType" SG_ 2281701568 UWB_FL_Status16 4;
BA_ "Description" SG_ 2281701568 UWB_FL_Status16 "UWB_FL Processing Status 16";
BA_ "Version" SG_ 2281701568 UWB_FL_HW_Ver_Major "23.01.02";
BA_ "UserSigValidity" SG_ 2281701568 UWB_FL_HW_Ver_Major 0;
BA_ "GenSigSendType" SG_ 2281701568 UWB_FL_HW_Ver_Major 4;
BA_ "Version" SG_ 2281701568 UWB_FL_HW_Ver_Minor "23.01.02";
BA_ "UserSigValidity" SG_ 2281701568 UWB_FL_HW_Ver_Minor 0;
BA_ "GenSigSendType" SG_ 2281701568 UWB_FL_HW_Ver_Minor 4;
BA_ "Version" SG_ 1418 UWB_BLE_Master_GST_Byte0 "21.05.02";
BA_ "UserSigValidity" SG_ 1418 UWB_BLE_Master_GST_Byte0 0;
BA_ "UsrSigPurpose" SG_ 1418 UWB_BLE_Master_GST_Byte0 4;
BA_ "Description" SG_ 1418 UWB_BLE_Master_GST_Byte0 "TP Index : 95";
BA_ "Version" SG_ 1418 UWB_BLE_Master_GST_Byte2 "21.05.02";
BA_ "UserSigValidity" SG_ 1418 UWB_BLE_Master_GST_Byte2 0;
BA_ "UsrSigPurpose" SG_ 1418 UWB_BLE_Master_GST_Byte2 4;
BA_ "Description" SG_ 1418 UWB_BLE_Master_GST_Byte2 "TP Index : 95";
BA_ "Version" SG_ 1418 UWB_BLE_Master_GST_Byte3 "21.05.02";
BA_ "UserSigValidity" SG_ 1418 UWB_BLE_Master_GST_Byte3 0;
BA_ "UsrSigPurpose" SG_ 1418 UWB_BLE_Master_GST_Byte3 4;
BA_ "Description" SG_ 1418 UWB_BLE_Master_GST_Byte3 "TP Index : 95";
BA_ "Version" SG_ 1418 UWB_BLE_Master_GST_Byte4 "21.05.02";
BA_ "UserSigValidity" SG_ 1418 UWB_BLE_Master_GST_Byte4 0;
BA_ "UsrSigPurpose" SG_ 1418 UWB_BLE_Master_GST_Byte4 4;
BA_ "Description" SG_ 1418 UWB_BLE_Master_GST_Byte4 "TP Index : 95";
BA_ "Version" SG_ 1418 UWB_BLE_Master_GST_Byte5 "21.05.02";
BA_ "UserSigValidity" SG_ 1418 UWB_BLE_Master_GST_Byte5 0;
BA_ "UsrSigPurpose" SG_ 1418 UWB_BLE_Master_GST_Byte5 4;
BA_ "Description" SG_ 1418 UWB_BLE_Master_GST_Byte5 "TP Index : 95";
BA_ "Version" SG_ 1418 UWB_BLE_Master_GST_Byte6 "21.05.02";
BA_ "UserSigValidity" SG_ 1418 UWB_BLE_Master_GST_Byte6 0;
BA_ "UsrSigPurpose" SG_ 1418 UWB_BLE_Master_GST_Byte6 4;
BA_ "Description" SG_ 1418 UWB_BLE_Master_GST_Byte6 "TP Index : 95";
BA_ "Version" SG_ 1418 UWB_BLE_Master_GST_Byte7 "21.05.02";
BA_ "UserSigValidity" SG_ 1418 UWB_BLE_Master_GST_Byte7 0;
BA_ "UsrSigPurpose" SG_ 1418 UWB_BLE_Master_GST_Byte7 4;
BA_ "Description" SG_ 1418 UWB_BLE_Master_GST_Byte7 "TP Index : 95";
BA_ "Version" SG_ 1418 UWB_BLE_Master_GST_Byte1 "21.05.02";
BA_ "UserSigValidity" SG_ 1418 UWB_BLE_Master_GST_Byte1 0;
BA_ "UsrSigPurpose" SG_ 1418 UWB_BLE_Master_GST_Byte1 4;
BA_ "Description" SG_ 1418 UWB_BLE_Master_GST_Byte1 "TP Index : 95";
BA_ "Version" SG_ 992 PDC_FD_Crc1Val "22.10.20";
BA_ "UserSigValidity" SG_ 992 PDC_FD_Crc1Val 3;
BA_ "GenSigStartValue" SG_ 992 PDC_FD_Crc1Val 65535;
BA_ "GenSigSendType" SG_ 992 PDC_FD_Crc1Val 4;
BA_ "Description" SG_ 992 PDC_FD_Crc1Val "The data area for CRC calculation is based on the data length (DLC) of the message DB.

The CRC shall be calculated over the entire data block (excluding the CRC bytes) including the user data, alive counter and Data ID



- CRC Polynomial (0x1021) , Ini";
BA_ "Version" SG_ 992 C_3rdRCSeatBeltSW_Copy_0 "18.03.04";
BA_ "NetworkRequestHoldingTime" SG_ 992 C_3rdRCSeatBeltSW_Copy_0 5000;
BA_ "NetworkRequest" SG_ 992 C_3rdRCSeatBeltSW_Copy_0 0;
BA_ "UserSigValidity" SG_ 992 C_3rdRCSeatBeltSW_Copy_0 0;
BA_ "GenSigSendType" SG_ 992 C_3rdRCSeatBeltSW_Copy_0 4;
BA_ "Description" SG_ 992 C_3rdRCSeatBeltSW_Copy_0 "3rd Rear Center Seat Belt Switch Status";
BA_ "Version" SG_ 992 C_3rdRRSeatBeltSW_Copy_0 "18.03.04";
BA_ "NetworkRequestHoldingTime" SG_ 992 C_3rdRRSeatBeltSW_Copy_0 5000;
BA_ "NetworkRequest" SG_ 992 C_3rdRRSeatBeltSW_Copy_0 0;
BA_ "UserSigValidity" SG_ 992 C_3rdRRSeatBeltSW_Copy_0 0;
BA_ "GenSigSendType" SG_ 992 C_3rdRRSeatBeltSW_Copy_0 4;
BA_ "Description" SG_ 992 C_3rdRRSeatBeltSW_Copy_0 "3rd Rear Right Seat Belt Switch Status";
BA_ "Version" SG_ 992 C_1stCTRSeatBeltSW_Copy_0 "19.04.06";
BA_ "NetworkRequestHoldingTime" SG_ 992 C_1stCTRSeatBeltSW_Copy_0 5000;
BA_ "NetworkRequest" SG_ 992 C_1stCTRSeatBeltSW_Copy_0 0;
BA_ "UserSigValidity" SG_ 992 C_1stCTRSeatBeltSW_Copy_0 0;
BA_ "GenSigSendType" SG_ 992 C_1stCTRSeatBeltSW_Copy_0 4;
BA_ "Description" SG_ 992 C_1stCTRSeatBeltSW_Copy_0 "1st Center Seat Belt Switch Status";
BA_ "Version" SG_ 992 Warn_DrvStOccSta_Copy_0 "22.05.04";
BA_ "NetworkRequestHoldingTime" SG_ 992 Warn_DrvStOccSta_Copy_0 5000;
BA_ "NetworkRequest" SG_ 992 Warn_DrvStOccSta_Copy_0 0;
BA_ "UserSigValidity" SG_ 992 Warn_DrvStOccSta_Copy_0 0;
BA_ "GenSigSendType" SG_ 992 Warn_DrvStOccSta_Copy_0 4;
BA_ "Description" SG_ 992 Warn_DrvStOccSta_Copy_0 "Driver Presence Detection MAT Switch Status";
BA_ "Version" SG_ 992 DPDMat_HDPSpprtSWVer_Copy_0 "21.12.04";
BA_ "UserSigValidity" SG_ 992 DPDMat_HDPSpprtSWVer_Copy_0 3;
BA_ "GenSigSendType" SG_ 992 DPDMat_HDPSpprtSWVer_Copy_0 4;
BA_ "Description" SG_ 992 DPDMat_HDPSpprtSWVer_Copy_0 "This signal indicates HDP-DPD Mat signal processing Requirement Spec Version";
BA_ "Version" SG_ 992 Warn_PassStOccSta_Copy_0 "17.12.00";
BA_ "NetworkRequestHoldingTime" SG_ 992 Warn_PassStOccSta_Copy_0 5000;
BA_ "NetworkRequest" SG_ 992 Warn_PassStOccSta_Copy_0 0;
BA_ "UserSigValidity" SG_ 992 Warn_PassStOccSta_Copy_0 0;
BA_ "GenSigSendType" SG_ 992 Warn_PassStOccSta_Copy_0 4;
BA_ "Description" SG_ 992 Warn_PassStOccSta_Copy_0 "Passenger Seated State







-Default value: 0x0 (╣╠┼╛╜┬)



-Initial value: 0x0 (╣╠┼╛╜┬)



-Timeout value: 0x0 (╣╠┼╛╜┬)";
BA_ "Version" SG_ 992 Warn_RrLftSBRMATSwSta_Copy_0 "21.11.00";
BA_ "NetworkRequestHoldingTime" SG_ 992 Warn_RrLftSBRMATSwSta_Copy_0 5000;
BA_ "NetworkRequest" SG_ 992 Warn_RrLftSBRMATSwSta_Copy_0 0;
BA_ "UserSigValidity" SG_ 992 Warn_RrLftSBRMATSwSta_Copy_0 0;
BA_ "GenSigSendType" SG_ 992 Warn_RrLftSBRMATSwSta_Copy_0 4;
BA_ "Description" SG_ 992 Warn_RrLftSBRMATSwSta_Copy_0 "Rear Left Seated State";
BA_ "Version" SG_ 992 Warn_RrRhtSBRMATSwSta_Copy_0 "21.11.00";
BA_ "NetworkRequestHoldingTime" SG_ 992 Warn_RrRhtSBRMATSwSta_Copy_0 5000;
BA_ "NetworkRequest" SG_ 992 Warn_RrRhtSBRMATSwSta_Copy_0 0;
BA_ "UserSigValidity" SG_ 992 Warn_RrRhtSBRMATSwSta_Copy_0 0;
BA_ "GenSigSendType" SG_ 992 Warn_RrRhtSBRMATSwSta_Copy_0 4;
BA_ "Description" SG_ 992 Warn_RrRhtSBRMATSwSta_Copy_0 "Rear Right Seated State";
BA_ "Version" SG_ 992 C_3rdRLSBRMatSw_Copy_0 "18.03.04";
BA_ "NetworkRequestHoldingTime" SG_ 992 C_3rdRLSBRMatSw_Copy_0 5000;
BA_ "NetworkRequest" SG_ 992 C_3rdRLSBRMatSw_Copy_0 0;
BA_ "UserSigValidity" SG_ 992 C_3rdRLSBRMatSw_Copy_0 0;
BA_ "GenSigSendType" SG_ 992 C_3rdRLSBRMatSw_Copy_0 4;
BA_ "Description" SG_ 992 C_3rdRLSBRMatSw_Copy_0 "3rd Rear Left Seated State



-Default value: 0x0 (╣╠┼╛╜┬)

-Initial value: 0x0 (╣╠┼╛╜┬)

-Timeout value: 0x0 (╣╠┼╛╜┬)";
BA_ "Version" SG_ 992 C_3rdRRSBRMatSw_Copy_0 "18.03.04";
BA_ "NetworkRequestHoldingTime" SG_ 992 C_3rdRRSBRMatSw_Copy_0 5000;
BA_ "NetworkRequest" SG_ 992 C_3rdRRSBRMatSw_Copy_0 0;
BA_ "UserSigValidity" SG_ 992 C_3rdRRSBRMatSw_Copy_0 0;
BA_ "GenSigSendType" SG_ 992 C_3rdRRSBRMatSw_Copy_0 4;
BA_ "Description" SG_ 992 C_3rdRRSBRMatSw_Copy_0 "3rd Rear Right Seated State



-Default value: 0x0 (╣╠┼╛╜┬)

-Initial value: 0x0 (╣╠┼╛╜┬)

-Timeout value: 0x0 (╣╠┼╛╜┬)";
BA_ "Version" SG_ 992 C_1stCTRSBRMatSw_Copy_0 "19.04.06";
BA_ "NetworkRequestHoldingTime" SG_ 992 C_1stCTRSBRMatSw_Copy_0 5000;
BA_ "NetworkRequest" SG_ 992 C_1stCTRSBRMatSw_Copy_0 0;
BA_ "UserSigValidity" SG_ 992 C_1stCTRSBRMatSw_Copy_0 0;
BA_ "GenSigSendType" SG_ 992 C_1stCTRSBRMatSw_Copy_0 4;
BA_ "Description" SG_ 992 C_1stCTRSBRMatSw_Copy_0 "1st Center Seated State



-Default value: 0x0 (╣╠┼╛╜┬)

-Initial value: 0x0 (╣╠┼╛╜┬)

-Timeout value: 0x0 (╣╠┼╛╜┬)";
BA_ "Version" SG_ 992 StrWhlWrmrSwState_Copy_0 "20.08.07";
BA_ "UserSigValidity" SG_ 992 StrWhlWrmrSwState_Copy_0 4;
BA_ "GenSigSendType" SG_ 992 StrWhlWrmrSwState_Copy_0 4;
BA_ "Description" SG_ 992 StrWhlWrmrSwState_Copy_0 "PDC Steering Wheel Warmer Self Return Type Manual Switch State";
BA_ "Version" SG_ 992 StrWhlWrmrFlModDetail_Copy_0 "20.08.07";
BA_ "UserSigValidity" SG_ 992 StrWhlWrmrFlModDetail_Copy_0 4;
BA_ "GenSigSendType" SG_ 992 StrWhlWrmrFlModDetail_Copy_0 4;
BA_ "Description" SG_ 992 StrWhlWrmrFlModDetail_Copy_0 "Steering Wheel Warmer Fail Mode Detail Information";
BA_ "Version" SG_ 992 FrHtdGlsSwState_Copy_0 "20.08.07";
BA_ "UserSigValidity" SG_ 992 FrHtdGlsSwState_Copy_0 4;
BA_ "GenSigSendType" SG_ 992 FrHtdGlsSwState_Copy_0 4;
BA_ "Description" SG_ 992 FrHtdGlsSwState_Copy_0 "Front Heated Glass Switch State";
BA_ "Version" SG_ 992 RrGlsHtSwState_Copy_0 "21.01.06";
BA_ "UserSigValidity" SG_ 992 RrGlsHtSwState_Copy_0 4;
BA_ "GenSigSendType" SG_ 992 RrGlsHtSwState_Copy_0 4;
BA_ "Description" SG_ 992 RrGlsHtSwState_Copy_0 "Rear Glass Heated Switch State";
BA_ "Version" SG_ 992 RLChldLkLatchSwState_Copy_0 "20.08.07";
BA_ "NetworkRequestHoldingTime" SG_ 992 RLChldLkLatchSwState_Copy_0 5000;
BA_ "NetworkRequest" SG_ 992 RLChldLkLatchSwState_Copy_0 0;
BA_ "UserSigValidity" SG_ 992 RLChldLkLatchSwState_Copy_0 0;
BA_ "GenSigSendType" SG_ 992 RLChldLkLatchSwState_Copy_0 4;
BA_ "Description" SG_ 992 RLChldLkLatchSwState_Copy_0 "Rear Left Electric Child Lock Latch Lock Unlock State";
BA_ "Version" SG_ 992 RRChldLkLatchSwState_Copy_0 "20.08.07";
BA_ "NetworkRequestHoldingTime" SG_ 992 RRChldLkLatchSwState_Copy_0 5000;
BA_ "NetworkRequest" SG_ 992 RRChldLkLatchSwState_Copy_0 0;
BA_ "UserSigValidity" SG_ 992 RRChldLkLatchSwState_Copy_0 0;
BA_ "GenSigSendType" SG_ 992 RRChldLkLatchSwState_Copy_0 4;
BA_ "Description" SG_ 992 RRChldLkLatchSwState_Copy_0 "Rear Right Electric Child Lock Latch Lock Unlock State";
BA_ "Version" SG_ 992 ChildLock_ActnFlSta_Copy_0 "17.12.00";
BA_ "NetworkRequestHoldingTime" SG_ 992 ChildLock_ActnFlSta_Copy_0 5000;
BA_ "NetworkRequest" SG_ 992 ChildLock_ActnFlSta_Copy_0 0;
BA_ "UserSigValidity" SG_ 992 ChildLock_ActnFlSta_Copy_0 0;
BA_ "GenSigSendType" SG_ 992 ChildLock_ActnFlSta_Copy_0 4;
BA_ "Description" SG_ 992 ChildLock_ActnFlSta_Copy_0 "Child Lock actuation failed";
BA_ "Version" SG_ 992 DoorLock_LkOutSta_Copy_0 "17.12.00";
BA_ "NetworkRequestHoldingTime" SG_ 992 DoorLock_LkOutSta_Copy_0 5000;
BA_ "NetworkRequest" SG_ 992 DoorLock_LkOutSta_Copy_0 0;
BA_ "UserSigValidity" SG_ 992 DoorLock_LkOutSta_Copy_0 0;
BA_ "GenSigSendType" SG_ 992 DoorLock_LkOutSta_Copy_0 4;
BA_ "Description" SG_ 992 DoorLock_LkOutSta_Copy_0 "- Door Lock or Unlock Output State 



0x0 : Off (Door lock/unlock output Off state)



0x1 : On (Door lock/unlock output On state)";
BA_ "Version" SG_ 992 VSAutoDrLkRetryFailSta_Copy_0 "21.11.00";
BA_ "NetworkRequestHoldingTime" SG_ 992 VSAutoDrLkRetryFailSta_Copy_0 5000;
BA_ "NetworkRequest" SG_ 992 VSAutoDrLkRetryFailSta_Copy_0 0;
BA_ "UserSigValidity" SG_ 992 VSAutoDrLkRetryFailSta_Copy_0 6;
BA_ "TimeoutValue" SG_ 992 VSAutoDrLkRetryFailSta_Copy_0 "0x0";
BA_ "GenSigSendType" SG_ 992 VSAutoDrLkRetryFailSta_Copy_0 4;
BA_ "Description" SG_ 992 VSAutoDrLkRetryFailSta_Copy_0 "Door lock fail status after vehicle speed auto door lock retry 3 times";
BA_ "Version" SG_ 992 Trunk_TrnkTlgtOutReleaseSwSta_Co "23.04.02";
BA_ "NetworkRequestHoldingTime" SG_ 992 Trunk_TrnkTlgtOutReleaseSwSta_Co 5000;
BA_ "NetworkRequest" SG_ 992 Trunk_TrnkTlgtOutReleaseSwSta_Co 0;
BA_ "UserSigValidity" SG_ 992 Trunk_TrnkTlgtOutReleaseSwSta_Co 0;
BA_ "GenSigSendType" SG_ 992 Trunk_TrnkTlgtOutReleaseSwSta_Co 4;
BA_ "Description" SG_ 992 Trunk_TrnkTlgtOutReleaseSwSta_Co "-(Old)C_TRUNK_LID

-Trunk/Tailgate Outter Release SW";
BA_ "SystemSignalLongSymbol" SG_ 992 Trunk_TrnkTlgtOutReleaseSwSta_Co "Trunk_TrnkTlgtOutReleaseSwSta_Copy_0";
BA_ "Version" SG_ 992 Trunk_TrnkInReleaseSwSta_Copy_0 "23.04.02";
BA_ "NetworkRequestHoldingTime" SG_ 992 Trunk_TrnkInReleaseSwSta_Copy_0 5000;
BA_ "NetworkRequest" SG_ 992 Trunk_TrnkInReleaseSwSta_Copy_0 0;
BA_ "UserSigValidity" SG_ 992 Trunk_TrnkInReleaseSwSta_Copy_0 0;
BA_ "GenSigSendType" SG_ 992 Trunk_TrnkInReleaseSwSta_Copy_0 4;
BA_ "Description" SG_ 992 Trunk_TrnkInReleaseSwSta_Copy_0 "-Trunk Inner Release SW";
BA_ "Version" SG_ 992 Trunk_GlvBxTrnkLkSwSta_Copy_0 "17.12.00";
BA_ "NetworkRequestHoldingTime" SG_ 992 Trunk_GlvBxTrnkLkSwSta_Copy_0 5000;
BA_ "NetworkRequest" SG_ 992 Trunk_GlvBxTrnkLkSwSta_Copy_0 0;
BA_ "UserSigValidity" SG_ 992 Trunk_GlvBxTrnkLkSwSta_Copy_0 0;
BA_ "GenSigSendType" SG_ 992 Trunk_GlvBxTrnkLkSwSta_Copy_0 4;
BA_ "Description" SG_ 992 Trunk_GlvBxTrnkLkSwSta_Copy_0 "- Glove Box Trunk Lock SW";
BA_ "Version" SG_ 992 Trunk_TrnkTlgtSwSta_Copy_0 "17.12.00";
BA_ "NetworkRequestHoldingTime" SG_ 992 Trunk_TrnkTlgtSwSta_Copy_0 5000;
BA_ "NetworkRequest" SG_ 992 Trunk_TrnkTlgtSwSta_Copy_0 0;
BA_ "UserSigValidity" SG_ 992 Trunk_TrnkTlgtSwSta_Copy_0 0;
BA_ "GenSigSendType" SG_ 992 Trunk_TrnkTlgtSwSta_Copy_0 4;
BA_ "Description" SG_ 992 Trunk_TrnkTlgtSwSta_Copy_0 "Full Lock SW Status Signal



(TailGate/TrunkLid Tpye all)



1. Luggage or Trunkroom Lamp On/Off



2. TailGate/TrunkLid Open Ind in cluster



3. Normal Open SW



  - SW Off: Full Lock(Full Close state)



  - SW On: ^Full Lock";
BA_ "Version" SG_ 992 Trunk_TlgtFullOpnSwSta_Copy_0 "17.12.00";
BA_ "NetworkRequestHoldingTime" SG_ 992 Trunk_TlgtFullOpnSwSta_Copy_0 5000;
BA_ "NetworkRequest" SG_ 992 Trunk_TlgtFullOpnSwSta_Copy_0 0;
BA_ "UserSigValidity" SG_ 992 Trunk_TlgtFullOpnSwSta_Copy_0 0;
BA_ "GenSigSendType" SG_ 992 Trunk_TlgtFullOpnSwSta_Copy_0 4;
BA_ "Description" SG_ 992 Trunk_TlgtFullOpnSwSta_Copy_0 "Full Open SW Status Signal



(Power TailGate/TrunkLid Tpye or tailgate latch 2sw type)



* Normal Open SW



  - SW Off: ^Full Open



  - SW On: Full Open(Full Open state)";
BA_ "Version" SG_ 992 Trunk_TrnkTlgtReleaseRlySta_Copy "17.12.00";
BA_ "NetworkRequestHoldingTime" SG_ 992 Trunk_TrnkTlgtReleaseRlySta_Copy 5000;
BA_ "NetworkRequest" SG_ 992 Trunk_TrnkTlgtReleaseRlySta_Copy 0;
BA_ "UserSigValidity" SG_ 992 Trunk_TrnkTlgtReleaseRlySta_Copy 0;
BA_ "GenSigSendType" SG_ 992 Trunk_TrnkTlgtReleaseRlySta_Copy 4;
BA_ "SystemSignalLongSymbol" SG_ 992 Trunk_TrnkTlgtReleaseRlySta_Copy "Trunk_TrnkTlgtReleaseRlySta_Copy_0";
BA_ "Version" SG_ 992 FrtWiper_ParkingSwState "23.04.06";
BA_ "UserSigValidity" SG_ 992 FrtWiper_ParkingSwState 0;
BA_ "TimeoutValue" SG_ 992 FrtWiper_ParkingSwState "0x0";
BA_ "GenSigSendType" SG_ 992 FrtWiper_ParkingSwState 4;
BA_ "Description" SG_ 992 FrtWiper_ParkingSwState "Front wiper parking switch state";
BA_ "Version" SG_ 992 PDC_TlgtUnLkSta "24.01.00";
BA_ "NetworkRequestHoldingTime" SG_ 992 PDC_TlgtUnLkSta 5000;
BA_ "NetworkRequest" SG_ 992 PDC_TlgtUnLkSta 0;
BA_ "UserSigValidity" SG_ 992 PDC_TlgtUnLkSta 0;
BA_ "GenSigSendType" SG_ 992 PDC_TlgtUnLkSta 4;
BA_ "Description" SG_ 992 PDC_TlgtUnLkSta "Tailgate unlocked status of MPV vehicle with twin swing tailgate";
BA_ "Version" SG_ 992 PDC_PSDPwrModeOffSwSta "24.01.00";
BA_ "NetworkRequestHoldingTime" SG_ 992 PDC_PSDPwrModeOffSwSta 5000;
BA_ "NetworkRequest" SG_ 992 PDC_PSDPwrModeOffSwSta 0;
BA_ "UserSigValidity" SG_ 992 PDC_PSDPwrModeOffSwSta 0;
BA_ "GenSigSendType" SG_ 992 PDC_PSDPwrModeOffSwSta 4;
BA_ "Description" SG_ 992 PDC_PSDPwrModeOffSwSta "PSD power mode off switch state(Self-return type)

-'On' value is output only during the time the switch is pressed";
BA_ "Version" SG_ 992 PDC_FuelDrOpenSta "24.04.03";
BA_ "NetworkRequestHoldingTime" SG_ 992 PDC_FuelDrOpenSta 5000;
BA_ "NetworkRequest" SG_ 992 PDC_FuelDrOpenSta 0;
BA_ "UserSigValidity" SG_ 992 PDC_FuelDrOpenSta 0;
BA_ "GenSigSendType" SG_ 992 PDC_FuelDrOpenSta 4;
BA_ "Description" SG_ 992 PDC_FuelDrOpenSta "Fuel door open status(Open/Close)

Fuel door switch located in fuel door, thus switch states means physical status of fuel door(Open/Close)";
BA_ "Version" SG_ 992 PDC_FD_AlvCnt1Val "22.10.20";
BA_ "UserSigValidity" SG_ 992 PDC_FD_AlvCnt1Val 3;
BA_ "GenSigSendType" SG_ 992 PDC_FD_AlvCnt1Val 4;
BA_ "Description" SG_ 992 PDC_FD_AlvCnt1Val "For the first transmission request for a data element the counter shall be initialized with 0 and shall be incremented by 1 for every subsequent send request. 

When the counter reaches the maximum value(0xFF), then it shall restart with 0 for the next s";
BA_ "Version" SG_ 992 OBCWakeupDrLock_Copy_0 "19.04.06";
BA_ "UserSigValidity" SG_ 992 OBCWakeupDrLock_Copy_0 0;
BA_ "GenSigSendType" SG_ 992 OBCWakeupDrLock_Copy_0 4;
BA_ "Description" SG_ 992 OBCWakeupDrLock_Copy_0 "This signal is for OBC wake-up, When ICU Lock event";
BA_ "Version" SG_ 992 OBCWakeupDrUnlock_Copy_0 "19.04.06";
BA_ "UserSigValidity" SG_ 992 OBCWakeupDrUnlock_Copy_0 0;
BA_ "GenSigSendType" SG_ 992 OBCWakeupDrUnlock_Copy_0 4;
BA_ "Description" SG_ 992 OBCWakeupDrUnlock_Copy_0 "This signal is for OBC wake-up, When ICU Unlock event";
BA_ "Version" SG_ 992 Trunk_BgtOpnHzrdReq_Copy_0 "22.07.06";
BA_ "NetworkRequestHoldingTime" SG_ 992 Trunk_BgtOpnHzrdReq_Copy_0 5000;
BA_ "NetworkRequest" SG_ 992 Trunk_BgtOpnHzrdReq_Copy_0 0;
BA_ "UserSigValidity" SG_ 992 Trunk_BgtOpnHzrdReq_Copy_0 0;
BA_ "GenSigSendType" SG_ 992 Trunk_BgtOpnHzrdReq_Copy_0 4;
BA_ "Description" SG_ 992 Trunk_BgtOpnHzrdReq_Copy_0 "Hazzard Request by Bedgate Open";
BA_ "Version" SG_ 992 Trunk_BgtOpnBzrReq_Copy_0 "22.07.06";
BA_ "NetworkRequestHoldingTime" SG_ 992 Trunk_BgtOpnBzrReq_Copy_0 5000;
BA_ "NetworkRequest" SG_ 992 Trunk_BgtOpnBzrReq_Copy_0 0;
BA_ "UserSigValidity" SG_ 992 Trunk_BgtOpnBzrReq_Copy_0 0;
BA_ "GenSigSendType" SG_ 992 Trunk_BgtOpnBzrReq_Copy_0 4;
BA_ "Description" SG_ 992 Trunk_BgtOpnBzrReq_Copy_0 "Buzzer Request by Bedgate Open";
BA_ "Version" SG_ 992 IGN3State "23.09.00";
BA_ "UserSigValidity" SG_ 992 IGN3State 7;
BA_ "TimeoutValue" SG_ 992 IGN3State "0x0";
BA_ "GenSigSendType" SG_ 992 IGN3State 4;
BA_ "Description" SG_ 992 IGN3State "Output status of ignition 3";
BA_ "Version" SG_ 992 IGN3State_By_BMS "23.02.02";
BA_ "UserSigValidity" SG_ 992 IGN3State_By_BMS 7;
BA_ "TimeoutValue" SG_ 992 IGN3State_By_BMS "0x0";
BA_ "GenSigSendType" SG_ 992 IGN3State_By_BMS 4;
BA_ "Description" SG_ 992 IGN3State_By_BMS "Output status of ignition 3 by BMS request";
BA_ "Version" SG_ 992 IGN3State_By_VCMS_HMU "23.02.02";
BA_ "UserSigValidity" SG_ 992 IGN3State_By_VCMS_HMU 7;
BA_ "TimeoutValue" SG_ 992 IGN3State_By_VCMS_HMU "0x0";
BA_ "GenSigSendType" SG_ 992 IGN3State_By_VCMS_HMU 4;
BA_ "Description" SG_ 992 IGN3State_By_VCMS_HMU "Output status of ignition 3 by VCMS(PHEV/EV) or HMU(FCEV) request";
BA_ "Version" SG_ 992 IGN3State_By_AfterBlow "23.02.02";
BA_ "UserSigValidity" SG_ 992 IGN3State_By_AfterBlow 7;
BA_ "TimeoutValue" SG_ 992 IGN3State_By_AfterBlow "0x0";
BA_ "GenSigSendType" SG_ 992 IGN3State_By_AfterBlow 4;
BA_ "Description" SG_ 992 IGN3State_By_AfterBlow "Output status of ignition 3 by DATC(FATC/MTC) request for after blow";
BA_ "Version" SG_ 992 IGN3State_By_Bat_Copy_0 "23.02.01";
BA_ "UserSigValidity" SG_ 992 IGN3State_By_Bat_Copy_0 7;
BA_ "TimeoutValue" SG_ 992 IGN3State_By_Bat_Copy_0 "0x0";
BA_ "GenSigSendType" SG_ 992 IGN3State_By_Bat_Copy_0 4;
BA_ "Description" SG_ 992 IGN3State_By_Bat_Copy_0 "Output status of ignition 3 by IBS or BMS request for HEV 12V auxiliary battery charging";
BA_ "Version" SG_ 992 IGN3State_By_VCU_HCU_FCU "23.02.02";
BA_ "UserSigValidity" SG_ 992 IGN3State_By_VCU_HCU_FCU 7;
BA_ "TimeoutValue" SG_ 992 IGN3State_By_VCU_HCU_FCU "0x0";
BA_ "GenSigSendType" SG_ 992 IGN3State_By_VCU_HCU_FCU 4;
BA_ "Description" SG_ 992 IGN3State_By_VCU_HCU_FCU "Output status of ignition 3 by VCU(EV) or HCU(HEV/PHEV) or FCU(FCEV) request";
BA_ "Version" SG_ 992 IGN3State_By_HU "23.02.02";
BA_ "UserSigValidity" SG_ 992 IGN3State_By_HU 7;
BA_ "TimeoutValue" SG_ 992 IGN3State_By_HU "0x0";
BA_ "GenSigSendType" SG_ 992 IGN3State_By_HU 4;
BA_ "Description" SG_ 992 IGN3State_By_HU "Output status of ignition 3 by HU(AVNT) or CCU request for CCS";
BA_ "Version" SG_ 992 IGN3CutOffState "24.07.06";
BA_ "UserSigValidity" SG_ 992 IGN3CutOffState 7;
BA_ "TimeoutValue" SG_ 992 IGN3CutOffState "0x0";
BA_ "GenSigSendType" SG_ 992 IGN3CutOffState 4;
BA_ "Description" SG_ 992 IGN3CutOffState "Output status of ignition 3 Cut Off



0x0:CutOffNotApplied (Cut Off Funtion Not Applied in PDC)

0x1:NoRequest (No IGN3 Request)

0x2:Normal (IGN3 Request and Power State is OK)

0x3:PreWarn (IGN3 Request and Power State is NOK, IGN3 Cut Off PreWarning)";
BA_ "Version" SG_ 992 SeatBeltSwSta_Drv_Copy_0 "23.07.03";
BA_ "NetworkRequestHoldingTime" SG_ 992 SeatBeltSwSta_Drv_Copy_0 5000;
BA_ "NetworkRequest" SG_ 992 SeatBeltSwSta_Drv_Copy_0 0;
BA_ "UserSigValidity" SG_ 992 SeatBeltSwSta_Drv_Copy_0 0;
BA_ "GenSigSendType" SG_ 992 SeatBeltSwSta_Drv_Copy_0 4;
BA_ "Description" SG_ 992 SeatBeltSwSta_Drv_Copy_0 "Driver Seat Belt Switch Status.

This signal is set as 'Not Supported' if the seat belt is not installed for EDR law(UN ECE R160.01) and EURO NCAP";
BA_ "Version" SG_ 992 SeatBeltSwSta_1stCtr_Copy_0 "23.07.03";
BA_ "NetworkRequestHoldingTime" SG_ 992 SeatBeltSwSta_1stCtr_Copy_0 5000;
BA_ "NetworkRequest" SG_ 992 SeatBeltSwSta_1stCtr_Copy_0 0;
BA_ "UserSigValidity" SG_ 992 SeatBeltSwSta_1stCtr_Copy_0 0;
BA_ "GenSigSendType" SG_ 992 SeatBeltSwSta_1stCtr_Copy_0 4;
BA_ "Description" SG_ 992 SeatBeltSwSta_1stCtr_Copy_0 "1st Center Seat Belt Switch Status

This signal is set as 'Not Supported' if the seat belt is not installed for EDR law(UN ECE R160.01) and EURO NCAP";
BA_ "Version" SG_ 992 SeatBeltSwSta_Asst_Copy_0 "23.07.03";
BA_ "NetworkRequestHoldingTime" SG_ 992 SeatBeltSwSta_Asst_Copy_0 5000;
BA_ "NetworkRequest" SG_ 992 SeatBeltSwSta_Asst_Copy_0 0;
BA_ "UserSigValidity" SG_ 992 SeatBeltSwSta_Asst_Copy_0 0;
BA_ "GenSigSendType" SG_ 992 SeatBeltSwSta_Asst_Copy_0 4;
BA_ "Description" SG_ 992 SeatBeltSwSta_Asst_Copy_0 "Assistance Seat Belt Switch Status

This signal is set as 'Not Supported' if the seat belt is not installed for EDR law(UN ECE R160.01) and EURO NCAP";
BA_ "Version" SG_ 992 SeatBeltSwSta_2ndLft_Copy_0 "23.07.03";
BA_ "NetworkRequestHoldingTime" SG_ 992 SeatBeltSwSta_2ndLft_Copy_0 5000;
BA_ "NetworkRequest" SG_ 992 SeatBeltSwSta_2ndLft_Copy_0 0;
BA_ "UserSigValidity" SG_ 992 SeatBeltSwSta_2ndLft_Copy_0 0;
BA_ "GenSigSendType" SG_ 992 SeatBeltSwSta_2ndLft_Copy_0 4;
BA_ "Description" SG_ 992 SeatBeltSwSta_2ndLft_Copy_0 "2nd Left Seat Belt Switch Status

This signal is set as 'Not Supported' if the seat belt is not installed for EDR law(UN ECE R160.01) and EURO NCAP";
BA_ "Version" SG_ 992 SeatBeltSwSta_2ndCtr_Copy_0 "23.07.03";
BA_ "NetworkRequestHoldingTime" SG_ 992 SeatBeltSwSta_2ndCtr_Copy_0 5000;
BA_ "NetworkRequest" SG_ 992 SeatBeltSwSta_2ndCtr_Copy_0 0;
BA_ "UserSigValidity" SG_ 992 SeatBeltSwSta_2ndCtr_Copy_0 0;
BA_ "GenSigSendType" SG_ 992 SeatBeltSwSta_2ndCtr_Copy_0 4;
BA_ "Description" SG_ 992 SeatBeltSwSta_2ndCtr_Copy_0 "2nd Center Seat Belt Switch Status

This signal is set as 'Not Supported' if the seat belt is not installed for EDR law(UN ECE R160.01) and EURO NCAP";
BA_ "Version" SG_ 992 SeatBeltSwSta_2ndRt_Copy_0 "23.07.03";
BA_ "NetworkRequestHoldingTime" SG_ 992 SeatBeltSwSta_2ndRt_Copy_0 5000;
BA_ "NetworkRequest" SG_ 992 SeatBeltSwSta_2ndRt_Copy_0 0;
BA_ "UserSigValidity" SG_ 992 SeatBeltSwSta_2ndRt_Copy_0 0;
BA_ "GenSigSendType" SG_ 992 SeatBeltSwSta_2ndRt_Copy_0 4;
BA_ "Description" SG_ 992 SeatBeltSwSta_2ndRt_Copy_0 "2nd Right Seat Belt Switch Status

This signal is set as 'Not Supported' if the seat belt is not installed for EDR law(UN ECE R160.01) and EURO NCAP";
BA_ "Version" SG_ 992 SeatBeltSwSta_3rdLft_Copy_0 "23.07.03";
BA_ "NetworkRequestHoldingTime" SG_ 992 SeatBeltSwSta_3rdLft_Copy_0 5000;
BA_ "NetworkRequest" SG_ 992 SeatBeltSwSta_3rdLft_Copy_0 0;
BA_ "UserSigValidity" SG_ 992 SeatBeltSwSta_3rdLft_Copy_0 0;
BA_ "GenSigSendType" SG_ 992 SeatBeltSwSta_3rdLft_Copy_0 4;
BA_ "Description" SG_ 992 SeatBeltSwSta_3rdLft_Copy_0 "3rd Left Seat Belt Switch Status

This signal is set as 'Not Supported' if the seat belt is not installed for EDR law(UN ECE R160.01) and EURO NCAP";
BA_ "Version" SG_ 992 SeatBeltSwSta_3rdCtr_Copy_0 "23.07.03";
BA_ "NetworkRequestHoldingTime" SG_ 992 SeatBeltSwSta_3rdCtr_Copy_0 5000;
BA_ "NetworkRequest" SG_ 992 SeatBeltSwSta_3rdCtr_Copy_0 0;
BA_ "UserSigValidity" SG_ 992 SeatBeltSwSta_3rdCtr_Copy_0 0;
BA_ "GenSigSendType" SG_ 992 SeatBeltSwSta_3rdCtr_Copy_0 4;
BA_ "Description" SG_ 992 SeatBeltSwSta_3rdCtr_Copy_0 "3rd Center Seat Belt Switch Status

This signal is set as 'Not Supported' if the seat belt is not installed for EDR law(UN ECE R160.01) and EURO NCAP";
BA_ "Version" SG_ 992 SeatBeltSwSta_3rdRt_Copy_0 "23.07.03";
BA_ "NetworkRequestHoldingTime" SG_ 992 SeatBeltSwSta_3rdRt_Copy_0 5000;
BA_ "NetworkRequest" SG_ 992 SeatBeltSwSta_3rdRt_Copy_0 0;
BA_ "UserSigValidity" SG_ 992 SeatBeltSwSta_3rdRt_Copy_0 0;
BA_ "GenSigSendType" SG_ 992 SeatBeltSwSta_3rdRt_Copy_0 4;
BA_ "Description" SG_ 992 SeatBeltSwSta_3rdRt_Copy_0 "3rd Right Seat Belt Switch Status

This signal is set as 'Not Supported' if the seat belt is not installed for EDR law(UN ECE R160.01) and EURO NCAP";
BA_ "Version" SG_ 992 SeatBelt4th_InstallInfo_Copy_0 "23.07.05";
BA_ "NetworkRequestHoldingTime" SG_ 992 SeatBelt4th_InstallInfo_Copy_0 5000;
BA_ "NetworkRequest" SG_ 992 SeatBelt4th_InstallInfo_Copy_0 0;
BA_ "UserSigValidity" SG_ 992 SeatBelt4th_InstallInfo_Copy_0 0;
BA_ "GenSigSendType" SG_ 992 SeatBelt4th_InstallInfo_Copy_0 4;
BA_ "Description" SG_ 992 SeatBelt4th_InstallInfo_Copy_0 "4th Seat Belt installation Information";
BA_ "Version" SG_ 992 PDCex_CurtainOpt "23.07.04";
BA_ "UserSigValidity" SG_ 992 PDCex_CurtainOpt 0;
BA_ "GenSigSendType" SG_ 992 PDCex_CurtainOpt 4;
BA_ "Description" SG_ 992 PDCex_CurtainOpt "PDCex Curtain Option Information

0x0 : No Curtain

0x1 : Rear Curtain Only

0x2 : Quarter Glass Curtain Only

0x3 : All Curtain(Rear+Quarter Glass Curtain)";
BA_ "Version" SG_ 992 Reprogram_State_PDC2 "24.04.09";
BA_ "NetworkRequestHoldingTime" SG_ 992 Reprogram_State_PDC2 5000;
BA_ "NetworkRequest" SG_ 992 Reprogram_State_PDC2 0;
BA_ "UserSigValidity" SG_ 992 Reprogram_State_PDC2 0;
BA_ "TimeoutValue" SG_ 992 Reprogram_State_PDC2 "0x1";
BA_ "GenSigStartValue" SG_ 992 Reprogram_State_PDC2 3;
BA_ "GenSigSendType" SG_ 992 Reprogram_State_PDC2 4;
BA_ "Description" SG_ 992 Reprogram_State_PDC2 "This signal indicates reprogramming progress of PDC.

0x0: normal operation / 0x1: reprogramming / 0x2: RESERVED /0x3: Invalid (default)";
BA_ "Version" SG_ 992 Warn_RrCTRSBRMATSwSta "24.05.00";
BA_ "NetworkRequestHoldingTime" SG_ 992 Warn_RrCTRSBRMATSwSta 5000;
BA_ "NetworkRequest" SG_ 992 Warn_RrCTRSBRMATSwSta 0;
BA_ "UserSigValidity" SG_ 992 Warn_RrCTRSBRMATSwSta 0;
BA_ "GenSigSendType" SG_ 992 Warn_RrCTRSBRMATSwSta 4;
BA_ "Description" SG_ 992 Warn_RrCTRSBRMATSwSta "2nd Center SBR MAT Switch State";
BA_ "Version" SG_ 992 C_3rdRCSBRMatSw "24.05.00";
BA_ "NetworkRequestHoldingTime" SG_ 992 C_3rdRCSBRMatSw 5000;
BA_ "NetworkRequest" SG_ 992 C_3rdRCSBRMatSw 0;
BA_ "UserSigValidity" SG_ 992 C_3rdRCSBRMatSw 0;
BA_ "GenSigSendType" SG_ 992 C_3rdRCSBRMatSw 4;
BA_ "Description" SG_ 992 C_3rdRCSBRMatSw "3rd Rear Center SBR MAT Switch State";
BA_ "Version" SG_ 992 DriveTypeOption_Copy_0 "21.11.00";
BA_ "NetworkRequestHoldingTime" SG_ 992 DriveTypeOption_Copy_0 5000;
BA_ "NetworkRequest" SG_ 992 DriveTypeOption_Copy_0 0;
BA_ "UserSigValidity" SG_ 992 DriveTypeOption_Copy_0 0;
BA_ "GenSigSendType" SG_ 992 DriveTypeOption_Copy_0 4;
BA_ "Description" SG_ 992 DriveTypeOption_Copy_0 "Drive Type Option

This signal is used to determine driver's seat position('Drive Type') about this vehicle.";
BA_ "Version" SG_ 992 AutoLtOpt_Copy_0 "20.09.00";
BA_ "UserSigValidity" SG_ 992 AutoLtOpt_Copy_0 0;
BA_ "GenSigSendType" SG_ 992 AutoLtOpt_Copy_0 4;
BA_ "Description" SG_ 992 AutoLtOpt_Copy_0 "Auto Light ╗ч╛ч └√┐ы ┐й║╬ ╣╫ └√┐ы ┐╔╝╟ ┴д║╕ ├т╖┬ (╣╠└√┐ы/└√┐ы)";
BA_ "Version" SG_ 992 HLmpLoHiOptLtSrcTyp_Copy_0 "20.09.00";
BA_ "UserSigValidity" SG_ 992 HLmpLoHiOptLtSrcTyp_Copy_0 0;
BA_ "GenSigSendType" SG_ 992 HLmpLoHiOptLtSrcTyp_Copy_0 4;
BA_ "Description" SG_ 992 HLmpLoHiOptLtSrcTyp_Copy_0 "Head Low and High Lamp Option and Light Source Type";
BA_ "Version" SG_ 992 C_StrgWhlHeatingOpt_Copy_0 "23.02.02";
BA_ "UserSigValidity" SG_ 992 C_StrgWhlHeatingOpt_Copy_0 0;
BA_ "GenSigSendType" SG_ 992 C_StrgWhlHeatingOpt_Copy_0 4;
BA_ "Description" SG_ 992 C_StrgWhlHeatingOpt_Copy_0 "Steering wheel heating option signal";
BA_ "Version" SG_ 992 C_StrgWhlHeatingSWInf_Copy_0 "19.11.11";
BA_ "UserSigValidity" SG_ 992 C_StrgWhlHeatingSWInf_Copy_0 3;
BA_ "GenSigSendType" SG_ 992 C_StrgWhlHeatingSWInf_Copy_0 4;
BA_ "Description" SG_ 992 C_StrgWhlHeatingSWInf_Copy_0 "Steering wheel heating Step information signal";
BA_ "Version" SG_ 992 ICU_MtGearPosRSta_Copy_0 "21.07.05";
BA_ "UserSigValidity" SG_ 992 ICU_MtGearPosRSta_Copy_0 3;
BA_ "GenSigSendType" SG_ 992 ICU_MtGearPosRSta_Copy_0 4;
BA_ "Description" SG_ 992 ICU_MtGearPosRSta_Copy_0 "Manual Shift Lever R Switch Status 0x0:Off/0x1:On";
BA_ "Version" SG_ 992 C_AutoLeverManualSW_Copy_0 "19.09.06";
BA_ "UserSigValidity" SG_ 992 C_AutoLeverManualSW_Copy_0 3;
BA_ "GenSigSendType" SG_ 992 C_AutoLeverManualSW_Copy_0 4;
BA_ "Description" SG_ 992 C_AutoLeverManualSW_Copy_0 "This signal represents operating status of AT/CVT/DCT Lever Manual Switch";
BA_ "Version" SG_ 992 Warn_HoodSwMemorySta_Copy_0 "21.11.00";
BA_ "NetworkRequestHoldingTime" SG_ 992 Warn_HoodSwMemorySta_Copy_0 5000;
BA_ "NetworkRequest" SG_ 992 Warn_HoodSwMemorySta_Copy_0 0;
BA_ "UserSigValidity" SG_ 992 Warn_HoodSwMemorySta_Copy_0 3;
BA_ "GenSigSendType" SG_ 992 Warn_HoodSwMemorySta_Copy_0 4;
BA_ "Description" SG_ 992 Warn_HoodSwMemorySta_Copy_0 "Hood swtich open->close information(memory)



This signal is for oil level warning lamp reset In case hood open->close when IG-OFF, 0x01 sent for 5 sec at next IG-ON";
BA_ "Version" SG_ 992 Warn_PrkngBrkSwSta_Copy_0 "17.12.00";
BA_ "NetworkRequestHoldingTime" SG_ 992 Warn_PrkngBrkSwSta_Copy_0 5000;
BA_ "NetworkRequest" SG_ 992 Warn_PrkngBrkSwSta_Copy_0 0;
BA_ "UserSigValidity" SG_ 992 Warn_PrkngBrkSwSta_Copy_0 0;
BA_ "GenSigSendType" SG_ 992 Warn_PrkngBrkSwSta_Copy_0 4;
BA_ "Version" SG_ 992 PrkngBrkNotchSwState_Copy_0 "20.08.07";
BA_ "NetworkRequestHoldingTime" SG_ 992 PrkngBrkNotchSwState_Copy_0 5000;
BA_ "NetworkRequest" SG_ 992 PrkngBrkNotchSwState_Copy_0 0;
BA_ "UserSigValidity" SG_ 992 PrkngBrkNotchSwState_Copy_0 0;
BA_ "GenSigSendType" SG_ 992 PrkngBrkNotchSwState_Copy_0 4;
BA_ "Description" SG_ 992 PrkngBrkNotchSwState_Copy_0 "Parking Brake High Notch Switch State";
BA_ "Version" SG_ 992 Warn_BrkFldSwSta_Copy_0 "17.12.00";
BA_ "NetworkRequestHoldingTime" SG_ 992 Warn_BrkFldSwSta_Copy_0 5000;
BA_ "NetworkRequest" SG_ 992 Warn_BrkFldSwSta_Copy_0 0;
BA_ "UserSigValidity" SG_ 992 Warn_BrkFldSwSta_Copy_0 0;
BA_ "GenSigSendType" SG_ 992 Warn_BrkFldSwSta_Copy_0 4;
BA_ "Version" SG_ 992 Warn_WshrFldSwSta_Copy_0 "21.07.05";
BA_ "NetworkRequestHoldingTime" SG_ 992 Warn_WshrFldSwSta_Copy_0 5000;
BA_ "NetworkRequest" SG_ 992 Warn_WshrFldSwSta_Copy_0 0;
BA_ "UserSigValidity" SG_ 992 Warn_WshrFldSwSta_Copy_0 3;
BA_ "GenSigSendType" SG_ 992 Warn_WshrFldSwSta_Copy_0 4;
BA_ "Description" SG_ 992 Warn_WshrFldSwSta_Copy_0 "Washer Fluid Switch Signal

This signal indicates Washer Fluid Switch Signal

0x0:Off/0x1:On";
BA_ "Version" SG_ 992 Warn_DrvStBltSwSta_Copy_0 "17.12.00";
BA_ "NetworkRequestHoldingTime" SG_ 992 Warn_DrvStBltSwSta_Copy_0 5000;
BA_ "NetworkRequest" SG_ 992 Warn_DrvStBltSwSta_Copy_0 0;
BA_ "UserSigValidity" SG_ 992 Warn_DrvStBltSwSta_Copy_0 0;
BA_ "GenSigSendType" SG_ 992 Warn_DrvStBltSwSta_Copy_0 4;
BA_ "Version" SG_ 992 Warn_AsstStBltSwSta_Copy_0 "17.12.00";
BA_ "NetworkRequestHoldingTime" SG_ 992 Warn_AsstStBltSwSta_Copy_0 5000;
BA_ "NetworkRequest" SG_ 992 Warn_AsstStBltSwSta_Copy_0 0;
BA_ "UserSigValidity" SG_ 992 Warn_AsstStBltSwSta_Copy_0 0;
BA_ "GenSigStartValue" SG_ 992 Warn_AsstStBltSwSta_Copy_0 1;
BA_ "GenSigSendType" SG_ 992 Warn_AsstStBltSwSta_Copy_0 4;
BA_ "Description" SG_ 992 Warn_AsstStBltSwSta_Copy_0 "-Default value: 0x1 (Belt)



-Initial value: 0x1 (Belt)



-Timeout value: 0x1 (Belt)";
BA_ "Version" SG_ 992 Warn_RrLftStBltSwSta_Copy_0 "17.12.00";
BA_ "NetworkRequestHoldingTime" SG_ 992 Warn_RrLftStBltSwSta_Copy_0 5000;
BA_ "NetworkRequest" SG_ 992 Warn_RrLftStBltSwSta_Copy_0 0;
BA_ "UserSigValidity" SG_ 992 Warn_RrLftStBltSwSta_Copy_0 0;
BA_ "GenSigSendType" SG_ 992 Warn_RrLftStBltSwSta_Copy_0 4;
BA_ "Version" SG_ 992 Warn_RrCtrStBltSwSta_Copy_0 "17.12.00";
BA_ "NetworkRequestHoldingTime" SG_ 992 Warn_RrCtrStBltSwSta_Copy_0 5000;
BA_ "NetworkRequest" SG_ 992 Warn_RrCtrStBltSwSta_Copy_0 0;
BA_ "UserSigValidity" SG_ 992 Warn_RrCtrStBltSwSta_Copy_0 0;
BA_ "GenSigSendType" SG_ 992 Warn_RrCtrStBltSwSta_Copy_0 4;
BA_ "Version" SG_ 992 Warn_RrRtStBltSwSta_Copy_0 "17.12.00";
BA_ "NetworkRequestHoldingTime" SG_ 992 Warn_RrRtStBltSwSta_Copy_0 5000;
BA_ "NetworkRequest" SG_ 992 Warn_RrRtStBltSwSta_Copy_0 0;
BA_ "UserSigValidity" SG_ 992 Warn_RrRtStBltSwSta_Copy_0 0;
BA_ "GenSigSendType" SG_ 992 Warn_RrRtStBltSwSta_Copy_0 4;
BA_ "Version" SG_ 992 C_3rdRLSeatBeltSW_Copy_0 "18.03.04";
BA_ "NetworkRequestHoldingTime" SG_ 992 C_3rdRLSeatBeltSW_Copy_0 5000;
BA_ "NetworkRequest" SG_ 992 C_3rdRLSeatBeltSW_Copy_0 0;
BA_ "UserSigValidity" SG_ 992 C_3rdRLSeatBeltSW_Copy_0 0;
BA_ "GenSigSendType" SG_ 992 C_3rdRLSeatBeltSW_Copy_0 4;
BA_ "Description" SG_ 992 C_3rdRLSeatBeltSW_Copy_0 "3rd Rear Left Seat Belt Switch Status";
BA_REL_ "GenSigTimeoutTime" BU_SG_REL_ GW_BDC_FD SG_ 2281701552 SLV_BLE_ConnectedDeviceInfo 1500;
BA_REL_ "GenSigTimeoutTime" BU_SG_REL_ L_UWB_BLE_MST_FD SG_ 2281701552 SLV_BLE_ConnectedDeviceInfo 1500;
BA_REL_ "GenSigTimeoutTime" BU_SG_REL_ GW_BDC_FD SG_ 2281701552 SLV_BLE_Passive_ADV_State 1500;
BA_REL_ "GenSigTimeoutTime" BU_SG_REL_ L_UWB_BLE_MST_FD SG_ 2281701552 SLV_BLE_Passive_ADV_State 1500;
BA_REL_ "GenSigTimeoutTime" BU_SG_REL_ GW_BDC_FD SG_ 2281701552 SLV_BLE_NewDeviceConnetStatus 1500;
BA_REL_ "GenSigTimeoutTime" BU_SG_REL_ L_UWB_BLE_MST_FD SG_ 2281701552 SLV_BLE_NewDeviceConnetStatus 1500;
BA_REL_ "GenSigTimeoutTime" BU_SG_REL_ GW_BDC_FD SG_ 2281701552 SLV_BLE_PairingResult 1500;
BA_REL_ "GenSigTimeoutTime" BU_SG_REL_ L_UWB_BLE_MST_FD SG_ 2281701552 SLV_BLE_PairingResult 1500;
BA_REL_ "GenSigTimeoutTime" BU_SG_REL_ GW_BDC_FD SG_ 2281701552 SLV_BLE_BondingDataStatus 1500;
BA_REL_ "GenSigTimeoutTime" BU_SG_REL_ L_UWB_BLE_MST_FD SG_ 2281701552 SLV_BLE_BondingDataStatus 1500;
BA_REL_ "GenSigTimeoutTime" BU_SG_REL_ L_EDT_FD SG_ 2281701552 SLV_BLE_InternalStatus 1500;
BA_REL_ "GenSigTimeoutTime" BU_SG_REL_ L_UWB_BLE_MST_FD SG_ 2281701552 SLV_BLE_InternalStatus 1500;
BA_REL_ "GenSigTimeoutTime" BU_SG_REL_ GW_BDC_FD SG_ 2281701552 SLV_BLE_DK_ID1 1500;
BA_REL_ "GenSigTimeoutTime" BU_SG_REL_ GW_BDC_FD SG_ 2281701552 SLV_BLE_RSSI1 1500;
BA_REL_ "GenSigTimeoutTime" BU_SG_REL_ GW_BDC_FD SG_ 2281701552 SLV_BLE_DK_ID2 1500;
BA_REL_ "GenSigTimeoutTime" BU_SG_REL_ GW_BDC_FD SG_ 2281701552 SLV_BLE_RSSI2 1500;
BA_REL_ "GenSigTimeoutTime" BU_SG_REL_ GW_BDC_FD SG_ 2281701552 SLV_BLE_DK_ID3 1500;
BA_REL_ "GenSigTimeoutTime" BU_SG_REL_ GW_BDC_FD SG_ 2281701552 SLV_BLE_RSSI3 1500;
BA_REL_ "GenSigTimeoutTime" BU_SG_REL_ GW_BDC_FD SG_ 2281701552 SLV_BLE_DK_ID4 1500;
BA_REL_ "GenSigTimeoutTime" BU_SG_REL_ GW_BDC_FD SG_ 2281701552 SLV_BLE_RSSI4 1500;
BA_REL_ "GenSigTimeoutTime" BU_SG_REL_ GW_BDC_FD SG_ 2281701552 SLV_BLE_BTAddIRK_Update 1500;
BA_REL_ "GenSigTimeoutTime" BU_SG_REL_ L_UWB_BLE_MST_FD SG_ 2281701552 SLV_BLE_BTAddIRK_Update 1500;
BA_REL_ "GenSigTimeoutTime" BU_SG_REL_ L_TPMS_FD SG_ 2006 GST_TPMS_Byte0 0;
BA_REL_ "GenSigTimeoutTime" BU_SG_REL_ L_TPMS_FD SG_ 2006 GST_TPMS_Byte2 0;
BA_REL_ "GenSigTimeoutTime" BU_SG_REL_ L_TPMS_FD SG_ 2006 GST_TPMS_Byte3 0;
BA_REL_ "GenSigTimeoutTime" BU_SG_REL_ L_TPMS_FD SG_ 2006 GST_TPMS_Byte4 0;
BA_REL_ "GenSigTimeoutTime" BU_SG_REL_ L_TPMS_FD SG_ 2006 GST_TPMS_Byte5 0;
BA_REL_ "GenSigTimeoutTime" BU_SG_REL_ L_TPMS_FD SG_ 2006 GST_TPMS_Byte6 0;
BA_REL_ "GenSigTimeoutTime" BU_SG_REL_ L_TPMS_FD SG_ 2006 GST_TPMS_Byte7 0;
BA_REL_ "GenSigTimeoutTime" BU_SG_REL_ L_TPMS_FD SG_ 2006 GST_TPMS_Byte1 0;
BA_REL_ "GenSigTimeoutTime" BU_SG_REL_ GW_BDC_FD SG_ 2014 TPMS_GST_Byte0 0;
BA_REL_ "GenSigTimeoutTime" BU_SG_REL_ GW_BDC_FD SG_ 2014 TPMS_GST_Byte2 0;
BA_REL_ "GenSigTimeoutTime" BU_SG_REL_ GW_BDC_FD SG_ 2014 TPMS_GST_Byte3 0;
BA_REL_ "GenSigTimeoutTime" BU_SG_REL_ GW_BDC_FD SG_ 2014 TPMS_GST_Byte4 0;
BA_REL_ "GenSigTimeoutTime" BU_SG_REL_ GW_BDC_FD SG_ 2014 TPMS_GST_Byte5 0;
BA_REL_ "GenSigTimeoutTime" BU_SG_REL_ GW_BDC_FD SG_ 2014 TPMS_GST_Byte6 0;
BA_REL_ "GenSigTimeoutTime" BU_SG_REL_ GW_BDC_FD SG_ 2014 TPMS_GST_Byte7 0;
BA_REL_ "GenSigTimeoutTime" BU_SG_REL_ GW_BDC_FD SG_ 2014 TPMS_GST_Byte1 0;
BA_REL_ "GenSigTimeoutTime" BU_SG_REL_ L_DHL_FD SG_ 2015 GST_ALL_Byte0 0;
BA_REL_ "GenSigTimeoutTime" BU_SG_REL_ L_DHRL_FD SG_ 2015 GST_ALL_Byte0 0;
BA_REL_ "GenSigTimeoutTime" BU_SG_REL_ L_DHRR_FD SG_ 2015 GST_ALL_Byte0 0;
BA_REL_ "GenSigTimeoutTime" BU_SG_REL_ L_DHR_FD SG_ 2015 GST_ALL_Byte0 0;
BA_REL_ "GenSigTimeoutTime" BU_SG_REL_ L_ROA_FD SG_ 2015 GST_ALL_Byte0 0;
BA_REL_ "GenSigTimeoutTime" BU_SG_REL_ L_ROA_FR_FD SG_ 2015 GST_ALL_Byte0 0;
BA_REL_ "GenSigTimeoutTime" BU_SG_REL_ L_SAL_FD SG_ 2015 GST_ALL_Byte0 0;
BA_REL_ "GenSigTimeoutTime" BU_SG_REL_ L_UWB_BLE_MST_FD SG_ 2015 GST_ALL_Byte0 0;
BA_REL_ "GenSigTimeoutTime" BU_SG_REL_ L_WPC_FD SG_ 2015 GST_ALL_Byte0 0;
BA_REL_ "GenSigTimeoutTime" BU_SG_REL_ L_DHL_FD SG_ 2015 GST_ALL_Byte2 0;
BA_REL_ "GenSigTimeoutTime" BU_SG_REL_ L_DHRL_FD SG_ 2015 GST_ALL_Byte2 0;
BA_REL_ "GenSigTimeoutTime" BU_SG_REL_ L_DHRR_FD SG_ 2015 GST_ALL_Byte2 0;
BA_REL_ "GenSigTimeoutTime" BU_SG_REL_ L_DHR_FD SG_ 2015 GST_ALL_Byte2 0;
BA_REL_ "GenSigTimeoutTime" BU_SG_REL_ L_ROA_FD SG_ 2015 GST_ALL_Byte2 0;
BA_REL_ "GenSigTimeoutTime" BU_SG_REL_ L_ROA_FR_FD SG_ 2015 GST_ALL_Byte2 0;
BA_REL_ "GenSigTimeoutTime" BU_SG_REL_ L_SAL_FD SG_ 2015 GST_ALL_Byte2 0;
BA_REL_ "GenSigTimeoutTime" BU_SG_REL_ L_UWB_BLE_MST_FD SG_ 2015 GST_ALL_Byte2 0;
BA_REL_ "GenSigTimeoutTime" BU_SG_REL_ L_WPC_FD SG_ 2015 GST_ALL_Byte2 0;
BA_REL_ "GenSigTimeoutTime" BU_SG_REL_ L_DHL_FD SG_ 2015 GST_ALL_Byte3 0;
BA_REL_ "GenSigTimeoutTime" BU_SG_REL_ L_DHRL_FD SG_ 2015 GST_ALL_Byte3 0;
BA_REL_ "GenSigTimeoutTime" BU_SG_REL_ L_DHRR_FD SG_ 2015 GST_ALL_Byte3 0;
BA_REL_ "GenSigTimeoutTime" BU_SG_REL_ L_DHR_FD SG_ 2015 GST_ALL_Byte3 0;
BA_REL_ "GenSigTimeoutTime" BU_SG_REL_ L_ROA_FD SG_ 2015 GST_ALL_Byte3 0;
BA_REL_ "GenSigTimeoutTime" BU_SG_REL_ L_ROA_FR_FD SG_ 2015 GST_ALL_Byte3 0;
BA_REL_ "GenSigTimeoutTime" BU_SG_REL_ L_SAL_FD SG_ 2015 GST_ALL_Byte3 0;
BA_REL_ "GenSigTimeoutTime" BU_SG_REL_ L_UWB_BLE_MST_FD SG_ 2015 GST_ALL_Byte3 0;
BA_REL_ "GenSigTimeoutTime" BU_SG_REL_ L_WPC_FD SG_ 2015 GST_ALL_Byte3 0;
BA_REL_ "GenSigTimeoutTime" BU_SG_REL_ L_DHL_FD SG_ 2015 GST_ALL_Byte4 0;
BA_REL_ "GenSigTimeoutTime" BU_SG_REL_ L_DHRL_FD SG_ 2015 GST_ALL_Byte4 0;
BA_REL_ "GenSigTimeoutTime" BU_SG_REL_ L_DHRR_FD SG_ 2015 GST_ALL_Byte4 0;
BA_REL_ "GenSigTimeoutTime" BU_SG_REL_ L_DHR_FD SG_ 2015 GST_ALL_Byte4 0;
BA_REL_ "GenSigTimeoutTime" BU_SG_REL_ L_ROA_FD SG_ 2015 GST_ALL_Byte4 0;
BA_REL_ "GenSigTimeoutTime" BU_SG_REL_ L_ROA_FR_FD SG_ 2015 GST_ALL_Byte4 0;
BA_REL_ "GenSigTimeoutTime" BU_SG_REL_ L_SAL_FD SG_ 2015 GST_ALL_Byte4 0;
BA_REL_ "GenSigTimeoutTime" BU_SG_REL_ L_UWB_BLE_MST_FD SG_ 2015 GST_ALL_Byte4 0;
BA_REL_ "GenSigTimeoutTime" BU_SG_REL_ L_WPC_FD SG_ 2015 GST_ALL_Byte4 0;
BA_REL_ "GenSigTimeoutTime" BU_SG_REL_ L_DHL_FD SG_ 2015 GST_ALL_Byte5 0;
BA_REL_ "GenSigTimeoutTime" BU_SG_REL_ L_DHRL_FD SG_ 2015 GST_ALL_Byte5 0;
BA_REL_ "GenSigTimeoutTime" BU_SG_REL_ L_DHRR_FD SG_ 2015 GST_ALL_Byte5 0;
BA_REL_ "GenSigTimeoutTime" BU_SG_REL_ L_DHR_FD SG_ 2015 GST_ALL_Byte5 0;
BA_REL_ "GenSigTimeoutTime" BU_SG_REL_ L_ROA_FD SG_ 2015 GST_ALL_Byte5 0;
BA_REL_ "GenSigTimeoutTime" BU_SG_REL_ L_ROA_FR_FD SG_ 2015 GST_ALL_Byte5 0;
BA_REL_ "GenSigTimeoutTime" BU_SG_REL_ L_SAL_FD SG_ 2015 GST_ALL_Byte5 0;
BA_REL_ "GenSigTimeoutTime" BU_SG_REL_ L_UWB_BLE_MST_FD SG_ 2015 GST_ALL_Byte5 0;
BA_REL_ "GenSigTimeoutTime" BU_SG_REL_ L_WPC_FD SG_ 2015 GST_ALL_Byte5 0;
BA_REL_ "GenSigTimeoutTime" BU_SG_REL_ L_DHL_FD SG_ 2015 GST_ALL_Byte6 0;
BA_REL_ "GenSigTimeoutTime" BU_SG_REL_ L_DHRL_FD SG_ 2015 GST_ALL_Byte6 0;
BA_REL_ "GenSigTimeoutTime" BU_SG_REL_ L_DHRR_FD SG_ 2015 GST_ALL_Byte6 0;
BA_REL_ "GenSigTimeoutTime" BU_SG_REL_ L_DHR_FD SG_ 2015 GST_ALL_Byte6 0;
BA_REL_ "GenSigTimeoutTime" BU_SG_REL_ L_ROA_FD SG_ 2015 GST_ALL_Byte6 0;
BA_REL_ "GenSigTimeoutTime" BU_SG_REL_ L_ROA_FR_FD SG_ 2015 GST_ALL_Byte6 0;
BA_REL_ "GenSigTimeoutTime" BU_SG_REL_ L_SAL_FD SG_ 2015 GST_ALL_Byte6 0;
BA_REL_ "GenSigTimeoutTime" BU_SG_REL_ L_UWB_BLE_MST_FD SG_ 2015 GST_ALL_Byte6 0;
BA_REL_ "GenSigTimeoutTime" BU_SG_REL_ L_WPC_FD SG_ 2015 GST_ALL_Byte6 0;
BA_REL_ "GenSigTimeoutTime" BU_SG_REL_ L_DHL_FD SG_ 2015 GST_ALL_Byte7 0;
BA_REL_ "GenSigTimeoutTime" BU_SG_REL_ L_DHRL_FD SG_ 2015 GST_ALL_Byte7 0;
BA_REL_ "GenSigTimeoutTime" BU_SG_REL_ L_DHRR_FD SG_ 2015 GST_ALL_Byte7 0;
BA_REL_ "GenSigTimeoutTime" BU_SG_REL_ L_DHR_FD SG_ 2015 GST_ALL_Byte7 0;
BA_REL_ "GenSigTimeoutTime" BU_SG_REL_ L_ROA_FD SG_ 2015 GST_ALL_Byte7 0;
BA_REL_ "GenSigTimeoutTime" BU_SG_REL_ L_ROA_FR_FD SG_ 2015 GST_ALL_Byte7 0;
BA_REL_ "GenSigTimeoutTime" BU_SG_REL_ L_SAL_FD SG_ 2015 GST_ALL_Byte7 0;
BA_REL_ "GenSigTimeoutTime" BU_SG_REL_ L_UWB_BLE_MST_FD SG_ 2015 GST_ALL_Byte7 0;
BA_REL_ "GenSigTimeoutTime" BU_SG_REL_ L_WPC_FD SG_ 2015 GST_ALL_Byte7 0;
BA_REL_ "GenSigTimeoutTime" BU_SG_REL_ L_DHL_FD SG_ 2015 GST_ALL_Byte1 0;
BA_REL_ "GenSigTimeoutTime" BU_SG_REL_ L_DHRL_FD SG_ 2015 GST_ALL_Byte1 0;
BA_REL_ "GenSigTimeoutTime" BU_SG_REL_ L_DHRR_FD SG_ 2015 GST_ALL_Byte1 0;
BA_REL_ "GenSigTimeoutTime" BU_SG_REL_ L_DHR_FD SG_ 2015 GST_ALL_Byte1 0;
BA_REL_ "GenSigTimeoutTime" BU_SG_REL_ L_ROA_FD SG_ 2015 GST_ALL_Byte1 0;
BA_REL_ "GenSigTimeoutTime" BU_SG_REL_ L_ROA_FR_FD SG_ 2015 GST_ALL_Byte1 0;
BA_REL_ "GenSigTimeoutTime" BU_SG_REL_ L_SAL_FD SG_ 2015 GST_ALL_Byte1 0;
BA_REL_ "GenSigTimeoutTime" BU_SG_REL_ L_UWB_BLE_MST_FD SG_ 2015 GST_ALL_Byte1 0;
BA_REL_ "GenSigTimeoutTime" BU_SG_REL_ L_WPC_FD SG_ 2015 GST_ALL_Byte1 0;
BA_REL_ "GenSigTimeoutTime" BU_SG_REL_ L_UWB_BLE_MST_FD SG_ 2525339905 FL_SWID_3_IVD_2 0;
BA_REL_ "GenSigTimeoutTime" BU_SG_REL_ GW_BDC_FD SG_ 2281701536 MST_BLE_ConnectedDeviceInfo 1500;
BA_REL_ "GenSigTimeoutTime" BU_SG_REL_ L_UWB_BLE_SLV_FD SG_ 2281701536 MST_BLE_ConnectedDeviceInfo 1500;
BA_REL_ "GenSigTimeoutTime" BU_SG_REL_ GW_BDC_FD SG_ 2281701536 MST_BLE_OP_ADV_State 1500;
BA_REL_ "GenSigTimeoutTime" BU_SG_REL_ L_UWB_BLE_SLV_FD SG_ 2281701536 MST_BLE_OP_ADV_State 1500;
BA_REL_ "GenSigTimeoutTime" BU_SG_REL_ GW_BDC_FD SG_ 2281701536 MST_BLE_Passive_ADV_State 1500;
BA_REL_ "GenSigTimeoutTime" BU_SG_REL_ L_UWB_BLE_SLV_FD SG_ 2281701536 MST_BLE_Passive_ADV_State 1500;
BA_REL_ "GenSigTimeoutTime" BU_SG_REL_ GW_BDC_FD SG_ 2281701536 MST_BLE_NewDeviceConnetStatus 1500;
BA_REL_ "GenSigTimeoutTime" BU_SG_REL_ L_UWB_BLE_SLV_FD SG_ 2281701536 MST_BLE_NewDeviceConnetStatus 1500;
BA_REL_ "GenSigTimeoutTime" BU_SG_REL_ GW_BDC_FD SG_ 2281701536 MST_BLE_PairingResult 1500;
BA_REL_ "GenSigTimeoutTime" BU_SG_REL_ L_UWB_BLE_SLV_FD SG_ 2281701536 MST_BLE_PairingResult 1500;
BA_REL_ "GenSigTimeoutTime" BU_SG_REL_ GW_BDC_FD SG_ 2281701536 MST_BLE_BondingDataStatus 1500;
BA_REL_ "GenSigTimeoutTime" BU_SG_REL_ L_UWB_BLE_SLV_FD SG_ 2281701536 MST_BLE_BondingDataStatus 1500;
BA_REL_ "GenSigTimeoutTime" BU_SG_REL_ L_EDT_FD SG_ 2281701536 MST_BLE_InternalStatus 1500;
BA_REL_ "GenSigTimeoutTime" BU_SG_REL_ L_UWB_BLE_SLV_FD SG_ 2281701536 MST_BLE_InternalStatus 1500;
BA_REL_ "GenSigTimeoutTime" BU_SG_REL_ L_UWB_BLE_SLV_FD SG_ 2281701536 MST_Vehicle_Info 1500;
BA_REL_ "GenSigTimeoutTime" BU_SG_REL_ L_UWB_FL_FD SG_ 2281701536 MST_Vehicle_Info 1500;
BA_REL_ "GenSigTimeoutTime" BU_SG_REL_ L_UWB_FRNK_FD SG_ 2281701536 MST_Vehicle_Info 1500;
BA_REL_ "GenSigTimeoutTime" BU_SG_REL_ L_UWB_FR_FD SG_ 2281701536 MST_Vehicle_Info 1500;
BA_REL_ "GenSigTimeoutTime" BU_SG_REL_ L_UWB_RL_FD SG_ 2281701536 MST_Vehicle_Info 1500;
BA_REL_ "GenSigTimeoutTime" BU_SG_REL_ L_UWB_RR_FD SG_ 2281701536 MST_Vehicle_Info 1500;
BA_REL_ "GenSigTimeoutTime" BU_SG_REL_ L_UWB_TRNK_FD SG_ 2281701536 MST_Vehicle_Info 1500;
BA_REL_ "GenSigTimeoutTime" BU_SG_REL_ GW_BDC_FD SG_ 2281701536 MST_BLE_DK_ID1 1500;
BA_REL_ "GenSigTimeoutTime" BU_SG_REL_ GW_BDC_FD SG_ 2281701536 MST_BLE_RSSI1 1500;
BA_REL_ "GenSigTimeoutTime" BU_SG_REL_ GW_BDC_FD SG_ 2281701536 MST_BLE_DK_ID2 1500;
BA_REL_ "GenSigTimeoutTime" BU_SG_REL_ GW_BDC_FD SG_ 2281701536 MST_BLE_RSSI2 1500;
BA_REL_ "GenSigTimeoutTime" BU_SG_REL_ GW_BDC_FD SG_ 2281701536 MST_BLE_DK_ID3 1500;
BA_REL_ "GenSigTimeoutTime" BU_SG_REL_ GW_BDC_FD SG_ 2281701536 MST_BLE_RSSI3 1500;
BA_REL_ "GenSigTimeoutTime" BU_SG_REL_ GW_BDC_FD SG_ 2281701536 MST_BLE_DK_ID4 1500;
BA_REL_ "GenSigTimeoutTime" BU_SG_REL_ GW_BDC_FD SG_ 2281701536 MST_BLE_RSSI4 1500;
BA_REL_ "GenSigTimeoutTime" BU_SG_REL_ GW_BDC_FD SG_ 2281701536 MST_BLE_BTAddIRK_Update 1500;
BA_REL_ "GenSigTimeoutTime" BU_SG_REL_ L_UWB_BLE_SLV_FD SG_ 2281701536 MST_BLE_BTAddIRK_Update 1500;
BA_REL_ "GenSigTimeoutTime" BU_SG_REL_ L_EDT_FD SG_ 2281701537 MST_SW_MCU_Ver_Major 1500;
BA_REL_ "GenSigTimeoutTime" BU_SG_REL_ L_EDT_FD SG_ 2281701537 MST_SW_MCU_Ver_Minor 1500;
BA_REL_ "GenSigTimeoutTime" BU_SG_REL_ L_EDT_FD SG_ 2281701537 MST_SW_UWB_Ver_Major 1500;
BA_REL_ "GenSigTimeoutTime" BU_SG_REL_ L_EDT_FD SG_ 2281701537 MST_SW_UWB_Ver_Minor 1500;
BA_REL_ "GenSigTimeoutTime" BU_SG_REL_ L_EDT_FD SG_ 2281701537 MST_SW_BLE_Ver_Major 1500;
BA_REL_ "GenSigTimeoutTime" BU_SG_REL_ L_EDT_FD SG_ 2281701537 MST_SW_BLE_Ver_Minor 1500;
BA_REL_ "GenSigTimeoutTime" BU_SG_REL_ GW_BDC_FD SG_ 2281701537 MST_UWB_DK_LocalizationStat 1500;
BA_REL_ "GenSigTimeoutTime" BU_SG_REL_ GW_BDC_FD SG_ 2281701537 UWB_Applied_Info 1500;
BA_REL_ "GenSigTimeoutTime" BU_SG_REL_ L_EDT_FD SG_ 2281701537 MST_SW_UWB_2_Ver_Major 1500;
BA_REL_ "GenSigTimeoutTime" BU_SG_REL_ L_EDT_FD SG_ 2281701537 MST_SW_UWB_2_Ver_Minor 1500;
BA_REL_ "GenSigTimeoutTime" BU_SG_REL_ GW_BDC_FD SG_ 2281701537 MST_UWB_Status1 1500;
BA_REL_ "GenSigTimeoutTime" BU_SG_REL_ GW_BDC_FD SG_ 2281701537 MST_UWB_Status2 1500;
BA_REL_ "GenSigTimeoutTime" BU_SG_REL_ GW_BDC_FD SG_ 2281701537 MST_UWB_Status3 1500;
BA_REL_ "GenSigTimeoutTime" BU_SG_REL_ GW_BDC_FD SG_ 2281701537 MST_UWB_Status4 1500;
BA_REL_ "GenSigTimeoutTime" BU_SG_REL_ GW_BDC_FD SG_ 2281701537 MST_UWB_Status5 1500;
BA_REL_ "GenSigTimeoutTime" BU_SG_REL_ GW_BDC_FD SG_ 2281701537 MST_UWB_Status6 1500;
BA_REL_ "GenSigTimeoutTime" BU_SG_REL_ GW_BDC_FD SG_ 2281701537 MST_UWB_Status7 1500;
BA_REL_ "GenSigTimeoutTime" BU_SG_REL_ GW_BDC_FD SG_ 2281701537 MST_UWB_Status8 1500;
BA_REL_ "GenSigTimeoutTime" BU_SG_REL_ GW_BDC_FD SG_ 2281701537 MST_UWB_Status9 1500;
BA_REL_ "GenSigTimeoutTime" BU_SG_REL_ GW_BDC_FD SG_ 2281701537 MST_UWB_Status10 1500;
BA_REL_ "GenSigTimeoutTime" BU_SG_REL_ GW_BDC_FD SG_ 2281701537 MST_UWB_Status11 1500;
BA_REL_ "GenSigTimeoutTime" BU_SG_REL_ GW_BDC_FD SG_ 2281701537 MST_UWB_Status12 1500;
BA_REL_ "GenSigTimeoutTime" BU_SG_REL_ GW_BDC_FD SG_ 2281701537 MST_UWB_Status13 1500;
BA_REL_ "GenSigTimeoutTime" BU_SG_REL_ GW_BDC_FD SG_ 2281701537 MST_UWB_Status14 1500;
BA_REL_ "GenSigTimeoutTime" BU_SG_REL_ GW_BDC_FD SG_ 2281701537 MST_UWB_Status15 1500;
BA_REL_ "GenSigTimeoutTime" BU_SG_REL_ GW_BDC_FD SG_ 2281701537 MST_UWB_Status16 1500;
BA_REL_ "GenSigTimeoutTime" BU_SG_REL_ L_EDT_FD SG_ 2281701537 MST_HW_Ver_Major 1500;
BA_REL_ "GenSigTimeoutTime" BU_SG_REL_ L_EDT_FD SG_ 2281701537 MST_HW_Ver_Minor 1500;
BA_REL_ "GenSigTimeoutTime" BU_SG_REL_ L_ROA_FD SG_ 1504 GST_ROA_Byte0 0;
BA_REL_ "GenSigTimeoutTime" BU_SG_REL_ L_ROA_FD SG_ 1504 GST_ROA_Byte2 0;
BA_REL_ "GenSigTimeoutTime" BU_SG_REL_ L_ROA_FD SG_ 1504 GST_ROA_Byte3 0;
BA_REL_ "GenSigTimeoutTime" BU_SG_REL_ L_ROA_FD SG_ 1504 GST_ROA_Byte4 0;
BA_REL_ "GenSigTimeoutTime" BU_SG_REL_ L_ROA_FD SG_ 1504 GST_ROA_Byte5 0;
BA_REL_ "GenSigTimeoutTime" BU_SG_REL_ L_ROA_FD SG_ 1504 GST_ROA_Byte6 0;
BA_REL_ "GenSigTimeoutTime" BU_SG_REL_ L_ROA_FD SG_ 1504 GST_ROA_Byte7 0;
BA_REL_ "GenSigTimeoutTime" BU_SG_REL_ L_ROA_FD SG_ 1504 GST_ROA_Byte1 0;
BA_REL_ "GenSigTimeoutTime" BU_SG_REL_ GW_BDC_FD SG_ 1512 ROA_GST_Byte0 0;
BA_REL_ "GenSigTimeoutTime" BU_SG_REL_ GW_BDC_FD SG_ 1512 ROA_GST_Byte2 0;
BA_REL_ "GenSigTimeoutTime" BU_SG_REL_ GW_BDC_FD SG_ 1512 ROA_GST_Byte3 0;
BA_REL_ "GenSigTimeoutTime" BU_SG_REL_ GW_BDC_FD SG_ 1512 ROA_GST_Byte4 0;
BA_REL_ "GenSigTimeoutTime" BU_SG_REL_ GW_BDC_FD SG_ 1512 ROA_GST_Byte5 0;
BA_REL_ "GenSigTimeoutTime" BU_SG_REL_ GW_BDC_FD SG_ 1512 ROA_GST_Byte6 0;
BA_REL_ "GenSigTimeoutTime" BU_SG_REL_ GW_BDC_FD SG_ 1512 ROA_GST_Byte7 0;
BA_REL_ "GenSigTimeoutTime" BU_SG_REL_ GW_BDC_FD SG_ 1512 ROA_GST_Byte1 0;
BA_REL_ "GenSigTimeoutTime" BU_SG_REL_ L_UWB_BLE_MST_FD SG_ 2281701584 UWB_FR_SW_MCU_Ver_Major 1500;
BA_REL_ "GenSigTimeoutTime" BU_SG_REL_ L_UWB_BLE_MST_FD SG_ 2281701584 UWB_FR_SW_MCU_Ver_Minor 1500;
BA_REL_ "GenSigTimeoutTime" BU_SG_REL_ L_UWB_BLE_MST_FD SG_ 2281701584 UWB_FR_SW_IC_Ver_Major 1500;
BA_REL_ "GenSigTimeoutTime" BU_SG_REL_ L_UWB_BLE_MST_FD SG_ 2281701584 UWB_FR_SW_IC_Ver_Minor 1500;
BA_REL_ "GenSigTimeoutTime" BU_SG_REL_ L_UWB_BLE_MST_FD SG_ 2281701584 UWB_FR_DTC 1500;
BA_REL_ "GenSigTimeoutTime" BU_SG_REL_ GW_BDC_FD SG_ 2281701584 UWB_FR_Status1 1500;
BA_REL_ "GenSigTimeoutTime" BU_SG_REL_ L_UWB_BLE_MST_FD SG_ 2281701584 UWB_FR_Status1 1500;
BA_REL_ "GenSigTimeoutTime" BU_SG_REL_ GW_BDC_FD SG_ 2281701584 UWB_FR_Status2 1500;
BA_REL_ "GenSigTimeoutTime" BU_SG_REL_ L_UWB_BLE_MST_FD SG_ 2281701584 UWB_FR_Status2 1500;
BA_REL_ "GenSigTimeoutTime" BU_SG_REL_ GW_BDC_FD SG_ 2281701584 UWB_FR_Status3 1500;
BA_REL_ "GenSigTimeoutTime" BU_SG_REL_ L_UWB_BLE_MST_FD SG_ 2281701584 UWB_FR_Status3 1500;
BA_REL_ "GenSigTimeoutTime" BU_SG_REL_ GW_BDC_FD SG_ 2281701584 UWB_FR_Status4 1500;
BA_REL_ "GenSigTimeoutTime" BU_SG_REL_ L_UWB_BLE_MST_FD SG_ 2281701584 UWB_FR_Status4 1500;
BA_REL_ "GenSigTimeoutTime" BU_SG_REL_ GW_BDC_FD SG_ 2281701584 UWB_FR_Status5 1500;
BA_REL_ "GenSigTimeoutTime" BU_SG_REL_ L_UWB_BLE_MST_FD SG_ 2281701584 UWB_FR_Status5 1500;
BA_REL_ "GenSigTimeoutTime" BU_SG_REL_ GW_BDC_FD SG_ 2281701584 UWB_FR_Status6 1500;
BA_REL_ "GenSigTimeoutTime" BU_SG_REL_ L_UWB_BLE_MST_FD SG_ 2281701584 UWB_FR_Status6 1500;
BA_REL_ "GenSigTimeoutTime" BU_SG_REL_ GW_BDC_FD SG_ 2281701584 UWB_FR_Status7 1500;
BA_REL_ "GenSigTimeoutTime" BU_SG_REL_ L_UWB_BLE_MST_FD SG_ 2281701584 UWB_FR_Status7 1500;
BA_REL_ "GenSigTimeoutTime" BU_SG_REL_ GW_BDC_FD SG_ 2281701584 UWB_FR_Status8 1500;
BA_REL_ "GenSigTimeoutTime" BU_SG_REL_ L_UWB_BLE_MST_FD SG_ 2281701584 UWB_FR_Status8 1500;
BA_REL_ "GenSigTimeoutTime" BU_SG_REL_ GW_BDC_FD SG_ 2281701584 UWB_FR_Status9 1500;
BA_REL_ "GenSigTimeoutTime" BU_SG_REL_ L_UWB_BLE_MST_FD SG_ 2281701584 UWB_FR_Status9 1500;
BA_REL_ "GenSigTimeoutTime" BU_SG_REL_ GW_BDC_FD SG_ 2281701584 UWB_FR_Status10 1500;
BA_REL_ "GenSigTimeoutTime" BU_SG_REL_ L_UWB_BLE_MST_FD SG_ 2281701584 UWB_FR_Status10 1500;
BA_REL_ "GenSigTimeoutTime" BU_SG_REL_ GW_BDC_FD SG_ 2281701584 UWB_FR_Status11 1500;
BA_REL_ "GenSigTimeoutTime" BU_SG_REL_ L_UWB_BLE_MST_FD SG_ 2281701584 UWB_FR_Status11 1500;
BA_REL_ "GenSigTimeoutTime" BU_SG_REL_ GW_BDC_FD SG_ 2281701584 UWB_FR_Status12 1500;
BA_REL_ "GenSigTimeoutTime" BU_SG_REL_ L_UWB_BLE_MST_FD SG_ 2281701584 UWB_FR_Status12 1500;
BA_REL_ "GenSigTimeoutTime" BU_SG_REL_ GW_BDC_FD SG_ 2281701584 UWB_FR_Status13 1500;
BA_REL_ "GenSigTimeoutTime" BU_SG_REL_ L_UWB_BLE_MST_FD SG_ 2281701584 UWB_FR_Status13 1500;
BA_REL_ "GenSigTimeoutTime" BU_SG_REL_ GW_BDC_FD SG_ 2281701584 UWB_FR_Status14 1500;
BA_REL_ "GenSigTimeoutTime" BU_SG_REL_ L_UWB_BLE_MST_FD SG_ 2281701584 UWB_FR_Status14 1500;
BA_REL_ "GenSigTimeoutTime" BU_SG_REL_ GW_BDC_FD SG_ 2281701584 UWB_FR_Status15 1500;
BA_REL_ "GenSigTimeoutTime" BU_SG_REL_ L_UWB_BLE_MST_FD SG_ 2281701584 UWB_FR_Status15 1500;
BA_REL_ "GenSigTimeoutTime" BU_SG_REL_ GW_BDC_FD SG_ 2281701584 UWB_FR_Status16 1500;
BA_REL_ "GenSigTimeoutTime" BU_SG_REL_ L_UWB_BLE_MST_FD SG_ 2281701584 UWB_FR_Status16 1500;
BA_REL_ "GenSigTimeoutTime" BU_SG_REL_ L_UWB_BLE_MST_FD SG_ 2281701584 UWB_FR_HW_Ver_Major 1500;
BA_REL_ "GenSigTimeoutTime" BU_SG_REL_ L_UWB_BLE_MST_FD SG_ 2281701584 UWB_FR_HW_Ver_Minor 1500;
BA_REL_ "GenSigTimeoutTime" BU_SG_REL_ GW_BDC_FD SG_ 2348810256 TPMS_TpsSnsrDataVal 0;
BA_REL_ "GenSigTimeoutTime" BU_SG_REL_ GW_BDC_FD SG_ 2348810256 TPMS_SensorRssiVal 0;
BA_REL_ "GenSigTimeoutTime" BU_SG_REL_ GW_BDC_FD SG_ 2348810256 TPMS_LastTpsSnsrDataVal 0;
BA_REL_ "GenSigTimeoutTime" BU_SG_REL_ GW_BDC_FD SG_ 2348810257 TPMS_RficErrStatus 1500;
BA_REL_ "GenSigTimeoutTime" BU_SG_REL_ GW_BDC_FD SG_ 2348810257 TPMS_NoiseRssiVal 1500;
BA_REL_ "GenSigTimeoutTime" BU_SG_REL_ L_UWB_BLE_MST_FD SG_ 2533736449 TRNK_SWID_3_IVD_1 0;
BA_REL_ "GenSigTimeoutTime" BU_SG_REL_ L_UWB_BLE_MST_FD SG_ 2529538049 RL_SWID_3_IVD_1 0;
BA_REL_ "GenSigTimeoutTime" BU_SG_REL_ L_UWB_BLE_MST_FD SG_ 1410 GST_UWB_BLE_Master_Byte0 0;
BA_REL_ "GenSigTimeoutTime" BU_SG_REL_ L_UWB_BLE_MST_FD SG_ 1410 GST_UWB_BLE_Master_Byte2 0;
BA_REL_ "GenSigTimeoutTime" BU_SG_REL_ L_UWB_BLE_MST_FD SG_ 1410 GST_UWB_BLE_Master_Byte3 0;
BA_REL_ "GenSigTimeoutTime" BU_SG_REL_ L_UWB_BLE_MST_FD SG_ 1410 GST_UWB_BLE_Master_Byte4 0;
BA_REL_ "GenSigTimeoutTime" BU_SG_REL_ L_UWB_BLE_MST_FD SG_ 1410 GST_UWB_BLE_Master_Byte5 0;
BA_REL_ "GenSigTimeoutTime" BU_SG_REL_ L_UWB_BLE_MST_FD SG_ 1410 GST_UWB_BLE_Master_Byte6 0;
BA_REL_ "GenSigTimeoutTime" BU_SG_REL_ L_UWB_BLE_MST_FD SG_ 1410 GST_UWB_BLE_Master_Byte7 0;
BA_REL_ "GenSigTimeoutTime" BU_SG_REL_ L_UWB_BLE_MST_FD SG_ 1410 GST_UWB_BLE_Master_Byte1 0;
BA_REL_ "GenSigTimeoutTime" BU_SG_REL_ L_UWB_BLE_MST_FD SG_ 2281701568 UWB_FL_SW_MCU_Ver_Major 1500;
BA_REL_ "GenSigTimeoutTime" BU_SG_REL_ L_UWB_BLE_MST_FD SG_ 2281701568 UWB_FL_SW_MCU_Ver_Minor 1500;
BA_REL_ "GenSigTimeoutTime" BU_SG_REL_ L_UWB_BLE_MST_FD SG_ 2281701568 UWB_FL_SW_IC_Ver_Major 1500;
BA_REL_ "GenSigTimeoutTime" BU_SG_REL_ L_UWB_BLE_MST_FD SG_ 2281701568 UWB_FL_SW_IC_Ver_Minor 1500;
BA_REL_ "GenSigTimeoutTime" BU_SG_REL_ L_UWB_BLE_MST_FD SG_ 2281701568 UWB_FL_DTC 1500;
BA_REL_ "GenSigTimeoutTime" BU_SG_REL_ GW_BDC_FD SG_ 2281701568 UWB_FL_Status1 1500;
BA_REL_ "GenSigTimeoutTime" BU_SG_REL_ L_UWB_BLE_MST_FD SG_ 2281701568 UWB_FL_Status1 1500;
BA_REL_ "GenSigTimeoutTime" BU_SG_REL_ GW_BDC_FD SG_ 2281701568 UWB_FL_Status2 1500;
BA_REL_ "GenSigTimeoutTime" BU_SG_REL_ L_UWB_BLE_MST_FD SG_ 2281701568 UWB_FL_Status2 1500;
BA_REL_ "GenSigTimeoutTime" BU_SG_REL_ GW_BDC_FD SG_ 2281701568 UWB_FL_Status3 1500;
BA_REL_ "GenSigTimeoutTime" BU_SG_REL_ L_UWB_BLE_MST_FD SG_ 2281701568 UWB_FL_Status3 1500;
BA_REL_ "GenSigTimeoutTime" BU_SG_REL_ GW_BDC_FD SG_ 2281701568 UWB_FL_Status4 1500;
BA_REL_ "GenSigTimeoutTime" BU_SG_REL_ L_UWB_BLE_MST_FD SG_ 2281701568 UWB_FL_Status4 1500;
BA_REL_ "GenSigTimeoutTime" BU_SG_REL_ GW_BDC_FD SG_ 2281701568 UWB_FL_Status5 1500;
BA_REL_ "GenSigTimeoutTime" BU_SG_REL_ L_UWB_BLE_MST_FD SG_ 2281701568 UWB_FL_Status5 1500;
BA_REL_ "GenSigTimeoutTime" BU_SG_REL_ GW_BDC_FD SG_ 2281701568 UWB_FL_Status6 1500;
BA_REL_ "GenSigTimeoutTime" BU_SG_REL_ L_UWB_BLE_MST_FD SG_ 2281701568 UWB_FL_Status6 1500;
BA_REL_ "GenSigTimeoutTime" BU_SG_REL_ GW_BDC_FD SG_ 2281701568 UWB_FL_Status7 1500;
BA_REL_ "GenSigTimeoutTime" BU_SG_REL_ L_UWB_BLE_MST_FD SG_ 2281701568 UWB_FL_Status7 1500;
BA_REL_ "GenSigTimeoutTime" BU_SG_REL_ GW_BDC_FD SG_ 2281701568 UWB_FL_Status8 1500;
BA_REL_ "GenSigTimeoutTime" BU_SG_REL_ L_UWB_BLE_MST_FD SG_ 2281701568 UWB_FL_Status8 1500;
BA_REL_ "GenSigTimeoutTime" BU_SG_REL_ GW_BDC_FD SG_ 2281701568 UWB_FL_Status9 1500;
BA_REL_ "GenSigTimeoutTime" BU_SG_REL_ L_UWB_BLE_MST_FD SG_ 2281701568 UWB_FL_Status9 1500;
BA_REL_ "GenSigTimeoutTime" BU_SG_REL_ GW_BDC_FD SG_ 2281701568 UWB_FL_Status10 1500;
BA_REL_ "GenSigTimeoutTime" BU_SG_REL_ L_UWB_BLE_MST_FD SG_ 2281701568 UWB_FL_Status10 1500;
BA_REL_ "GenSigTimeoutTime" BU_SG_REL_ GW_BDC_FD SG_ 2281701568 UWB_FL_Status11 1500;
BA_REL_ "GenSigTimeoutTime" BU_SG_REL_ L_UWB_BLE_MST_FD SG_ 2281701568 UWB_FL_Status11 1500;
BA_REL_ "GenSigTimeoutTime" BU_SG_REL_ GW_BDC_FD SG_ 2281701568 UWB_FL_Status12 1500;
BA_REL_ "GenSigTimeoutTime" BU_SG_REL_ L_UWB_BLE_MST_FD SG_ 2281701568 UWB_FL_Status12 1500;
BA_REL_ "GenSigTimeoutTime" BU_SG_REL_ GW_BDC_FD SG_ 2281701568 UWB_FL_Status13 1500;
BA_REL_ "GenSigTimeoutTime" BU_SG_REL_ L_UWB_BLE_MST_FD SG_ 2281701568 UWB_FL_Status13 1500;
BA_REL_ "GenSigTimeoutTime" BU_SG_REL_ GW_BDC_FD SG_ 2281701568 UWB_FL_Status14 1500;
BA_REL_ "GenSigTimeoutTime" BU_SG_REL_ L_UWB_BLE_MST_FD SG_ 2281701568 UWB_FL_Status14 1500;
BA_REL_ "GenSigTimeoutTime" BU_SG_REL_ GW_BDC_FD SG_ 2281701568 UWB_FL_Status15 1500;
BA_REL_ "GenSigTimeoutTime" BU_SG_REL_ L_UWB_BLE_MST_FD SG_ 2281701568 UWB_FL_Status15 1500;
BA_REL_ "GenSigTimeoutTime" BU_SG_REL_ GW_BDC_FD SG_ 2281701568 UWB_FL_Status16 1500;
BA_REL_ "GenSigTimeoutTime" BU_SG_REL_ L_UWB_BLE_MST_FD SG_ 2281701568 UWB_FL_Status16 1500;
BA_REL_ "GenSigTimeoutTime" BU_SG_REL_ L_UWB_BLE_MST_FD SG_ 2281701568 UWB_FL_HW_Ver_Major 1500;
BA_REL_ "GenSigTimeoutTime" BU_SG_REL_ L_UWB_BLE_MST_FD SG_ 2281701568 UWB_FL_HW_Ver_Minor 1500;
BA_REL_ "GenSigTimeoutTime" BU_SG_REL_ GW_BDC_FD SG_ 1418 UWB_BLE_Master_GST_Byte0 0;
BA_REL_ "GenSigTimeoutTime" BU_SG_REL_ GW_BDC_FD SG_ 1418 UWB_BLE_Master_GST_Byte2 0;
BA_REL_ "GenSigTimeoutTime" BU_SG_REL_ GW_BDC_FD SG_ 1418 UWB_BLE_Master_GST_Byte3 0;
BA_REL_ "GenSigTimeoutTime" BU_SG_REL_ GW_BDC_FD SG_ 1418 UWB_BLE_Master_GST_Byte4 0;
BA_REL_ "GenSigTimeoutTime" BU_SG_REL_ GW_BDC_FD SG_ 1418 UWB_BLE_Master_GST_Byte5 0;
BA_REL_ "GenSigTimeoutTime" BU_SG_REL_ GW_BDC_FD SG_ 1418 UWB_BLE_Master_GST_Byte6 0;
BA_REL_ "GenSigTimeoutTime" BU_SG_REL_ GW_BDC_FD SG_ 1418 UWB_BLE_Master_GST_Byte7 0;
BA_REL_ "GenSigTimeoutTime" BU_SG_REL_ GW_BDC_FD SG_ 1418 UWB_BLE_Master_GST_Byte1 0;
BA_REL_ "GenSigTimeoutTime" BU_SG_REL_ L_UWB_BLE_MST_FD SG_ 992 Trunk_TrnkTlgtSwSta_Copy_0 1500;
BA_REL_ "GenSigTimeoutTime" BU_SG_REL_ L_UWB_BLE_MST_FD SG_ 992 DriveTypeOption_Copy_0 1500;
VAL_ 2281701552 L_UWB_BLE_SLV_FD_Crc20Val 0 "0x0x0~0xFFFF:CRCValue" 65535 "0x0x0~0xFFFF:CRCValue" ;
VAL_ 2281701552 SLV_BLE_Passive_ADV_State 0 "AdvertisingOff" 1 "AdvertisingOn" ;
VAL_ 2281701552 SLV_BLE_NewDeviceConnetStatus 0 "Default" 1 "Connected" 2 "Disconnected" 3 "Invalid" ;
VAL_ 2281701552 SLV_BLE_PairingResult 0 "Default" 1 "BLE_Pairing_Start" 2 "BLE_Pairing_Complete" 3 "BLE_Pairing_Fail" ;
VAL_ 2281701552 L_UWB_BLE_SLV_FD_AlvCnt20Val 0 "0x0x0~0xFF:AlvCntValue" 255 "0x0x0~0xFF:AlvCntValue" ;
VAL_ 2281701552 SLV_BLE_DK_ID1 0 "Default" 1 "DK#1" 2 "DK#2" 3 "DK#3" 4 "DK#4" 5 "DK#5" 6 "DK#6" 7 "DK#7" 8 "DK#8" 9 "DK#9" 10 "DK#10" 11 "DK#11" 12 "DK#12" 13 "DK#13" 14 "DK#14" 15 "DK#15" 16 "DK#16" 17 "DK#NEW" 18 "0x12~0xFE:RESERVED" 254 "0x12~0xFE:RESERVED" 255 "Invalid" ;
VAL_ 2281701552 SLV_BLE_DK_ID2 0 "Default" 1 "DK#1" 2 "DK#2" 3 "DK#3" 4 "DK#4" 5 "DK#5" 6 "DK#6" 7 "DK#7" 8 "DK#8" 9 "DK#9" 10 "DK#10" 11 "DK#11" 12 "DK#12" 13 "DK#13" 14 "DK#14" 15 "DK#15" 16 "DK#16" 17 "DK#NEW" 18 "0x12~0xFE:RESERVED" 254 "0x12~0xFE:RESERVED" 255 "Invalid" ;
VAL_ 2281701552 SLV_BLE_DK_ID3 0 "Default" 1 "DK#1" 2 "DK#2" 3 "DK#3" 4 "DK#4" 5 "DK#5" 6 "DK#6" 7 "DK#7" 8 "DK#8" 9 "DK#9" 10 "DK#10" 11 "DK#11" 12 "DK#12" 13 "DK#13" 14 "DK#14" 15 "DK#15" 16 "DK#16" 17 "DK#NEW" 18 "0x12~0xFE:RESERVED" 254 "0x12~0xFE:RESERVED" 255 "Invalid" ;
VAL_ 2281701552 SLV_BLE_DK_ID4 0 "Default" 1 "DK#1" 2 "DK#2" 3 "DK#3" 4 "DK#4" 5 "DK#5" 6 "DK#6" 7 "DK#7" 8 "DK#8" 9 "DK#9" 10 "DK#10" 11 "DK#11" 12 "DK#12" 13 "DK#13" 14 "DK#14" 15 "DK#15" 16 "DK#16" 17 "DK#NEW" 18 "0x12~0xFE:RESERVED" 254 "0x12~0xFE:RESERVED" 255 "Invalid" ;
VAL_ 2525339905 L_UWB_FL_FD_Crc5Val 0 "0x0x0~0xFFFF:CRCValue" 65535 "0x0x0~0xFFFF:CRCValue" ;
VAL_ 2525339905 L_UWB_FL_FD_AlvCnt5Val 0 "0x0x0~0xFF:AlvCntValue" 255 "0x0x0~0xFF:AlvCntValue" ;
VAL_ 2281701536 L_UWB_BLE_MST_FD_Crc20Val 0 "0x0x0~0xFFFF:CRCValue" 65535 "0x0x0~0xFFFF:CRCValue" ;
VAL_ 2281701536 MST_BLE_OP_ADV_State 0 "AdvertisingOff" 1 "AdvertisingOn" ;
VAL_ 2281701536 MST_BLE_Passive_ADV_State 0 "AdvertisingOff" 1 "AdvertisingOn" ;
VAL_ 2281701536 MST_BLE_NewDeviceConnetStatus 0 "Default" 1 "Connected" 2 "Disconnected" 3 "Invalid" ;
VAL_ 2281701536 MST_BLE_PairingResult 0 "Default" 1 "BLE_Pairing_Start" 2 "BLE_Pairing_Complete" 3 "BLE_Pairing_Fail" ;
VAL_ 2281701536 L_UWB_BLE_MST_FD_AlvCnt20Val 0 "0x0x0~0xFF:AlvCntValue" 255 "0x0x0~0xFF:AlvCntValue" ;
VAL_ 2281701536 MST_BLE_DK_ID1 0 "Default" 1 "DK#1" 2 "DK#2" 3 "DK#3" 4 "DK#4" 5 "DK#5" 6 "DK#6" 7 "DK#7" 8 "DK#8" 9 "DK#9" 10 "DK#10" 11 "DK#11" 12 "DK#12" 13 "DK#13" 14 "DK#14" 15 "DK#15" 16 "DK#16" 17 "DK#NEW" 18 "0x12~0xFE:RESERVED" 254 "0x12~0xFE:RESERVED" 255 "Invalid" ;
VAL_ 2281701536 MST_BLE_DK_ID2 0 "Default" 1 "DK#1" 2 "DK#2" 3 "DK#3" 4 "DK#4" 5 "DK#5" 6 "DK#6" 7 "DK#7" 8 "DK#8" 9 "DK#9" 10 "DK#10" 11 "DK#11" 12 "DK#12" 13 "DK#13" 14 "DK#14" 15 "DK#15" 16 "DK#16" 17 "DK#NEW" 18 "0x12~0xFE:RESERVED" 254 "0x12~0xFE:RESERVED" 255 "Invalid" ;
VAL_ 2281701536 MST_BLE_DK_ID3 0 "Default" 1 "DK#1" 2 "DK#2" 3 "DK#3" 4 "DK#4" 5 "DK#5" 6 "DK#6" 7 "DK#7" 8 "DK#8" 9 "DK#9" 10 "DK#10" 11 "DK#11" 12 "DK#12" 13 "DK#13" 14 "DK#14" 15 "DK#15" 16 "DK#16" 17 "DK#NEW" 18 "0x12~0xFE:RESERVED" 254 "0x12~0xFE:RESERVED" 255 "Invalid" ;
VAL_ 2281701536 MST_BLE_DK_ID4 0 "Default" 1 "DK#1" 2 "DK#2" 3 "DK#3" 4 "DK#4" 5 "DK#5" 6 "DK#6" 7 "DK#7" 8 "DK#8" 9 "DK#9" 10 "DK#10" 11 "DK#11" 12 "DK#12" 13 "DK#13" 14 "DK#14" 15 "DK#15" 16 "DK#16" 17 "DK#NEW" 18 "0x12~0xFE:RESERVED" 254 "0x12~0xFE:RESERVED" 255 "Invalid" ;
VAL_ 426 CLU_Crc1Val 0 "0x0x0~0xFFFF:CRCValue" 65535 "0x0x0~0xFFFF:CRCValue" ;
VAL_ 426 CLU_FuelSenderRstReq 0 "Default" 1 "Initialization" 2 "RESERVED" 3 "Invalid" ;
VAL_ 426 CLU_AlvCnt1Val 0 "0x0x0~0xFF:AlvCntValue" 255 "0x0x0~0xFF:AlvCntValue" ;
VAL_ 426 CLU_DtntOutSta 0 "Detent Off" 1 "Detent On" 2 "Not used" 3 "Error Indicator" ;
VAL_ 426 CLU_SpdUnitTyp 0 "km/h" 1 "MPH" 2 "Not used" 3 "Error Indicator" ;
VAL_ 426 CLU_DisSpdDcmlVal 0 "0" 1 "0.125" 2 "0.250" 3 "0.375" ;
VAL_ 426 CLU_SWRCCrsMainSwSta 0 "Off" 1 "Key On" 2 "Reserved" 3 "Invalid" ;
VAL_ 426 CLU_SWRCCrsSwSta 0 "Idle Position" 1 "Plus" 2 "Minus" 3 "Headway" 4 "Cancel/Pause" 5 "Reserved" 6 "Reserved" 7 "Reserved" ;
VAL_ 426 CLU_SWRCLFASwSta 0 "Off" 1 "Key On" 2 "Reserved" 3 "Invalid" ;
VAL_ 426 CLU_SWRCSldMainSwSta 0 "Off" 1 "Key On" 2 "Reserved" 3 "Invalid" ;
VAL_ 426 CLU_RhstaLvlSta 0 "Reserved" 1 "Step 1" 2 "Step 2" 3 "Step 3" 4 "Step 4" 5 "Step 5" 6 "Step 6" 7 "Step 7" 8 "Step 8" 9 "Step 9" 10 "Step 10" 11 "Step 11" 12 "Step 12" 13 "Step 13" 14 "Step 14" 15 "Step 15" 16 "Step 16" 17 "Step 17" 18 "Step 18" 19 "Step 19" 20 "Step 20 (Reset Value)" 21 "Step 21 (Detent)" ;
VAL_ 426 CLU_DisSpdVal 1023 "Error" ;
VAL_ 426 CLU_OKSwSta 0 "Off" 1 "Key On" 2 "Reserved" 3 "Invalid" ;
VAL_ 426 CLU_DisSpdVal_KPH 511 "Error" ;
VAL_ 426 CLU_PwrAutoOffResetReq_HCU 0 "Default" 1 "Reset Request" 2 "Reserved" 3 "Invalid" ;
VAL_ 426 CLU_CUSTOMSta_NEW 0 "Default" 1 "MY DRIVE MODE(CUSTOM)" 2 "SMART(CUSTOM)" 3 "BABY(CUSTOM)" 4 "RETRO(CUSTOM)" 5 "SNOW(CUSTOM)-Not Terrain" 6 "COMFORT(REAR)(CUSTOM)" 7 "" 8 "" 9 "" 10 "" 11 "" 12 "" 13 "" 14 "Off(CUSTOM)" 15 "Invalid" ;
VAL_ 426 CLU_AutoBrightSta 0 "Reserved (Not Used)" 1 "0x01~0xC8:Bright State (1~200 Step)" 200 "0x01~0xC8:Bright State (1~200 Step)" ;
VAL_ 426 CLU_NotMinModeBrightSta 0 "RESERVED" 1 "0x01~0xC8:CLU Bright State (1~200 Step)" 200 "0x01~0xC8:CLU Bright State (1~200 Step)" 201 "RESERVED" 202 "RESERVED" 203 "RESERVED" 204 "RESERVED" 205 "RESERVED" 206 "RESERVED" 207 "RESERVED" 208 "RESERVED" 209 "RESERVED" 210 "RESERVED" 211 "RESERVED" 212 "RESERVED" 213 "RESERVED" 214 "RESERVED" 215 "RESERVED" 216 "RESERVED" 217 "RESERVED" 218 "RESERVED" 219 "RESERVED" 220 "RESERVED" 221 "RESERVED" 222 "RESERVED" 223 "RESERVED" 224 "RESERVED" 225 "RESERVED" 226 "RESERVED" 227 "RESERVED" 228 "RESERVED" 229 "RESERVED" 230 "RESERVED" 231 "RESERVED" 232 "RESERVED" 233 "RESERVED" 234 "RESERVED" 235 "RESERVED" 236 "RESERVED" 237 "RESERVED" 238 "RESERVED" 239 "RESERVED" 240 "RESERVED" 241 "RESERVED" 242 "RESERVED" 243 "RESERVED" 244 "RESERVED" 245 "RESERVED" 246 "RESERVED" 247 "RESERVED" 248 "RESERVED" 249 "RESERVED" 250 "RESERVED" 251 "RESERVED" 252 "RESERVED" 253 "RESERVED" 254 "RESERVED" 255 "RESERVED" ;
VAL_ 426 CLU_FuelSenderResistVal 0 "Default(no data)" 1 "0x1~0x1FFE:0.1~819.0(е╪)" 8190 "0x1~0x1FFE:0.1~819.0(е╪)" 8191 "Invalid" ;
VAL_ 2281701537 L_UWB_BLE_MST_FD_Crc21Val 0 "0x0x0~0xFFFF:CRCValue" 65535 "0x0x0~0xFFFF:CRCValue" ;
VAL_ 2281701537 MST_UWB_DK_LocalizationStat 0 "Default" 1 "Localizing" 2 "Suspended" 3 "Invalid" ;
VAL_ 2281701537 L_UWB_BLE_MST_FD_AlvCnt21Val 0 "0x0x0~0xFF:AlvCntValue" 255 "0x0x0~0xFF:AlvCntValue" ;
VAL_ 2281701537 UWB_Applied_Info 0 "0x0x0~0xFFFF:flag value" 65535 "0x0x0~0xFFFF:flag value" ;
VAL_ 2281701537 MST_SW_UWB_2_Ver_Major 0 "0x0x00~0xFF:value(Hex)" 255 "0x0x00~0xFF:value(Hex)" ;
VAL_ 2281701537 MST_SW_UWB_2_Ver_Minor 0 "0x0x00~0xFF:value(Hex)" 255 "0x0x00~0xFF:value(Hex)" ;
VAL_ 2281701537 MST_UWB_Status1 0 "Default" 1 "No_Ranging" 2 "URSK_Stored" 3 "UWB_Session_Setup" 4 "Ranging_Start(Not_In_Sync)" 5 "Ranging_Start(In_Sync)" 6 "Ranging_Stop(Max_Signal_Missed)" 7 "Fob_Ranging" 8 "RESERVED" 9 "RESERVED" 10 "RESERVED" 11 "RESERVED" 12 "RESERVED" 13 "RESERVED" 14 "RESERVED" 15 "Invalid" ;
VAL_ 2281701537 MST_UWB_Status2 0 "Default" 1 "No_Ranging" 2 "URSK_Stored" 3 "UWB_Session_Setup" 4 "Ranging_Start(Not_In_Sync)" 5 "Ranging_Start(In_Sync)" 6 "Ranging_Stop(Max_Signal_Missed)" 7 "Fob_Ranging" 8 "RESERVED" 9 "RESERVED" 10 "RESERVED" 11 "RESERVED" 12 "RESERVED" 13 "RESERVED" 14 "RESERVED" 15 "Invalid" ;
VAL_ 2281701537 MST_UWB_Status3 0 "Default" 1 "No_Ranging" 2 "URSK_Stored" 3 "UWB_Session_Setup" 4 "Ranging_Start(Not_In_Sync)" 5 "Ranging_Start(In_Sync)" 6 "Ranging_Stop(Max_Signal_Missed)" 7 "Fob_Ranging" 8 "RESERVED" 9 "RESERVED" 10 "RESERVED" 11 "RESERVED" 12 "RESERVED" 13 "RESERVED" 14 "RESERVED" 15 "Invalid" ;
VAL_ 2281701537 MST_UWB_Status4 0 "Default" 1 "No_Ranging" 2 "URSK_Stored" 3 "UWB_Session_Setup" 4 "Ranging_Start(Not_In_Sync)" 5 "Ranging_Start(In_Sync)" 6 "Ranging_Stop(Max_Signal_Missed)" 7 "Fob_Ranging" 8 "RESERVED" 9 "RESERVED" 10 "RESERVED" 11 "RESERVED" 12 "RESERVED" 13 "RESERVED" 14 "RESERVED" 15 "Invalid" ;
VAL_ 2281701537 MST_UWB_Status5 0 "Default" 1 "No_Ranging" 2 "URSK_Stored" 3 "UWB_Session_Setup" 4 "Ranging_Start(Not_In_Sync)" 5 "Ranging_Start(In_Sync)" 6 "Ranging_Stop(Max_Signal_Missed)" 7 "Fob_Ranging" 8 "RESERVED" 9 "RESERVED" 10 "RESERVED" 11 "RESERVED" 12 "RESERVED" 13 "RESERVED" 14 "RESERVED" 15 "Invalid" ;
VAL_ 2281701537 MST_UWB_Status6 0 "Default" 1 "No_Ranging" 2 "URSK_Stored" 3 "UWB_Session_Setup" 4 "Ranging_Start(Not_In_Sync)" 5 "Ranging_Start(In_Sync)" 6 "Ranging_Stop(Max_Signal_Missed)" 7 "Fob_Ranging" 8 "RESERVED" 9 "RESERVED" 10 "RESERVED" 11 "RESERVED" 12 "RESERVED" 13 "RESERVED" 14 "RESERVED" 15 "Invalid" ;
VAL_ 2281701537 MST_UWB_Status7 0 "Default" 1 "No_Ranging" 2 "URSK_Stored" 3 "UWB_Session_Setup" 4 "Ranging_Start(Not_In_Sync)" 5 "Ranging_Start(In_Sync)" 6 "Ranging_Stop(Max_Signal_Missed)" 7 "Fob_Ranging" 8 "RESERVED" 9 "RESERVED" 10 "RESERVED" 11 "RESERVED" 12 "RESERVED" 13 "RESERVED" 14 "RESERVED" 15 "Invalid" ;
VAL_ 2281701537 MST_UWB_Status8 0 "Default" 1 "No_Ranging" 2 "URSK_Stored" 3 "UWB_Session_Setup" 4 "Ranging_Start(Not_In_Sync)" 5 "Ranging_Start(In_Sync)" 6 "Ranging_Stop(Max_Signal_Missed)" 7 "Fob_Ranging" 8 "RESERVED" 9 "RESERVED" 10 "RESERVED" 11 "RESERVED" 12 "RESERVED" 13 "RESERVED" 14 "RESERVED" 15 "Invalid" ;
VAL_ 2281701537 MST_UWB_Status9 0 "Default" 1 "No_Ranging" 2 "URSK_Stored" 3 "UWB_Session_Setup" 4 "Ranging_Start(Not_In_Sync)" 5 "Ranging_Start(In_Sync)" 6 "Ranging_Stop(Max_Signal_Missed)" 7 "Fob_Ranging" 8 "RESERVED" 9 "RESERVED" 10 "RESERVED" 11 "RESERVED" 12 "RESERVED" 13 "RESERVED" 14 "RESERVED" 15 "Invalid" ;
VAL_ 2281701537 MST_UWB_Status10 0 "Default" 1 "No_Ranging" 2 "URSK_Stored" 3 "UWB_Session_Setup" 4 "Ranging_Start(Not_In_Sync)" 5 "Ranging_Start(In_Sync)" 6 "Ranging_Stop(Max_Signal_Missed)" 7 "Fob_Ranging" 8 "RESERVED" 9 "RESERVED" 10 "RESERVED" 11 "RESERVED" 12 "RESERVED" 13 "RESERVED" 14 "RESERVED" 15 "Invalid" ;
VAL_ 2281701537 MST_UWB_Status11 0 "Default" 1 "No_Ranging" 2 "URSK_Stored" 3 "UWB_Session_Setup" 4 "Ranging_Start(Not_In_Sync)" 5 "Ranging_Start(In_Sync)" 6 "Ranging_Stop(Max_Signal_Missed)" 7 "Fob_Ranging" 8 "RESERVED" 9 "RESERVED" 10 "RESERVED" 11 "RESERVED" 12 "RESERVED" 13 "RESERVED" 14 "RESERVED" 15 "Invalid" ;
VAL_ 2281701537 MST_UWB_Status12 0 "Default" 1 "No_Ranging" 2 "URSK_Stored" 3 "UWB_Session_Setup" 4 "Ranging_Start(Not_In_Sync)" 5 "Ranging_Start(In_Sync)" 6 "Ranging_Stop(Max_Signal_Missed)" 7 "Fob_Ranging" 8 "RESERVED" 9 "RESERVED" 10 "RESERVED" 11 "RESERVED" 12 "RESERVED" 13 "RESERVED" 14 "RESERVED" 15 "Invalid" ;
VAL_ 2281701537 MST_UWB_Status13 0 "Default" 1 "No_Ranging" 2 "URSK_Stored" 3 "UWB_Session_Setup" 4 "Ranging_Start(Not_In_Sync)" 5 "Ranging_Start(In_Sync)" 6 "Ranging_Stop(Max_Signal_Missed)" 7 "Fob_Ranging" 8 "RESERVED" 9 "RESERVED" 10 "RESERVED" 11 "RESERVED" 12 "RESERVED" 13 "RESERVED" 14 "RESERVED" 15 "Invalid" ;
VAL_ 2281701537 MST_UWB_Status14 0 "Default" 1 "No_Ranging" 2 "URSK_Stored" 3 "UWB_Session_Setup" 4 "Ranging_Start(Not_In_Sync)" 5 "Ranging_Start(In_Sync)" 6 "Ranging_Stop(Max_Signal_Missed)" 7 "Fob_Ranging" 8 "RESERVED" 9 "RESERVED" 10 "RESERVED" 11 "RESERVED" 12 "RESERVED" 13 "RESERVED" 14 "RESERVED" 15 "Invalid" ;
VAL_ 2281701537 MST_UWB_Status15 0 "Default" 1 "No_Ranging" 2 "URSK_Stored" 3 "UWB_Session_Setup" 4 "Ranging_Start(Not_In_Sync)" 5 "Ranging_Start(In_Sync)" 6 "Ranging_Stop(Max_Signal_Missed)" 7 "Fob_Ranging" 8 "RESERVED" 9 "RESERVED" 10 "RESERVED" 11 "RESERVED" 12 "RESERVED" 13 "RESERVED" 14 "RESERVED" 15 "Invalid" ;
VAL_ 2281701537 MST_UWB_Status16 0 "Default" 1 "No_Ranging" 2 "URSK_Stored" 3 "UWB_Session_Setup" 4 "Ranging_Start(Not_In_Sync)" 5 "Ranging_Start(In_Sync)" 6 "Ranging_Stop(Max_Signal_Missed)" 7 "Fob_Ranging" 8 "RESERVED" 9 "RESERVED" 10 "RESERVED" 11 "RESERVED" 12 "RESERVED" 13 "RESERVED" 14 "RESERVED" 15 "Invalid" ;
VAL_ 2281701584 L_UWB_FR_FD_Crc10Val 0 "0x0x0~0xFFFF:CRCValue" 65535 "0x0x0~0xFFFF:CRCValue" ;
VAL_ 2281701584 L_UWB_FR_FD_AlvCnt10Val 0 "0x0x0~0xFF:AlvCntValue" 255 "0x0x0~0xFF:AlvCntValue" ;
VAL_ 2281701584 UWB_FR_Status1 0 "Default" 1 "No_Ranging" 2 "URSK_Stored" 3 "UWB_Session_Setup" 4 "Ranging_Start(Not_In_Sync)" 5 "Ranging_Start(In_Sync)" 6 "Ranging_Stop(Max_Signal_Missed)" 7 "Fob_Ranging" 8 "RESERVED" 9 "RESERVED" 10 "RESERVED" 11 "RESERVED" 12 "RESERVED" 13 "RESERVED" 14 "RESERVED" 15 "Invalid" ;
VAL_ 2281701584 UWB_FR_Status2 0 "Default" 1 "No_Ranging" 2 "URSK_Stored" 3 "UWB_Session_Setup" 4 "Ranging_Start(Not_In_Sync)" 5 "Ranging_Start(In_Sync)" 6 "Ranging_Stop(Max_Signal_Missed)" 7 "Fob_Ranging" 8 "RESERVED" 9 "RESERVED" 10 "RESERVED" 11 "RESERVED" 12 "RESERVED" 13 "RESERVED" 14 "RESERVED" 15 "Invalid" ;
VAL_ 2281701584 UWB_FR_Status3 0 "Default" 1 "No_Ranging" 2 "URSK_Stored" 3 "UWB_Session_Setup" 4 "Ranging_Start(Not_In_Sync)" 5 "Ranging_Start(In_Sync)" 6 "Ranging_Stop(Max_Signal_Missed)" 7 "Fob_Ranging" 8 "RESERVED" 9 "RESERVED" 10 "RESERVED" 11 "RESERVED" 12 "RESERVED" 13 "RESERVED" 14 "RESERVED" 15 "Invalid" ;
VAL_ 2281701584 UWB_FR_Status4 0 "Default" 1 "No_Ranging" 2 "URSK_Stored" 3 "UWB_Session_Setup" 4 "Ranging_Start(Not_In_Sync)" 5 "Ranging_Start(In_Sync)" 6 "Ranging_Stop(Max_Signal_Missed)" 7 "Fob_Ranging" 8 "RESERVED" 9 "RESERVED" 10 "RESERVED" 11 "RESERVED" 12 "RESERVED" 13 "RESERVED" 14 "RESERVED" 15 "Invalid" ;
VAL_ 2281701584 UWB_FR_Status5 0 "Default" 1 "No_Ranging" 2 "URSK_Stored" 3 "UWB_Session_Setup" 4 "Ranging_Start(Not_In_Sync)" 5 "Ranging_Start(In_Sync)" 6 "Ranging_Stop(Max_Signal_Missed)" 7 "Fob_Ranging" 8 "RESERVED" 9 "RESERVED" 10 "RESERVED" 11 "RESERVED" 12 "RESERVED" 13 "RESERVED" 14 "RESERVED" 15 "Invalid" ;
VAL_ 2281701584 UWB_FR_Status6 0 "Default" 1 "No_Ranging" 2 "URSK_Stored" 3 "UWB_Session_Setup" 4 "Ranging_Start(Not_In_Sync)" 5 "Ranging_Start(In_Sync)" 6 "Ranging_Stop(Max_Signal_Missed)" 7 "Fob_Ranging" 8 "RESERVED" 9 "RESERVED" 10 "RESERVED" 11 "RESERVED" 12 "RESERVED" 13 "RESERVED" 14 "RESERVED" 15 "Invalid" ;
VAL_ 2281701584 UWB_FR_Status7 0 "Default" 1 "No_Ranging" 2 "URSK_Stored" 3 "UWB_Session_Setup" 4 "Ranging_Start(Not_In_Sync)" 5 "Ranging_Start(In_Sync)" 6 "Ranging_Stop(Max_Signal_Missed)" 7 "Fob_Ranging" 8 "RESERVED" 9 "RESERVED" 10 "RESERVED" 11 "RESERVED" 12 "RESERVED" 13 "RESERVED" 14 "RESERVED" 15 "Invalid" ;
VAL_ 2281701584 UWB_FR_Status8 0 "Default" 1 "No_Ranging" 2 "URSK_Stored" 3 "UWB_Session_Setup" 4 "Ranging_Start(Not_In_Sync)" 5 "Ranging_Start(In_Sync)" 6 "Ranging_Stop(Max_Signal_Missed)" 7 "Fob_Ranging" 8 "RESERVED" 9 "RESERVED" 10 "RESERVED" 11 "RESERVED" 12 "RESERVED" 13 "RESERVED" 14 "RESERVED" 15 "Invalid" ;
VAL_ 2281701584 UWB_FR_Status9 0 "Default" 1 "No_Ranging" 2 "URSK_Stored" 3 "UWB_Session_Setup" 4 "Ranging_Start(Not_In_Sync)" 5 "Ranging_Start(In_Sync)" 6 "Ranging_Stop(Max_Signal_Missed)" 7 "Fob_Ranging" 8 "RESERVED" 9 "RESERVED" 10 "RESERVED" 11 "RESERVED" 12 "RESERVED" 13 "RESERVED" 14 "RESERVED" 15 "Invalid" ;
VAL_ 2281701584 UWB_FR_Status10 0 "Default" 1 "No_Ranging" 2 "URSK_Stored" 3 "UWB_Session_Setup" 4 "Ranging_Start(Not_In_Sync)" 5 "Ranging_Start(In_Sync)" 6 "Ranging_Stop(Max_Signal_Missed)" 7 "Fob_Ranging" 8 "RESERVED" 9 "RESERVED" 10 "RESERVED" 11 "RESERVED" 12 "RESERVED" 13 "RESERVED" 14 "RESERVED" 15 "Invalid" ;
VAL_ 2281701584 UWB_FR_Status11 0 "Default" 1 "No_Ranging" 2 "URSK_Stored" 3 "UWB_Session_Setup" 4 "Ranging_Start(Not_In_Sync)" 5 "Ranging_Start(In_Sync)" 6 "Ranging_Stop(Max_Signal_Missed)" 7 "Fob_Ranging" 8 "RESERVED" 9 "RESERVED" 10 "RESERVED" 11 "RESERVED" 12 "RESERVED" 13 "RESERVED" 14 "RESERVED" 15 "Invalid" ;
VAL_ 2281701584 UWB_FR_Status12 0 "Default" 1 "No_Ranging" 2 "URSK_Stored" 3 "UWB_Session_Setup" 4 "Ranging_Start(Not_In_Sync)" 5 "Ranging_Start(In_Sync)" 6 "Ranging_Stop(Max_Signal_Missed)" 7 "Fob_Ranging" 8 "RESERVED" 9 "RESERVED" 10 "RESERVED" 11 "RESERVED" 12 "RESERVED" 13 "RESERVED" 14 "RESERVED" 15 "Invalid" ;
VAL_ 2281701584 UWB_FR_Status13 0 "Default" 1 "No_Ranging" 2 "URSK_Stored" 3 "UWB_Session_Setup" 4 "Ranging_Start(Not_In_Sync)" 5 "Ranging_Start(In_Sync)" 6 "Ranging_Stop(Max_Signal_Missed)" 7 "Fob_Ranging" 8 "RESERVED" 9 "RESERVED" 10 "RESERVED" 11 "RESERVED" 12 "RESERVED" 13 "RESERVED" 14 "RESERVED" 15 "Invalid" ;
VAL_ 2281701584 UWB_FR_Status14 0 "Default" 1 "No_Ranging" 2 "URSK_Stored" 3 "UWB_Session_Setup" 4 "Ranging_Start(Not_In_Sync)" 5 "Ranging_Start(In_Sync)" 6 "Ranging_Stop(Max_Signal_Missed)" 7 "Fob_Ranging" 8 "RESERVED" 9 "RESERVED" 10 "RESERVED" 11 "RESERVED" 12 "RESERVED" 13 "RESERVED" 14 "RESERVED" 15 "Invalid" ;
VAL_ 2281701584 UWB_FR_Status15 0 "Default" 1 "No_Ranging" 2 "URSK_Stored" 3 "UWB_Session_Setup" 4 "Ranging_Start(Not_In_Sync)" 5 "Ranging_Start(In_Sync)" 6 "Ranging_Stop(Max_Signal_Missed)" 7 "Fob_Ranging" 8 "RESERVED" 9 "RESERVED" 10 "RESERVED" 11 "RESERVED" 12 "RESERVED" 13 "RESERVED" 14 "RESERVED" 15 "Invalid" ;
VAL_ 2281701584 UWB_FR_Status16 0 "Default" 1 "No_Ranging" 2 "URSK_Stored" 3 "UWB_Session_Setup" 4 "Ranging_Start(Not_In_Sync)" 5 "Ranging_Start(In_Sync)" 6 "Ranging_Stop(Max_Signal_Missed)" 7 "Fob_Ranging" 8 "RESERVED" 9 "RESERVED" 10 "RESERVED" 11 "RESERVED" 12 "RESERVED" 13 "RESERVED" 14 "RESERVED" 15 "Invalid" ;
VAL_ 2348810256 L_TPMS_FD_Crc1Val 0 "0x0x0~0xFFFF:CRCValue" 65535 "0x0x0~0xFFFF:CRCValue" ;
VAL_ 2348810256 L_TPMS_FD_AlvCnt1Val 0 "0x0x0~0xFF:AlvCntValue" 255 "0x0x0~0xFF:AlvCntValue" ;
VAL_ 2348810256 TPMS_SensorRssiVal 0 "0x0x0~0xFF:Sensor RSSI Value" 255 "0x0x0~0xFF:Sensor RSSI Value" ;
VAL_ 2348810257 L_TPMS_FD_Crc2Val 0 "0x0x0~0xFFFF:CRCValue" 65535 "0x0x0~0xFFFF:CRCValue" ;
VAL_ 2348810257 L_TPMS_FD_AlvCnt2Val 0 "0x0x0~0xFF:AlvCntValue" 255 "0x0x0~0xFF:AlvCntValue" ;
VAL_ 2348810257 TPMS_RficErrStatus 0 "Normal" 1 "Error" 2 "RESERVED" 3 "Error Indicator" ;
VAL_ 2348810257 TPMS_NoiseRssiVal 0 "0x0x0~0xFF:Noise RSSI Value" 255 "0x0x0~0xFF:Noise RSSI Value" ;
VAL_ 2533736449 L_UWB_TRNK_FD_Crc4Val 0 "0x0x0~0xFFFF:CRCValue" 65535 "0x0x0~0xFFFF:CRCValue" ;
VAL_ 2533736449 L_UWB_TRNK_FD_AlvCnt4Val 0 "0x0x0~0xFF:AlvCntValue" 255 "0x0x0~0xFF:AlvCntValue" ;
VAL_ 2529538049 L_UWB_RL_FD_Crc4Val 0 "0x0x0~0xFFFF:CRCValue" 65535 "0x0x0~0xFFFF:CRCValue" ;
VAL_ 2529538049 L_UWB_RL_FD_AlvCnt4Val 0 "0x0x0~0xFF:AlvCntValue" 255 "0x0x0~0xFF:AlvCntValue" ;
VAL_ 2281701568 L_UWB_FL_FD_Crc10Val 0 "0x0x0~0xFFFF:CRCValue" 65535 "0x0x0~0xFFFF:CRCValue" ;
VAL_ 2281701568 L_UWB_FL_FD_AlvCnt10Val 0 "0x0x0~0xFF:AlvCntValue" 255 "0x0x0~0xFF:AlvCntValue" ;
VAL_ 2281701568 UWB_FL_Status1 0 "Default" 1 "No_Ranging" 2 "URSK_Stored" 3 "UWB_Session_Setup" 4 "Ranging_Start(Not_In_Sync)" 5 "Ranging_Start(In_Sync)" 6 "Ranging_Stop(Max_Signal_Missed)" 7 "Fob_Ranging" 8 "RESERVED" 9 "RESERVED" 10 "RESERVED" 11 "RESERVED" 12 "RESERVED" 13 "RESERVED" 14 "RESERVED" 15 "Invalid" ;
VAL_ 2281701568 UWB_FL_Status2 0 "Default" 1 "No_Ranging" 2 "URSK_Stored" 3 "UWB_Session_Setup" 4 "Ranging_Start(Not_In_Sync)" 5 "Ranging_Start(In_Sync)" 6 "Ranging_Stop(Max_Signal_Missed)" 7 "Fob_Ranging" 8 "RESERVED" 9 "RESERVED" 10 "RESERVED" 11 "RESERVED" 12 "RESERVED" 13 "RESERVED" 14 "RESERVED" 15 "Invalid" ;
VAL_ 2281701568 UWB_FL_Status3 0 "Default" 1 "No_Ranging" 2 "URSK_Stored" 3 "UWB_Session_Setup" 4 "Ranging_Start(Not_In_Sync)" 5 "Ranging_Start(In_Sync)" 6 "Ranging_Stop(Max_Signal_Missed)" 7 "Fob_Ranging" 8 "RESERVED" 9 "RESERVED" 10 "RESERVED" 11 "RESERVED" 12 "RESERVED" 13 "RESERVED" 14 "RESERVED" 15 "Invalid" ;
VAL_ 2281701568 UWB_FL_Status4 0 "Default" 1 "No_Ranging" 2 "URSK_Stored" 3 "UWB_Session_Setup" 4 "Ranging_Start(Not_In_Sync)" 5 "Ranging_Start(In_Sync)" 6 "Ranging_Stop(Max_Signal_Missed)" 7 "Fob_Ranging" 8 "RESERVED" 9 "RESERVED" 10 "RESERVED" 11 "RESERVED" 12 "RESERVED" 13 "RESERVED" 14 "RESERVED" 15 "Invalid" ;
VAL_ 2281701568 UWB_FL_Status5 0 "Default" 1 "No_Ranging" 2 "URSK_Stored" 3 "UWB_Session_Setup" 4 "Ranging_Start(Not_In_Sync)" 5 "Ranging_Start(In_Sync)" 6 "Ranging_Stop(Max_Signal_Missed)" 7 "Fob_Ranging" 8 "RESERVED" 9 "RESERVED" 10 "RESERVED" 11 "RESERVED" 12 "RESERVED" 13 "RESERVED" 14 "RESERVED" 15 "Invalid" ;
VAL_ 2281701568 UWB_FL_Status6 0 "Default" 1 "No_Ranging" 2 "URSK_Stored" 3 "UWB_Session_Setup" 4 "Ranging_Start(Not_In_Sync)" 5 "Ranging_Start(In_Sync)" 6 "Ranging_Stop(Max_Signal_Missed)" 7 "Fob_Ranging" 8 "RESERVED" 9 "RESERVED" 10 "RESERVED" 11 "RESERVED" 12 "RESERVED" 13 "RESERVED" 14 "RESERVED" 15 "Invalid" ;
VAL_ 2281701568 UWB_FL_Status7 0 "Default" 1 "No_Ranging" 2 "URSK_Stored" 3 "UWB_Session_Setup" 4 "Ranging_Start(Not_In_Sync)" 5 "Ranging_Start(In_Sync)" 6 "Ranging_Stop(Max_Signal_Missed)" 7 "Fob_Ranging" 8 "RESERVED" 9 "RESERVED" 10 "RESERVED" 11 "RESERVED" 12 "RESERVED" 13 "RESERVED" 14 "RESERVED" 15 "Invalid" ;
VAL_ 2281701568 UWB_FL_Status8 0 "Default" 1 "No_Ranging" 2 "URSK_Stored" 3 "UWB_Session_Setup" 4 "Ranging_Start(Not_In_Sync)" 5 "Ranging_Start(In_Sync)" 6 "Ranging_Stop(Max_Signal_Missed)" 7 "Fob_Ranging" 8 "RESERVED" 9 "RESERVED" 10 "RESERVED" 11 "RESERVED" 12 "RESERVED" 13 "RESERVED" 14 "RESERVED" 15 "Invalid" ;
VAL_ 2281701568 UWB_FL_Status9 0 "Default" 1 "No_Ranging" 2 "URSK_Stored" 3 "UWB_Session_Setup" 4 "Ranging_Start(Not_In_Sync)" 5 "Ranging_Start(In_Sync)" 6 "Ranging_Stop(Max_Signal_Missed)" 7 "Fob_Ranging" 8 "RESERVED" 9 "RESERVED" 10 "RESERVED" 11 "RESERVED" 12 "RESERVED" 13 "RESERVED" 14 "RESERVED" 15 "Invalid" ;
VAL_ 2281701568 UWB_FL_Status10 0 "Default" 1 "No_Ranging" 2 "URSK_Stored" 3 "UWB_Session_Setup" 4 "Ranging_Start(Not_In_Sync)" 5 "Ranging_Start(In_Sync)" 6 "Ranging_Stop(Max_Signal_Missed)" 7 "Fob_Ranging" 8 "RESERVED" 9 "RESERVED" 10 "RESERVED" 11 "RESERVED" 12 "RESERVED" 13 "RESERVED" 14 "RESERVED" 15 "Invalid" ;
VAL_ 2281701568 UWB_FL_Status11 0 "Default" 1 "No_Ranging" 2 "URSK_Stored" 3 "UWB_Session_Setup" 4 "Ranging_Start(Not_In_Sync)" 5 "Ranging_Start(In_Sync)" 6 "Ranging_Stop(Max_Signal_Missed)" 7 "Fob_Ranging" 8 "RESERVED" 9 "RESERVED" 10 "RESERVED" 11 "RESERVED" 12 "RESERVED" 13 "RESERVED" 14 "RESERVED" 15 "Invalid" ;
VAL_ 2281701568 UWB_FL_Status12 0 "Default" 1 "No_Ranging" 2 "URSK_Stored" 3 "UWB_Session_Setup" 4 "Ranging_Start(Not_In_Sync)" 5 "Ranging_Start(In_Sync)" 6 "Ranging_Stop(Max_Signal_Missed)" 7 "Fob_Ranging" 8 "RESERVED" 9 "RESERVED" 10 "RESERVED" 11 "RESERVED" 12 "RESERVED" 13 "RESERVED" 14 "RESERVED" 15 "Invalid" ;
VAL_ 2281701568 UWB_FL_Status13 0 "Default" 1 "No_Ranging" 2 "URSK_Stored" 3 "UWB_Session_Setup" 4 "Ranging_Start(Not_In_Sync)" 5 "Ranging_Start(In_Sync)" 6 "Ranging_Stop(Max_Signal_Missed)" 7 "Fob_Ranging" 8 "RESERVED" 9 "RESERVED" 10 "RESERVED" 11 "RESERVED" 12 "RESERVED" 13 "RESERVED" 14 "RESERVED" 15 "Invalid" ;
VAL_ 2281701568 UWB_FL_Status14 0 "Default" 1 "No_Ranging" 2 "URSK_Stored" 3 "UWB_Session_Setup" 4 "Ranging_Start(Not_In_Sync)" 5 "Ranging_Start(In_Sync)" 6 "Ranging_Stop(Max_Signal_Missed)" 7 "Fob_Ranging" 8 "RESERVED" 9 "RESERVED" 10 "RESERVED" 11 "RESERVED" 12 "RESERVED" 13 "RESERVED" 14 "RESERVED" 15 "Invalid" ;
VAL_ 2281701568 UWB_FL_Status15 0 "Default" 1 "No_Ranging" 2 "URSK_Stored" 3 "UWB_Session_Setup" 4 "Ranging_Start(Not_In_Sync)" 5 "Ranging_Start(In_Sync)" 6 "Ranging_Stop(Max_Signal_Missed)" 7 "Fob_Ranging" 8 "RESERVED" 9 "RESERVED" 10 "RESERVED" 11 "RESERVED" 12 "RESERVED" 13 "RESERVED" 14 "RESERVED" 15 "Invalid" ;
VAL_ 2281701568 UWB_FL_Status16 0 "Default" 1 "No_Ranging" 2 "URSK_Stored" 3 "UWB_Session_Setup" 4 "Ranging_Start(Not_In_Sync)" 5 "Ranging_Start(In_Sync)" 6 "Ranging_Stop(Max_Signal_Missed)" 7 "Fob_Ranging" 8 "RESERVED" 9 "RESERVED" 10 "RESERVED" 11 "RESERVED" 12 "RESERVED" 13 "RESERVED" 14 "RESERVED" 15 "Invalid" ;
VAL_ 992 PDC_FD_Crc1Val 0 "0x0x0~0xFFFF:CRCValue" 65535 "0x0x0~0xFFFF:CRCValue" ;
VAL_ 992 C_3rdRCSeatBeltSW_Copy_0 0 "Unbelted" 1 "Belted" ;
VAL_ 992 C_3rdRRSeatBeltSW_Copy_0 0 "Unbelted" 1 "Belted" ;
VAL_ 992 C_1stCTRSeatBeltSW_Copy_0 0 "Unbelted" 1 "Belted" ;
VAL_ 992 Warn_DrvStOccSta_Copy_0 0 "UnSeated" 1 "Seated" 2 "RESERVED" 3 "RESERVED" 4 "RESERVED" 5 "Fault 1 (Cable Cut-off)" 6 "Fault 2 (Cable Short)" 7 "Error Indicator" ;
VAL_ 992 DPDMat_HDPSpprtSWVer_Copy_0 0 "Requirement Spec Version" 1 "Requirement Spec Version" 2 "Requirement Spec Version" 3 "Requirement Spec Version" 4 "Requirement Spec Version" 5 "Requirement Spec Version" 6 "Requirement Spec Version" 7 "Requirement Spec Version" 8 "Requirement Spec Version" 9 "Requirement Spec Version" 10 "Requirement Spec Version" 11 "Requirement Spec Version" 12 "Requirement Spec Version" 13 "Requirement Spec Version" 14 "Requirement Spec Version" 15 "Requirement Spec Version" 16 "Requirement Spec Version" 17 "Requirement Spec Version" 18 "Requirement Spec Version" 19 "Requirement Spec Version" 20 "Requirement Spec Version" 21 "Requirement Spec Version" 22 "Requirement Spec Version" 23 "Requirement Spec Version" 24 "Requirement Spec Version" 25 "Requirement Spec Version" 26 "Requirement Spec Version" 27 "Requirement Spec Version" 28 "Requirement Spec Version" 29 "Requirement Spec Version" 30 "Requirement Spec Version" 31 "Requirement Spec Version" ;
VAL_ 992 Warn_PassStOccSta_Copy_0 0 "Off (UnSeated)" 1 "On (Seated)" 2 "Not Used" 3 "Error Indicator" ;
VAL_ 992 Warn_RrLftSBRMATSwSta_Copy_0 0 "Off (UnSeated)" 1 "On (Seated)" 2 "RESERVED" 3 "Error Indicator" ;
VAL_ 992 Warn_RrRhtSBRMATSwSta_Copy_0 0 "Off (UnSeated)" 1 "On (Seated)" 2 "RESERVED" 3 "Error Indicator" ;
VAL_ 992 C_3rdRLSBRMatSw_Copy_0 0 "Off (UnSeated)" 1 "On (Seated)" ;
VAL_ 992 C_3rdRRSBRMatSw_Copy_0 0 "Off (UnSeated)" 1 "On (Seated)" ;
VAL_ 992 C_1stCTRSBRMatSw_Copy_0 0 "Off (UnSeated)" 1 "On (Seated)" ;
VAL_ 992 StrWhlWrmrSwState_Copy_0 0 "Off" 1 "On" 2 "Not Used" 3 "Error Indicator" ;
VAL_ 992 StrWhlWrmrFlModDetail_Copy_0 0 "Off" 1 "OverVoltage" 2 "UnderVoltage" 3 "OverCurrent" 4 "CircuitOpen" 5 "OverLimitTemperature" 6 "LowLimitTemperature" 7 "Reserved" ;
VAL_ 992 FrHtdGlsSwState_Copy_0 0 "Off" 1 "On" 2 "Not Used" 3 "Error Indicator" ;
VAL_ 992 RrGlsHtSwState_Copy_0 0 "Off" 1 "On" 2 "Not Used" 3 "Error Indicator" ;
VAL_ 992 RLChldLkLatchSwState_Copy_0 0 "Unlock" 1 "Lock" 2 "Not Used" 3 "Error Indicator" ;
VAL_ 992 RRChldLkLatchSwState_Copy_0 0 "Unlock" 1 "Lock" 2 "Not Used" 3 "Error Indicator" ;
VAL_ 992 ChildLock_ActnFlSta_Copy_0 0 "OK" 1 "Failed" 2 "Not Used" 3 "Error Indicator" ;
VAL_ 992 DoorLock_LkOutSta_Copy_0 0 "Off" 1 "On" 2 "Not Used" 3 "Error Indicator" ;
VAL_ 992 VSAutoDrLkRetryFailSta_Copy_0 0 "Normal" 1 "Fail" 2 "RESERVED" 3 "RESERVED" ;
VAL_ 992 Trunk_TrnkTlgtOutReleaseSwSta_Co 0 "Off" 1 "On" 2 "Stuck" 3 "Error Indicator" ;
VAL_ 992 Trunk_TrnkInReleaseSwSta_Copy_0 0 "Off" 1 "On" 2 "Stuck" 3 "Error Indicator" ;
VAL_ 992 Trunk_GlvBxTrnkLkSwSta_Copy_0 0 "Off" 1 "On" 2 "Not Used" 3 "Error Indicator" ;
VAL_ 992 Trunk_TrnkTlgtSwSta_Copy_0 0 "Close(Full Lock)" 1 "Open(Not Full Lock)" 2 "Not Used" 3 "Error Indicator" ;
VAL_ 992 Trunk_TlgtFullOpnSwSta_Copy_0 0 "Close(Not Full Open)" 1 "Open(Full Open)" 2 "Not Used" 3 "Error Indicator" ;
VAL_ 992 Trunk_TrnkTlgtReleaseRlySta_Copy 0 "OFF" 1 "ON" 2 "Not Used" 3 "Error Indicator" ;
VAL_ 992 FrtWiper_ParkingSwState 0 "Off" 1 "On" 2 "RESERVED" 3 "RESERVED" ;
VAL_ 992 PDC_TlgtUnLkSta 0 "Lock" 1 "Unlock" 2 "Not Used" 3 "Error Indicator" ;
VAL_ 992 PDC_PSDPwrModeOffSwSta 0 "Off" 1 "On" 2 "Not Used" 3 "Error Indicator" ;
VAL_ 992 PDC_FuelDrOpenSta 0 "Close" 1 "Open" 2 "Not Used" 3 "RESERVED" ;
VAL_ 992 PDC_FD_AlvCnt1Val 0 "0x0x0~0xFF:AlvCntValue" 255 "0x0x0~0xFF:AlvCntValue" ;
VAL_ 992 OBCWakeupDrLock_Copy_0 0 "Default" 1 "Off" 2 "On(DrLock)" 3 "Error Indicator" ;
VAL_ 992 OBCWakeupDrUnlock_Copy_0 0 "Default" 1 "Off" 2 "On(Unlock)" 3 "Error Indicator" ;
VAL_ 992 Trunk_BgtOpnHzrdReq_Copy_0 0 "Off" 1 "On" 2 "Not Used" 3 "Error Indicator" ;
VAL_ 992 Trunk_BgtOpnBzrReq_Copy_0 0 "Off" 1 "On" 2 "Not Used" 3 "Error Indicator" ;
VAL_ 992 IGN3State 0 "Off" 1 "On" 2 "RESERVED" 3 "RESERVED" ;
VAL_ 992 IGN3State_By_BMS 0 "Off" 1 "On" 2 "RESERVED" 3 "RESERVED" ;
VAL_ 992 IGN3State_By_VCMS_HMU 0 "Off" 1 "On" 2 "RESERVED" 3 "RESERVED" ;
VAL_ 992 IGN3State_By_AfterBlow 0 "Off" 1 "On" 2 "RESERVED" 3 "RESERVED" ;
VAL_ 992 IGN3State_By_Bat_Copy_0 0 "Off" 1 "On" 2 "RESERVED" 3 "RESERVED" ;
VAL_ 992 IGN3State_By_VCU_HCU_FCU 0 "Off" 1 "On" 2 "RESERVED" 3 "RESERVED" ;
VAL_ 992 IGN3State_By_HU 0 "Off" 1 "On" 2 "RESERVED" 3 "RESERVED" ;
VAL_ 992 IGN3CutOffState 0 "CutOffNotApplied" 1 "NoRequest" 2 "Normal" 3 "PreWarn" 4 "CutOff" 5 "RESERVED" 6 "RESERVED" 7 "RESERVED" ;
VAL_ 992 SeatBeltSwSta_Drv_Copy_0 0 "Unbelted" 1 "Belted" 2 "Not Supported" 3 "Virgin Mode" ;
VAL_ 992 SeatBeltSwSta_1stCtr_Copy_0 0 "Unbelted" 1 "Belted" 2 "Not Supported" 3 "Virgin Mode" ;
VAL_ 992 SeatBeltSwSta_Asst_Copy_0 0 "Unbelted" 1 "Belted" 2 "Not Supported" 3 "Virgin Mode" ;
VAL_ 992 SeatBeltSwSta_2ndLft_Copy_0 0 "Unbelted" 1 "Belted" 2 "Not Supported" 3 "Virgin Mode" ;
VAL_ 992 SeatBeltSwSta_2ndCtr_Copy_0 0 "Unbelted" 1 "Belted" 2 "Not Supported" 3 "Virgin Mode" ;
VAL_ 992 SeatBeltSwSta_2ndRt_Copy_0 0 "Unbelted" 1 "Belted" 2 "Not Supported" 3 "Virgin Mode" ;
VAL_ 992 SeatBeltSwSta_3rdLft_Copy_0 0 "Unbelted" 1 "Belted" 2 "Not Supported" 3 "Virgin Mode" ;
VAL_ 992 SeatBeltSwSta_3rdCtr_Copy_0 0 "Unbelted" 1 "Belted" 2 "Not Supported" 3 "Virgin Mode" ;
VAL_ 992 SeatBeltSwSta_3rdRt_Copy_0 0 "Unbelted" 1 "Belted" 2 "Not Supported" 3 "Virgin Mode" ;
VAL_ 992 SeatBelt4th_InstallInfo_Copy_0 0 "Virgin Mode" 1 "No Seat" 2 "All Seat" 3 "Left and Right" 4 "RESERVED" 5 "RESERVED" 6 "RESERVED" 7 "RESERVED" ;
VAL_ 992 PDCex_CurtainOpt 0 "No Curtain" 1 "Rear Curtain" 2 "Quarter Glass Curtain" 3 "All Curtain" ;
VAL_ 992 Reprogram_State_PDC2 0 "normal operation" 1 "reprogramming" 2 "RESERVED" 3 "Invalid (default)" ;
VAL_ 992 Warn_RrCTRSBRMATSwSta 0 "Off (Unseated)" 1 "On (Seated)" 2 "Not Used" 3 "Error Indicator" ;
VAL_ 992 C_3rdRCSBRMatSw 0 "Off (UnSeated)" 1 "On (Seated)" ;
VAL_ 992 DriveTypeOption_Copy_0 0 "Left Handle Drive Type" 1 "Right Handle Drive Type" 2 "RESERVED" 3 "Error Indicator" ;
VAL_ 992 AutoLtOpt_Copy_0 0 "Not Applied" 1 "Applied" 2 "Reserved" 3 "Reserved" ;
VAL_ 992 HLmpLoHiOptLtSrcTyp_Copy_0 0 "Not Applied" 1 "2 Light MFR Bulb" 2 "4 Light Bulb" 3 "4 Light Led Ldm" 4 "Bi-Function Bulb" 5 "Bi-Function Led Ldm" 6 "Reserved" 7 "Reserved" ;
VAL_ 992 C_StrgWhlHeatingOpt_Copy_0 0 "Not Applied" 1 "Applied(steering wheel applied)" 2 "RESERVED" 3 "Invalid" ;
VAL_ 992 C_StrgWhlHeatingSWInf_Copy_0 0 "Default" 1 "1step opt(On/Off)" 2 "2step opt(step1,step2,Off)" 3 "Invalid" ;
VAL_ 992 ICU_MtGearPosRSta_Copy_0 0 "Off" 1 "On" 2 "RESERVED" 3 "RESERVED" ;
VAL_ 992 C_AutoLeverManualSW_Copy_0 0 "Not Manual" 1 "Manual" 2 "Manual +" 3 "Manual -" ;
VAL_ 992 Warn_HoodSwMemorySta_Copy_0 0 "No event" 1 "hood_open_close" 2 "RESERVED" 3 "RESERVED" ;
VAL_ 992 Warn_PrkngBrkSwSta_Copy_0 0 "Off" 1 "On" 2 "Not Used" 3 "Error Indicator" ;
VAL_ 992 PrkngBrkNotchSwState_Copy_0 0 "Off" 1 "On" 2 "Reserved" 3 "InvalidState" ;
VAL_ 992 Warn_BrkFldSwSta_Copy_0 0 "Off" 1 "On" 2 "Not Used" 3 "Error Indicator" ;
VAL_ 992 Warn_WshrFldSwSta_Copy_0 0 "Off" 1 "On" 2 "RESERVED" 3 "RESERVED" ;
VAL_ 992 Warn_DrvStBltSwSta_Copy_0 0 "Unbelted" 1 "Belted" 2 "Not Used" 3 "Error Indicator" ;
VAL_ 992 Warn_AsstStBltSwSta_Copy_0 0 "Unbelted" 1 "Belted" 2 "Not Used" 3 "Error Indicator" ;
VAL_ 992 Warn_RrLftStBltSwSta_Copy_0 0 "Unbelted" 1 "Belted" 2 "Not Used" 3 "Error Indicator" ;
VAL_ 992 Warn_RrCtrStBltSwSta_Copy_0 0 "Unbelted" 1 "Belted" 2 "Not Used" 3 "Error Indicator" ;
VAL_ 992 Warn_RrRtStBltSwSta_Copy_0 0 "Unbelted" 1 "Belted" 2 "Not Used" 3 "Error Indicator" ;
VAL_ 992 C_3rdRLSeatBeltSW_Copy_0 0 "Unbelted" 1 "Belted" ;
